VERSION ""

NS_ :

BS_:

BU_: SCM BC1 BC2 ECM PSC ABS Brakes__Drive_Axle_1 EPS IC GPS WCM VCM Seat_Control_1 ISC1 HCU IDT GMRS XM RH AUTON LHC CIM IMU BC3 IC2 EPC1 EPC2 EPC3 EPC4 BMC1 BMC2 APU2 APU1 SRVTOOL RHC RCM

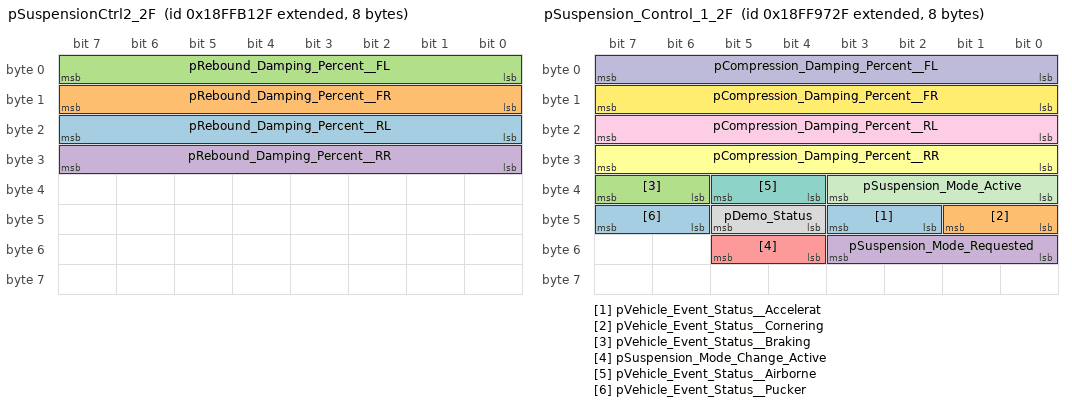
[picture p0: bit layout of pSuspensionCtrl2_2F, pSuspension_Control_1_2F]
BO_ 2566893871 pSuspensionCtrl2_2F: 8 SCM
 SG_ pRebound_Damping_Percent__RL : 16|8@1+ (0.4,0) [0|101.4] "%" Vector__XXX
 SG_ pRebound_Damping_Percent__FR : 8|8@1+ (0.4,0) [0|101.4] "%" Vector__XXX
 SG_ pRebound_Damping_Percent__FL : 0|8@1+ (0.4,0) [0|101.4] "%" Vector__XXX
 SG_ pRebound_Damping_Percent__RR : 24|8@1+ (0.4,0) [0|101.4] "%" Vector__XXX

BO_ 2566887215 pSuspension_Control_1_2F: 8 SCM
 SG_ pVehicle_Event_Status__Accelerat : 42|2@1+ (1,0) [0|3] "state" Vector__XXX
 SG_ pVehicle_Event_Status__Cornering : 40|2@1+ (1,0) [0|3] "state" Vector__XXX
 SG_ pVehicle_Event_Status__Braking : 38|2@1+ (1,0) [0|3] "state" Vector__XXX
 SG_ pSuspension_Mode_Requested : 48|4@1+ (1,0) [0|15] "state" Vector__XXX
 SG_ pSuspension_Mode_Change_Active : 52|2@1+ (1,0) [0|3] "state" Vector__XXX
 SG_ pCompression_Damping_Percent__RR : 24|8@1+ (0.4,0) [0|101.4] "%" Vector__XXX
 SG_ pVehicle_Event_Status__Airborne : 36|2@1+ (1,0) [0|3] "state" Vector__XXX
 SG_ pDemo_Status : 44|2@1+ (1,0) [0|3] "state" Vector__XXX
 SG_ pCompression_Damping_Percent__RL : 16|8@1+ (0.4,0) [0|101.4] "%" Vector__XXX
 SG_ pCompression_Damping_Percent__FL : 0|8@1+ (0.4,0) [0|101.4] "%" Vector__XXX
 SG_ pSuspension_Mode_Active : 32|4@1+ (1,0) [0|15] "state" Vector__XXX
 SG_ pCompression_Damping_Percent__FR : 8|8@1+ (0.4,0) [0|101.4] "%" Vector__XXX
 SG_ pVehicle_Event_Status__Pucker : 46|2@1+ (1,0) [0|3] "state" Vector__XXX

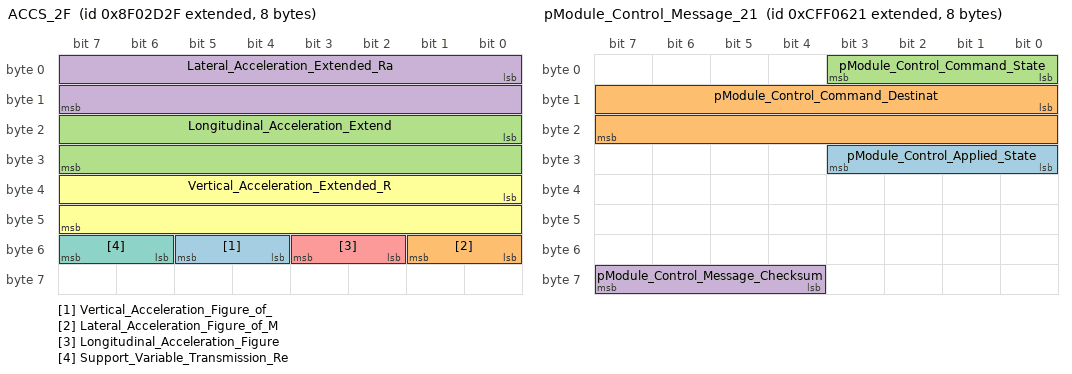
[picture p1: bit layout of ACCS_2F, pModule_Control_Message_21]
BO_ 2297441583 ACCS_2F: 8 SCM
 SG_ Vertical_Acceleration_Figure_of_ : 52|2@1+ (1,0) [0|3] "bit" Vector__XXX
 SG_ Lateral_Acceleration_Figure_of_M : 48|2@1+ (1,0) [0|3] "bit" Vector__XXX
 SG_ Longitudinal_Acceleration_Extend : 16|16@1+ (0.01,-320) [-320|974.36] "m/s2" Vector__XXX
 SG_ Lateral_Acceleration_Extended_Ra : 0|16@1+ (0.01,-320) [-320|974.36] "m/s2" Vector__XXX
 SG_ Longitudinal_Acceleration_Figure : 50|2@1+ (1,0) [0|3] "bit" Vector__XXX
 SG_ Vertical_Acceleration_Extended_R : 32|16@1+ (0.01,-320) [-320|974.36] "m/s2" Vector__XXX
 SG_ Support_Variable_Transmission_Re : 54|2@1+ (1,0) [0|3] "bit" Vector__XXX

BO_ 2365531183 pVMC_2F: 8 SCM
 SG_ pEPSReqMod : 8|8@1+ (1,0) [0|255] "state" Vector__XXX

BO_ 2633984545 pDSS_21: 8 BC1
 SG_ pHeated_Grip_Enable : 48|2@1+ (1,0) [0|3] "state" Vector__XXX
 SG_ pUser_PIN_Access_Status : 26|2@1+ (1,0) [0|3] "state" Vector__XXX
 SG_ pActive_Descent_Control_ADC_Stat : 0|2@1+ (1,0) [0|3] "state" Vector__XXX
 SG_ pCruise_Control_Set_Status : 24|2@1+ (1,0) [0|3] "state" Vector__XXX
 SG_ pTether_Switch_Status : 46|2@1+ (1,0) [0|3] "state" Vector__XXX
 SG_ pHigh_Beam_Indicator_Status : 8|2@1+ (1,0) [0|3] "state" Vector__XXX
 SG_ pLow_Fuel_Indicator_Status : 10|2@1+ (1,0) [0|3] "state" Vector__XXX
 SG_ pHeated_Grips_Percentage : 16|8@1+ (0.4,0) [0|101.4] "%" Vector__XXX
 SG_ pSide_Stand_Status : 36|2@1+ (1,0) [0|3] "state" Vector__XXX
 SG_ pTurf_Mode_Requested : 28|2@1+ (1,0) [0|3] "state" Vector__XXX
 SG_ pEngine_Idle_Shutdown_Timer : 54|10@1+ (1,0) [0|1023] "state" Vector__XXX
 SG_ Operator_Not_in_Operating_Statio : 38|2@1+ (1,0) [0|3] "state" Vector__XXX
 SG_ pAWD_Mode_Requested : 32|2@1+ (1,0) [0|3] "state" Vector__XXX
 SG_ pHeated_Grips_Up_Switch_Status : 50|2@1+ (1,0) [0|3] "state" Vector__XXX
 SG_ pTreadle_Neutral_Status : 2|2@1+ (1,0) [0|3] "state" Vector__XXX
 SG_ pHeated_Grips_Down_Switch_Status : 52|2@1+ (1,0) [0|3] "state" Vector__XXX
 SG_ pPark_Brake_Indicator_Status : 40|3@1+ (1,0) [0|7] "state" Vector__XXX
 SG_ pRWD_Mode_Requested : 30|2@1+ (1,0) [0|3] "state" Vector__XXX
 SG_ pSeat_Belt_Indicator_Status : 12|3@1+ (1,0) [0|7] "state" Vector__XXX
 SG_ pSecurity_Light_Immobilizer_Stat : 6|2@1+ (1,0) [0|3] "state" Vector__XXX
 SG_ ECU_Security_Status : 43|3@1+ (1,0) [0|7] "state" Vector__XXX
 SG_ pActive_Decent_Control_ADC_Mode_ : 34|2@1+ (1,0) [0|3] "state" Vector__XXX
 SG_ pTreadle_Reverse_Status : 4|2@1+ (1,0) [0|3] "state" Vector__XXX

BO_ 2349465377 SRASI_21: 8 BC1
 SG_ Static_Roll_Angle : 0|8@1+ (1,-125) [-125|380] "deg" Vector__XXX

BO_ 2365523489 pModule_Control_Message_21: 8 BC1
 SG_ pModule_Control_Applied_State : 24|4@1+ (1,0) [0|15] "state" Vector__XXX
 SG_ pModule_Control_Command_Destinat : 8|16@1+ (1,0) [0|65535] "count" Vector__XXX
 SG_ pModule_Control_Command_State : 0|4@1+ (1,0) [0|15] "state" Vector__XXX
 SG_ pModule_Control_Message_Checksum : 60|4@1+ (1,0) [0|15] "bit" Vector__XXX

BO_ 2633984656 pDSS_90: 8 BC2
 SG_ pHeated_Grip_Enable : 48|2@1+ (1,0) [0|3] "state" Vector__XXX
 SG_ pUser_PIN_Access_Status : 26|2@1+ (1,0) [0|3] "state" Vector__XXX
 SG_ pActive_Descent_Control_ADC_Stat : 0|2@1+ (1,0) [0|3] "state" Vector__XXX
 SG_ pCruise_Control_Set_Status : 24|2@1+ (1,0) [0|3] "state" Vector__XXX
 SG_ pTether_Switch_Status : 46|2@1+ (1,0) [0|3] "state" Vector__XXX
 SG_ pHigh_Beam_Indicator_Status : 8|2@1+ (1,0) [0|3] "state" Vector__XXX
 SG_ pLow_Fuel_Indicator_Status : 10|2@1+ (1,0) [0|3] "state" Vector__XXX
 SG_ pHeated_Grips_Percentage : 16|8@1+ (0.4,0) [0|101.4] "%" Vector__XXX
 SG_ pSide_Stand_Status : 36|2@1+ (1,0) [0|3] "state" Vector__XXX
 SG_ pTurf_Mode_Requested : 28|2@1+ (1,0) [0|3] "state" Vector__XXX
 SG_ pEngine_Idle_Shutdown_Timer : 54|10@1+ (1,0) [0|1023] "state" Vector__XXX
 SG_ Operator_Not_in_Operating_Statio : 38|2@1+ (1,0) [0|3] "state" Vector__XXX
 SG_ pAWD_Mode_Requested : 32|2@1+ (1,0) [0|3] "state" Vector__XXX
 SG_ pHeated_Grips_Up_Switch_Status : 50|2@1+ (1,0) [0|3] "state" Vector__XXX
 SG_ pTreadle_Neutral_Status : 2|2@1+ (1,0) [0|3] "state" Vector__XXX
 SG_ pHeated_Grips_Down_Switch_Status : 52|2@1+ (1,0) [0|3] "state" Vector__XXX
 SG_ pPark_Brake_Indicator_Status : 40|3@1+ (1,0) [0|7] "state" Vector__XXX
 SG_ pRWD_Mode_Requested : 30|2@1+ (1,0) [0|3] "state" Vector__XXX
 SG_ pSeat_Belt_Indicator_Status : 12|3@1+ (1,0) [0|7] "state" Vector__XXX
 SG_ pSecurity_Light_Immobilizer_Stat : 6|2@1+ (1,0) [0|3] "state" Vector__XXX
 SG_ ECU_Security_Status : 43|3@1+ (1,0) [0|7] "state" Vector__XXX
 SG_ pActive_Decent_Control_ADC_Mode_ : 34|2@1+ (1,0) [0|3] "state" Vector__XXX
 SG_ pTreadle_Reverse_Status : 4|2@1+ (1,0) [0|3] "state" Vector__XXX

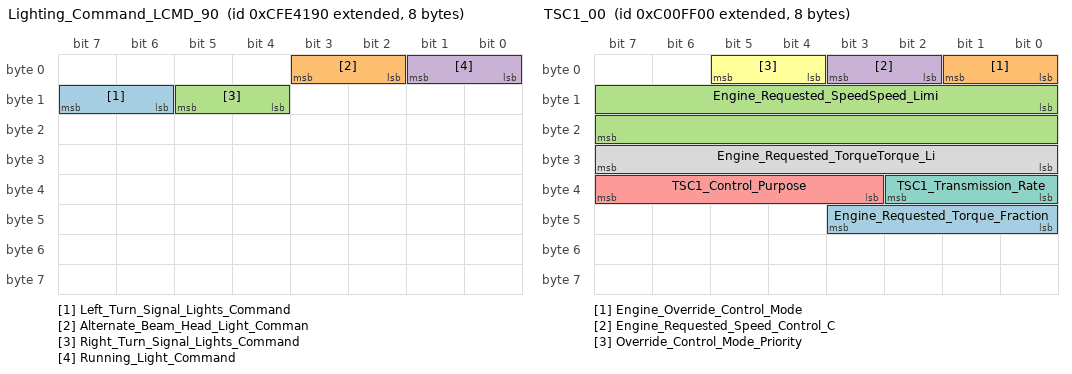
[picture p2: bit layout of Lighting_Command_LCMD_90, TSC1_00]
BO_ 2365473168 Lighting_Command_LCMD_90: 8 BC2
 SG_ Left_Turn_Signal_Lights_Command : 14|2@1+ (1,0) [0|3] "bit" Vector__XXX
 SG_ Alternate_Beam_Head_Light_Comman : 2|2@1+ (1,0) [0|3] "bit" Vector__XXX
 SG_ Right_Turn_Signal_Lights_Command : 12|2@1+ (1,0) [0|3] "bit" Vector__XXX
 SG_ Running_Light_Command : 0|2@1+ (1,0) [0|3] "bit" Vector__XXX

BO_ 2566860065 pISM_21: 8 BC1
 SG_ pSpecial_Msg_12 : 22|2@1+ (1,0) [0|3] "state" Vector__XXX
 SG_ pSpecial_Msg_28 : 54|2@1+ (1,0) [0|3] "state" Vector__XXX
 SG_ pSpecial_Msg_11 : 20|2@1+ (1,0) [0|3] "state" Vector__XXX
 SG_ pSpecial_Msg_26 : 50|2@1+ (1,0) [0|3] "state" Vector__XXX
 SG_ pSpecial_Msg_24 : 46|2@1+ (1,0) [0|3] "state" Vector__XXX
 SG_ pSpecial_Msg_21 : 40|2@1+ (1,0) [0|3] "state" Vector__XXX
 SG_ pSpecial_Msg_18 : 34|2@1+ (1,0) [0|3] "state" Vector__XXX
 SG_ pSpecial_Msg_19 : 36|2@1+ (1,0) [0|3] "state" Vector__XXX
 SG_ pSpecial_Msg_1_Riding_with_Brake : 0|2@1+ (1,0) [0|3] "state" Vector__XXX
 SG_ pSpecial_Msg_2_Regulator_Overhea : 2|2@1+ (1,0) [0|3] "state" Vector__XXX
 SG_ pSpecial_Msg_3_Regulator_Overhea : 4|2@1+ (1,0) [0|3] "state" Vector__XXX
 SG_ pSpecial_Msg_4_Regulator_Overhea : 6|2@1+ (1,0) [0|3] "state" Vector__XXX
 SG_ pSpecial_Msg_5_Engine_Warmup_Com : 8|2@1+ (1,0) [0|3] "state" Vector__XXX
 SG_ pSpecial_Msg_6_Engine_Knock__Mod : 10|2@1+ (1,0) [0|3] "state" Vector__XXX
 SG_ pSpecial_Msg_8_Low_Coolant_Warni : 14|2@1+ (1,0) [0|3] "state" Vector__XXX
 SG_ pSpecial_Msg_7_Engine_Knock__Mos : 12|2@1+ (1,0) [0|3] "state" Vector__XXX
 SG_ pSpecial_Msg_9_Transmission_Temp : 16|2@1+ (1,0) [0|3] "state" Vector__XXX
 SG_ pSpecial_Msg_10_Reverse_Speed_Li : 18|2@1+ (1,0) [0|3] "state" Vector__XXX
 SG_ pSpecial_Msg_13_Belt_Burn_Warnin : 24|2@1+ (1,0) [0|3] "state" Vector__XXX
 SG_ pSpecial_Msg_14_Park_Brake_Warni : 26|2@1+ (1,0) [0|3] "state" Vector__XXX
 SG_ pSpecial_Msg_15_TCM_Comm_Loss : 28|2@1+ (1,0) [0|3] "state" Vector__XXX
 SG_ pSpecial_Msg_16_TCM_Pump_Priming : 30|2@1+ (1,0) [0|3] "state" Vector__XXX
 SG_ pSpecial_Msg_17_Request_User_to_ : 32|2@1+ (1,0) [0|3] "state" Vector__XXX
 SG_ pSpecial_MSG_20_Fuel_Door_Open_E : 38|2@1+ (1,0) [0|3] "state" Vector__XXX
 SG_ pSpecial_MSG_22_Clutch_Overtemp : 42|2@1+ (1,0) [0|3] "state" Vector__XXX
 SG_ pSpecial_MSG_23_Exhaust_Valve_Ch : 44|2@1+ (1,0) [0|3] "state" Vector__XXX
 SG_ pSpecial_MSG_25_Engine_Idle_Shut : 48|2@1+ (1,0) [0|3] "state" Vector__XXX
 SG_ pSpecial_MSG_27_Overboost_Condit : 52|2@1+ (1,0) [0|3] "state" Vector__XXX
 SG_ pSpecial_Msg_31_Engine_Tip_Over_ : 60|2@1+ (1,0) [0|3] "state" Vector__XXX
 SG_ pSpecial_Msg_32_Engine_Tip_Over_ : 62|2@1+ (1,0) [0|3] "state" Vector__XXX

BO_ 2348875520 TSC1_00: 8 ECM
 SG_ Engine_Requested_Torque_Fraction : 40|4@1+ (0.125,0) [0|1] "%" Vector__XXX
 SG_ Engine_Override_Control_Mode : 0|2@1+ (1,0) [0|3] "bit" Vector__XXX
 SG_ Engine_Requested_SpeedSpeed_Limi : 8|16@1+ (0.125,0) [0|8191] "rpm" Vector__XXX
 SG_ Engine_Requested_Speed_Control_C : 2|2@1+ (1,0) [0|3] "bit" Vector__XXX
 SG_ TSC1_Control_Purpose : 35|5@1+ (1,0) [0|31] "bit" Vector__XXX
 SG_ Override_Control_Mode_Priority : 4|2@1+ (1,0) [0|3] "bit" Vector__XXX
 SG_ TSC1_Transmission_Rate : 32|3@1+ (1,0) [0|7] "bit" Vector__XXX
 SG_ Engine_Requested_TorqueTorque_Li : 24|8@1+ (1,-125) [-125|380] "%" Vector__XXX

BO_ 2364539648 EEC2_00: 8 ECM
 SG_ Accelerator_Pedal_Position_1 : 8|8@1+ (0.4,0) [0|101.4] "%" Vector__XXX

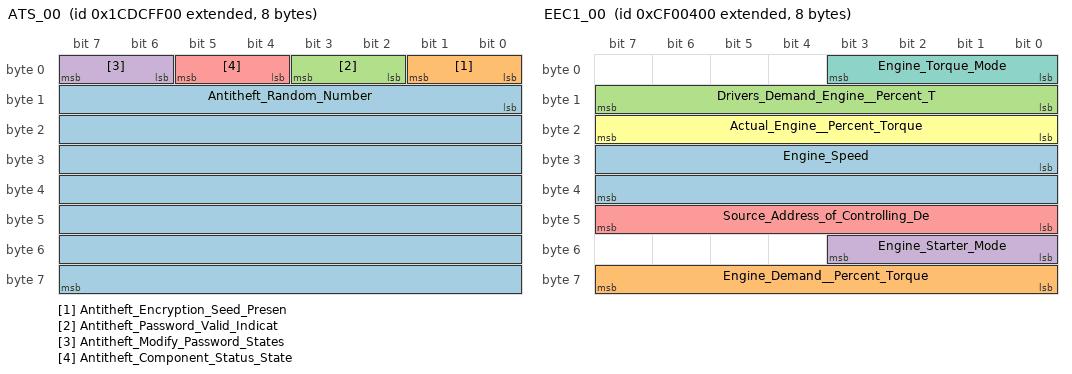
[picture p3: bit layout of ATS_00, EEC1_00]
BO_ 2631728896 ATS_00: 8 ECM
 SG_ Antitheft_Random_Number : 8|56@1+ (0,0) [0|-1] "ASCII" Vector__XXX
 SG_ Antitheft_Encryption_Seed_Presen : 0|2@1+ (1,0) [0|3] "bit" Vector__XXX
 SG_ Antitheft_Password_Valid_Indicat : 2|2@1+ (1,0) [0|3] "bit" Vector__XXX
 SG_ Antitheft_Modify_Password_States : 6|2@1+ (1,0) [0|3] "bit" Vector__XXX
 SG_ Antitheft_Component_Status_State : 4|2@1+ (1,0) [0|3] "bit" Vector__XXX

BO_ 2364539904 EEC1_00: 8 ECM
 SG_ Engine_Speed : 24|16@1+ (0.125,0) [0|8191] "rpm" Vector__XXX
 SG_ Engine_Demand__Percent_Torque : 56|8@1+ (1,-125) [-125|380] "%" Vector__XXX
 SG_ Drivers_Demand_Engine__Percent_T : 8|8@1+ (1,-125) [-125|380] "%" Vector__XXX
 SG_ Engine_Starter_Mode : 48|4@1+ (1,0) [0|15] "bit" Vector__XXX
 SG_ Source_Address_of_Controlling_De : 40|8@1+ (1,0) [0|255] "SA" Vector__XXX
 SG_ Actual_Engine__Percent_Torque : 16|8@1+ (1,-125) [-125|380] "%" Vector__XXX
 SG_ Engine_Torque_Mode : 0|4@1+ (1,0) [0|15] "bit" Vector__XXX

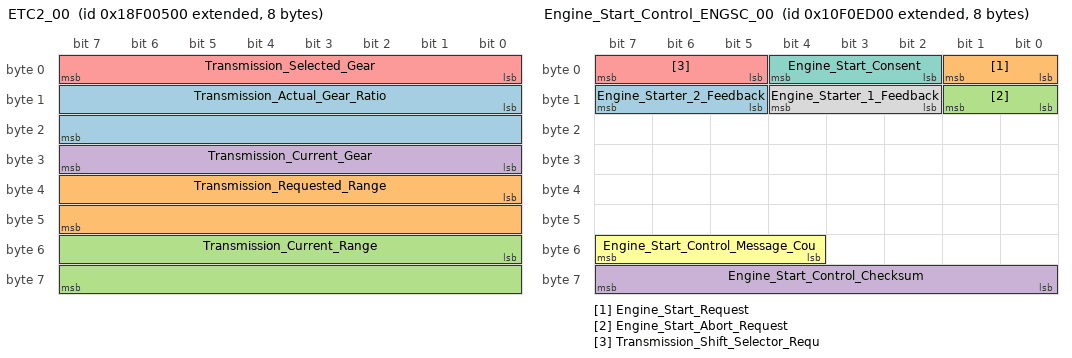
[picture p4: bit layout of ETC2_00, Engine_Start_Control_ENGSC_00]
BO_ 2565866752 ETC2_00: 8 ECM
 SG_ Transmission_Actual_Gear_Ratio : 8|16@1+ (0.001,0) [0|64.536] "Ratio" Vector__XXX
 SG_ Transmission_Requested_Range : 32|16@1+ (0,0) [0|-1] "ASCII" Vector__XXX
 SG_ Transmission_Current_Range : 48|16@1+ (0,0) [0|-1] "ASCII" Vector__XXX
 SG_ Transmission_Current_Gear : 24|8@1+ (1,-125) [-125|380] "gear_value" Vector__XXX
 SG_ Transmission_Selected_Gear : 0|8@1+ (1,-125) [-125|380] "gear_value" Vector__XXX

BO_ 2431708416 Engine_Start_Control_ENGSC_00: 8 ECM
 SG_ Engine_Starter_2_Feedback : 13|3@1+ (1,0) [0|7] "bit" Vector__XXX
 SG_ Engine_Start_Request : 0|2@1+ (1,0) [0|3] "bit" Vector__XXX
 SG_ Engine_Start_Abort_Request : 8|2@1+ (1,0) [0|3] "bit" Vector__XXX
 SG_ Engine_Start_Control_Checksum : 56|8@1+ (1,0) [0|255] "count" Vector__XXX
 SG_ Transmission_Shift_Selector_Requ : 5|3@1+ (1,0) [0|7] "bit" Vector__XXX
 SG_ Engine_Start_Control_Message_Cou : 52|4@1+ (1,0) [0|15] "bit" Vector__XXX
 SG_ Engine_Start_Consent : 2|3@1+ (1,0) [0|7] "bit" Vector__XXX
 SG_ Engine_Starter_1_Feedback : 10|3@1+ (1,0) [0|7] "bit" Vector__XXX

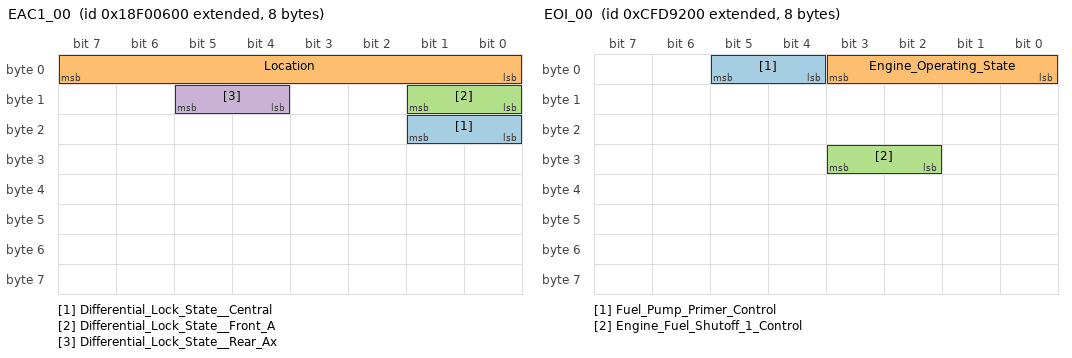
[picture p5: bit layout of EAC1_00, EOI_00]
BO_ 2565867008 EAC1_00: 8 ECM
 SG_ Differential_Lock_State__Central : 16|2@1+ (1,0) [0|3] "bit" Vector__XXX
 SG_ Location : 0|8@1+ (1,0) [0|255] "bit" Vector__XXX
 SG_ Differential_Lock_State__Front_A : 8|2@1+ (1,0) [0|3] "bit" Vector__XXX
 SG_ Differential_Lock_State__Rear_Ax : 12|2@1+ (1,0) [0|3] "bit" Vector__XXX

BO_ 2365428224 EOI_00: 8 ECM
 SG_ Fuel_Pump_Primer_Control : 4|2@1+ (1,0) [0|3] "bit" Vector__XXX
 SG_ Engine_Operating_State : 0|4@1+ (1,0) [0|15] "bit" Vector__XXX
 SG_ Engine_Fuel_Shutoff_1_Control : 26|2@1+ (1,0) [0|3] "bit" Vector__XXX

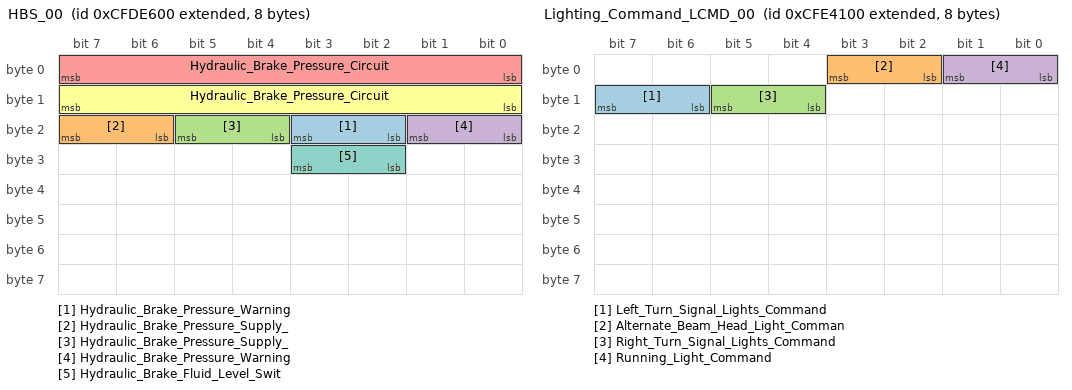
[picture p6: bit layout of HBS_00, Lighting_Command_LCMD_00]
BO_ 2365449728 HBS_00: 8 ECM
 SG_ Hydraulic_Brake_Pressure_Warning : 18|2@1+ (1,0) [0|3] "bit" Vector__XXX
 SG_ Hydraulic_Brake_Pressure_Supply_ : 22|2@1+ (1,0) [0|3] "bit" Vector__XXX
 SG_ Hydraulic_Brake_Pressure_Supply_ : 20|2@1+ (1,0) [0|3] "bit" Vector__XXX
 SG_ Hydraulic_Brake_Pressure_Warning : 16|2@1+ (1,0) [0|3] "bit" Vector__XXX
 SG_ Hydraulic_Brake_Pressure_Circuit : 0|8@1+ (100,0) [0|25599] "kPa" Vector__XXX
 SG_ Hydraulic_Brake_Pressure_Circuit : 8|8@1+ (100,0) [0|25599] "kPa" Vector__XXX
 SG_ Hydraulic_Brake_Fluid_Level_Swit : 26|2@1+ (1,0) [0|3] "bit" Vector__XXX

BO_ 2633883392 FWD_00: 8 ECM
 SG_ Front_Wheel_Drive_Actuator_Statu : 0|2@1+ (1,0) [0|3] "bit" Vector__XXX

BO_ 2566768128 CSA_00: 8 ECM
 SG_ Engine_Cold_Start_Fuel_Igniter_R : 26|2@1+ (1,0) [0|3] "bit" Vector__XXX
 SG_ Engine_Cold_Start_Fuel_Igniter_R : 24|2@1+ (1,0) [0|3] "bit" Vector__XXX

BO_ 2566832384 VDHR_00: 8 ECM
 SG_ Total_Vehicle_Distance_High_Reso : 0|32@1+ (5,0) [0|21474836479] "m" Vector__XXX
 SG_ Trip_Distance_High_Resolution : 0|32@1+ (5,0) [0|21474836479] "m" Vector__XXX

BO_ 2566834944 DM2_00: 42 ECM
 SG_ Protect_Lamp_Status : 0|2@1+ (1,0) [0|3] "" Vector__XXX
 SG_ Amber_Warning_Lamp_Status : 2|2@1+ (1,0) [0|3] "" Vector__XXX
 SG_ Red_Stop_Lamp_Status : 4|2@1+ (1,0) [0|3] "" Vector__XXX
 SG_ Malfunction_Indicator_Lamp_Statu : 6|2@1+ (1,0) [0|3] "" Vector__XXX
 SG_ Flash_Protect_Lamp : 8|2@1+ (1,0) [0|3] "" Vector__XXX
 SG_ Flash_Amber_Warning_Lamp_AWL : 10|2@1+ (1,0) [0|3] "" Vector__XXX
 SG_ Flash_Red_Stop_Lamp_RSL : 12|2@1+ (1,0) [0|3] "" Vector__XXX
 SG_ Flash_Malfunction_Indicator_Lamp : 14|2@1+ (1,0) [0|3] "" Vector__XXX
 SG_ DTC_1 : 16|32@1+ (1,0) [0|4294967295] "value" Vector__XXX
 SG_ DTC_2 : 48|32@1+ (1,0) [0|4294967295] "value" Vector__XXX
 SG_ DTC_3 : 80|32@1+ (1,0) [0|4294967295] "value" Vector__XXX
 SG_ DTC_4 : 112|32@1+ (1,0) [0|4294967295] "value" Vector__XXX
 SG_ DTC_5 : 144|32@1+ (1,0) [0|4294967295] "value" Vector__XXX
 SG_ DTC_6 : 176|32@1+ (1,0) [0|4294967295] "value" Vector__XXX
 SG_ DTC_7 : 208|32@1+ (1,0) [0|4294967295] "value" Vector__XXX
 SG_ DTC_8 : 240|32@1+ (1,0) [0|4294967295] "value" Vector__XXX
 SG_ DTC_9 : 272|32@1+ (1,0) [0|4294967295] "value" Vector__XXX
 SG_ DTC_10 : 304|32@1+ (1,0) [0|4294967295] "value" Vector__XXX

BO_ 2566819840 Engine_Torque_History_00: 0 ECM
 SG_ Engine_Peak_Torque_1 : 24|16@1+ (1,0) [0|65535] "Nm" Vector__XXX

BO_ 2566834688 DM1_00: 42 ECM
 SG_ Flash_Malfunction_Indicator_Lamp : 14|2@1+ (1,0) [0|3] "" Vector__XXX
 SG_ Malfunction_Indicator_Lamp_Statu : 6|2@1+ (1,0) [0|3] "" Vector__XXX
 SG_ Red_Stop_Lamp_Status : 4|2@1+ (1,0) [0|3] "" Vector__XXX
 SG_ Amber_Warning_Lamp_Status : 2|2@1+ (1,0) [0|3] "" Vector__XXX
 SG_ Flash_Red_Stop_Lamp_RSL : 12|2@1+ (1,0) [0|3] "" Vector__XXX
 SG_ Flash_Amber_Warning_Lamp_AWL : 10|2@1+ (1,0) [0|3] "" Vector__XXX
 SG_ Flash_Protect_Lamp : 8|2@1+ (1,0) [0|3] "" Vector__XXX
 SG_ Protect_Lamp_Status : 0|2@1+ (1,0) [0|3] "" Vector__XXX
 SG_ DTC_1 : 16|32@1+ (1,0) [0|4294967295] "value" Vector__XXX
 SG_ DTC_2 : 48|32@1+ (1,0) [0|4294967295] "value" Vector__XXX
 SG_ DTC_3 : 80|32@1+ (1,0) [0|4294967295] "value" Vector__XXX
 SG_ DTC_4 : 112|32@1+ (1,0) [0|4294967295] "value" Vector__XXX
 SG_ DTC_5 : 144|32@1+ (1,0) [0|4294967295] "value" Vector__XXX
 SG_ DTC_6 : 176|32@1+ (1,0) [0|4294967295] "value" Vector__XXX
 SG_ DTC_7 : 208|32@1+ (1,0) [0|4294967295] "value" Vector__XXX
 SG_ DTC_8 : 240|32@1+ (1,0) [0|4294967295] "value" Vector__XXX
 SG_ DTC_9 : 272|32@1+ (1,0) [0|4294967295] "value" Vector__XXX
 SG_ DTC_10 : 304|32@1+ (1,0) [0|4294967295] "value" Vector__XXX

BO_ 2633929216 Engine_Information_1_00: 0 ECM
 SG_ Engine_Fuel_Rack_Position : 24|8@1+ (0.4,0) [0|101.4] "%" Vector__XXX

BO_ 2566841344 SHUTDN_00: 8 ECM
 SG_ Engine_Wait_to_Start_Lamp : 24|2@1+ (1,0) [0|3] "bit" Vector__XXX

BO_ 2566825472 Intake_Manifold_Information_1_00: 8 ECM
 SG_ Engine_Turbocharger_1_Boost_Pres : 0|16@1+ (0.125,0) [0|8191] "kPa" Vector__XXX

BO_ 2365473024 Lighting_Command_LCMD_00: 8 ECM
 SG_ Left_Turn_Signal_Lights_Command : 14|2@1+ (1,0) [0|3] "bit" Vector__XXX
 SG_ Alternate_Beam_Head_Light_Comman : 2|2@1+ (1,0) [0|3] "bit" Vector__XXX
 SG_ Right_Turn_Signal_Lights_Command : 12|2@1+ (1,0) [0|3] "bit" Vector__XXX
 SG_ Running_Light_Command : 0|2@1+ (1,0) [0|3] "bit" Vector__XXX

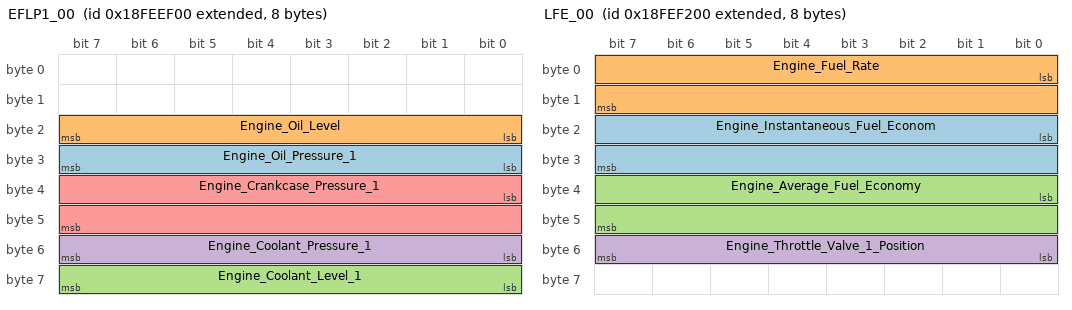
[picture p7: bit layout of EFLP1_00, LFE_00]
BO_ 2566844160 EFLP1_00: 8 ECM
 SG_ Engine_Oil_Pressure_1 : 24|8@1+ (4,0) [0|1023] "kPa" Vector__XXX
 SG_ Engine_Oil_Level : 16|8@1+ (0.4,0) [0|101.4] "%" Vector__XXX
 SG_ Engine_Coolant_Level_1 : 56|8@1+ (0.4,0) [0|101.4] "%" Vector__XXX
 SG_ Engine_Coolant_Pressure_1 : 48|8@1+ (2,0) [0|511] "kPa" Vector__XXX
 SG_ Engine_Crankcase_Pressure_1 : 32|16@1+ (0.0078125,-250) [-250|761] "kPa" Vector__XXX

BO_ 2566841600 HOURS_00: 8 ECM
 SG_ Engine_Total_Hours_of_Operation : 0|32@1+ (0.05,0) [0|214748363.8] "h" Vector__XXX
 SG_ Engine_Total_Revolutions : 32|32@1+ (1000,0) [0|4294967295999] "r" Vector__XXX

BO_ 2566844672 CCVS1_00: 8 ECM
 SG_ Cruise_Control_Set_Speed : 40|8@1+ (1,0) [0|255] "km/h" Vector__XXX
 SG_ Cruise_Control_Active : 24|2@1+ (1,0) [0|3] "bit" Vector__XXX
 SG_ Clutch_Switch : 30|2@1+ (1,0) [0|3] "bit" Vector__XXX
 SG_ Brake_Switch : 28|2@1+ (1,0) [0|3] "bit" Vector__XXX
 SG_ pCC_Message_Counter : 52|4@1+ (1,0) [0|15] "count" Vector__XXX
 SG_ Cruise_Control_Pause_Switch : 4|2@1+ (1,0) [0|3] "bit" Vector__XXX
 SG_ Cruise_Control_Set_Switch : 32|2@1+ (1,0) [0|3] "bit" Vector__XXX
 SG_ Two_Speed_Axle_Switch : 0|2@1+ (1,0) [0|3] "bit" Vector__XXX
 SG_ Cruise_Control_Enable_Switch : 26|2@1+ (1,0) [0|3] "bit" Vector__XXX
 SG_ pOdometer_Drive_Bit : 6|2@1+ (1,0) [0|3] "state" Vector__XXX
 SG_ pCC_Checksum : 56|8@1+ (1,0) [0|255] "" Vector__XXX
 SG_ WheelBased_Vehicle_Speed : 8|16@1+ (0.00390625,0) [0|255] "km/h" Vector__XXX
 SG_ Cruise_Control_Resume_Switch : 36|2@1+ (1,0) [0|3] "bit" Vector__XXX
 SG_ Cruise_Control_Accelerate_Switch : 38|2@1+ (1,0) [0|3] "bit" Vector__XXX
 SG_ pCruise_Enable_Status : 48|4@1+ (1,0) [0|15] "state" Vector__XXX
 SG_ Parking_Brake_Switch : 2|2@1+ (1,0) [0|3] "bit" Vector__XXX
 SG_ Cruise_Control_Coast_Decelerate_ : 34|2@1+ (1,0) [0|3] "bit" Vector__XXX

BO_ 2566844928 LFE_00: 8 ECM
 SG_ Engine_Instantaneous_Fuel_Econom : 16|16@1+ (0.001953125,0) [0|127] "km/L" Vector__XXX
 SG_ Engine_Fuel_Rate : 0|16@1+ (0.05,0) [0|3275.8] "l/h" Vector__XXX
 SG_ Engine_Average_Fuel_Economy : 32|16@1+ (0.001953125,0) [0|127] "km/L" Vector__XXX
 SG_ Engine_Throttle_Valve_1_Position : 48|8@1+ (0.4,0) [0|101.4] "%" Vector__XXX

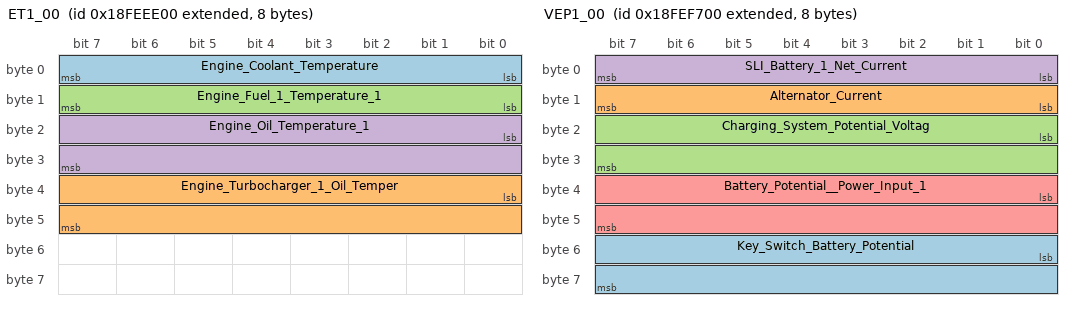
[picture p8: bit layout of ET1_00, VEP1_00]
BO_ 2566843904 ET1_00: 8 ECM
 SG_ Engine_Coolant_Temperature : 0|8@1+ (1,-40) [-40|295] "deg C" Vector__XXX
 SG_ Engine_Turbocharger_1_Oil_Temper : 32|16@1+ (0.03125,-273) [-273|2320] "deg C" Vector__XXX
 SG_ Engine_Fuel_1_Temperature_1 : 8|8@1+ (1,-40) [-40|295] "deg C" Vector__XXX
 SG_ Engine_Oil_Temperature_1 : 16|16@1+ (0.03125,-273) [-273|2320] "deg C" Vector__XXX

BO_ 2566846208 VEP1_00: 8 ECM
 SG_ Key_Switch_Battery_Potential : 48|16@1+ (0.05,0) [0|3275.8] "V" Vector__XXX
 SG_ Alternator_Current : 8|8@1+ (1,0) [0|255] "A" Vector__XXX
 SG_ Charging_System_Potential_Voltag : 16|16@1+ (0.05,0) [0|3275.8] "V" Vector__XXX
 SG_ SLI_Battery_1_Net_Current : 0|8@1+ (1,-125) [-125|380] "A" Vector__XXX
 SG_ Battery_Potential__Power_Input_1 : 32|16@1+ (0.05,0) [0|3275.8] "V" Vector__XXX

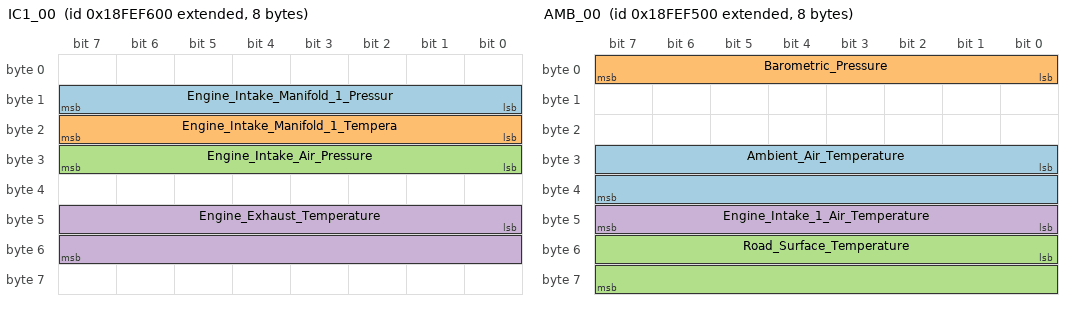
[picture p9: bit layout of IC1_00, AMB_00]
BO_ 2566845952 IC1_00: 8 ECM
 SG_ Engine_Intake_Manifold_1_Pressur : 8|8@1+ (2,0) [0|511] "kPa" Vector__XXX
 SG_ Engine_Intake_Manifold_1_Tempera : 16|8@1+ (1,-40) [-40|295] "deg C" Vector__XXX
 SG_ Engine_Intake_Air_Pressure : 24|8@1+ (2,0) [0|511] "kPa" Vector__XXX
 SG_ Engine_Exhaust_Temperature : 40|16@1+ (0.03125,-273) [-273|2320] "deg C" Vector__XXX

BO_ 2566847488 DD_00: 8 ECM
 SG_ Fuel_Level_1 : 8|8@1+ (0.4,0) [0|101.4] "%" Vector__XXX

BO_ 2566845696 AMB_00: 8 ECM
 SG_ Ambient_Air_Temperature : 24|16@1+ (0.03125,-273) [-273|2320] "deg C" Vector__XXX
 SG_ Barometric_Pressure : 0|8@1+ (0.5,0) [0|127] "kPa" Vector__XXX
 SG_ Road_Surface_Temperature : 48|16@1+ (0.03125,-273) [-273|2320] "deg C" Vector__XXX
 SG_ Engine_Intake_1_Air_Temperature : 40|8@1+ (1,-40) [-40|295] "deg C" Vector__XXX

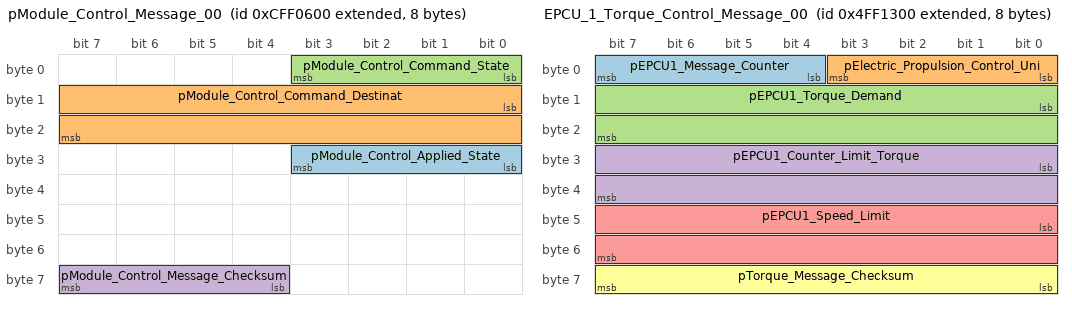
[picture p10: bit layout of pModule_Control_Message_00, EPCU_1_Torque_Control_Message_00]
BO_ 2365523456 pModule_Control_Message_00: 8 ECM
 SG_ pModule_Control_Applied_State : 24|4@1+ (1,0) [0|15] "state" Vector__XXX
 SG_ pModule_Control_Command_Destinat : 8|16@1+ (1,0) [0|65535] "count" Vector__XXX
 SG_ pModule_Control_Command_State : 0|4@1+ (1,0) [0|15] "state" Vector__XXX
 SG_ pModule_Control_Message_Checksum : 60|4@1+ (1,0) [0|15] "bit" Vector__XXX

BO_ 2231309056 EPCU_1_Torque_Control_Message_00: 8 ECM
 SG_ pEPCU1_Message_Counter : 4|4@1+ (1,0) [0|15] "count" Vector__XXX
 SG_ pElectric_Propulsion_Control_Uni : 0|4@1+ (1,0) [0|15] "state" Vector__XXX
 SG_ pEPCU1_Torque_Demand : 8|16@1+ (0.1,-3276.8) [-3276.8|9829.4] "Nm" Vector__XXX
 SG_ pEPCU1_Counter_Limit_Torque : 24|16@1+ (0.1,-3276.8) [-3276.8|9829.4] "Nm" Vector__XXX
 SG_ pEPCU1_Speed_Limit : 40|16@1+ (1,-32768) [-32768|98303] "rpm" Vector__XXX
 SG_ pTorque_Message_Checksum : 56|8@1+ (1,0) [0|255] "" Vector__XXX

BO_ 2365529088 pFan_Control_00: 8 ECM
 SG_ pRequested_Percent_Fan_1_Duty_Cy : 8|8@1+ (0.4,0) [0|101.4] "%" Vector__XXX
 SG_ pFan_1_Direction_Command : 0|2@1+ (1,0) [0|3] "state" Vector__XXX

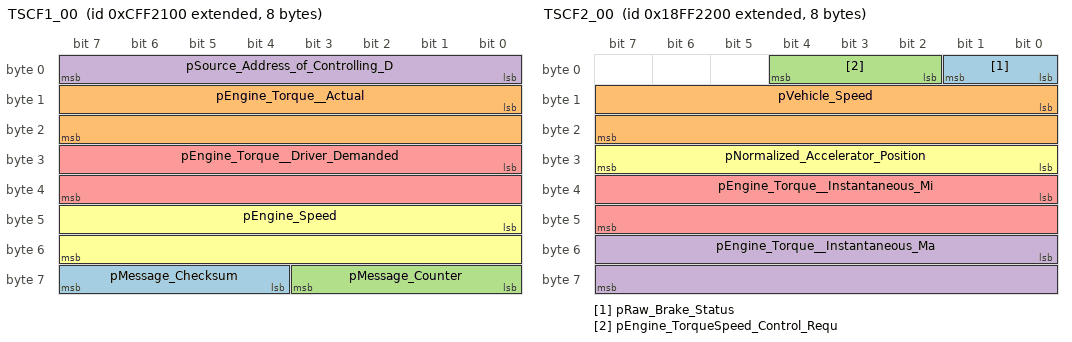
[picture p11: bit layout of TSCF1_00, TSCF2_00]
BO_ 2365530368 TSCF1_00: 8 ECM
 SG_ pMessage_Checksum : 60|4@1+ (1,0) [0|15] "count" Vector__XXX
 SG_ pEngine_Torque__Actual : 8|16@1+ (0.03125,-400) [-400|2447] "Nm" Vector__XXX
 SG_ pMessage_Counter : 56|4@1+ (1,0) [0|15] "count" Vector__XXX
 SG_ pSource_Address_of_Controlling_D : 0|8@1+ (1,0) [0|255] "SA" Vector__XXX
 SG_ pEngine_Torque__Driver_Demanded : 24|16@1+ (0.03125,-400) [-400|2447] "Nm" Vector__XXX
 SG_ pEngine_Speed : 40|16@1+ (1,0) [0|65535] "rpm" Vector__XXX

BO_ 2566857216 TSCF2_00: 8 ECM
 SG_ pRaw_Brake_Status : 0|2@1+ (1,0) [0|3] "state" Vector__XXX
 SG_ pVehicle_Speed : 8|16@1+ (0.00390625,0) [0|255] "km/h" Vector__XXX
 SG_ pEngine_TorqueSpeed_Control_Requ : 2|3@1+ (1,0) [0|7] "state" Vector__XXX
 SG_ pEngine_Torque__Instantaneous_Ma : 48|16@1+ (0.03125,-400) [-400|2447] "Nm" Vector__XXX
 SG_ pEngine_Torque__Instantaneous_Mi : 32|16@1+ (0.03125,-400) [-400|2447] "Nm" Vector__XXX
 SG_ pNormalized_Accelerator_Position : 24|8@1+ (0.4,0) [0|101.4] "%" Vector__XXX

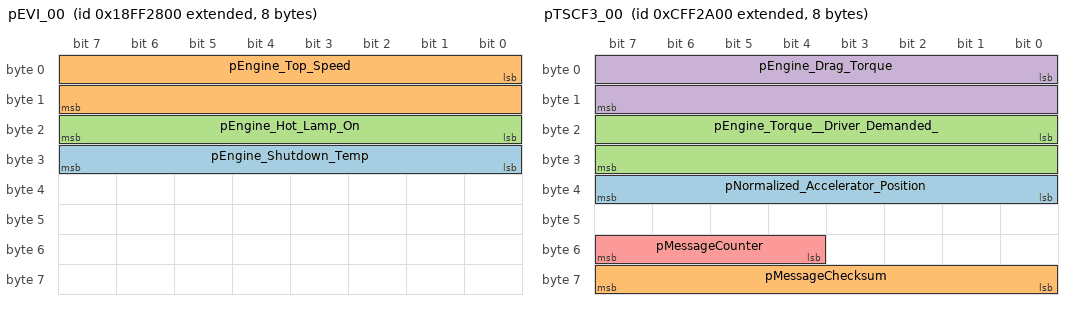
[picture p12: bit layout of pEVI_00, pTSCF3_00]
BO_ 2566858752 pEVI_00: 8 ECM
 SG_ pEngine_Shutdown_Temp : 24|8@1+ (1,0) [0|255] "deg C" Vector__XXX
 SG_ pEngine_Top_Speed : 0|16@1+ (1,0) [0|65535] "rpm" Vector__XXX
 SG_ pEngine_Hot_Lamp_On : 16|8@1+ (1,0) [0|255] "deg C" Vector__XXX

BO_ 2365532672 pTSCF3_00: 8 ECM
 SG_ pNormalized_Accelerator_Position : 32|8@1+ (0.4,0) [0|101.4] "%" Vector__XXX
 SG_ pMessageChecksum : 56|8@1+ (1,0) [0|255] "count" Vector__XXX
 SG_ pEngine_Torque__Driver_Demanded_ : 16|16@1+ (0.03125,-400) [-400|2447] "Nm" Vector__XXX
 SG_ pEngine_Drag_Torque : 0|16@1+ (0.03125,-400) [-400|2447] "Nm" Vector__XXX
 SG_ pMessageCounter : 52|4@1+ (1,0) [0|15] "count" Vector__XXX

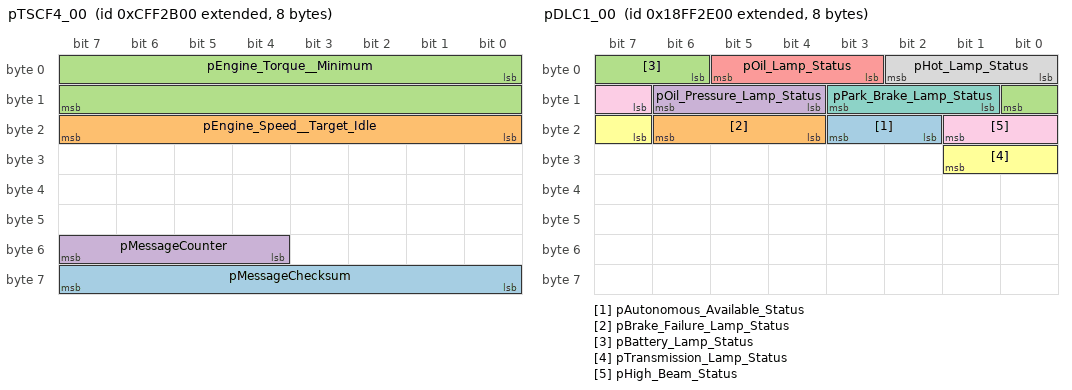
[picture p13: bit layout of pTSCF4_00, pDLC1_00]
BO_ 2365532928 pTSCF4_00: 8 ECM
 SG_ pMessageChecksum : 56|8@1+ (1,0) [0|255] "count" Vector__XXX
 SG_ pEngine_Speed__Target_Idle : 16|8@1+ (10,0) [0|2559] "rpm" Vector__XXX
 SG_ pEngine_Torque__Minimum : 0|16@1+ (0.03125,-400) [-400|2447] "Nm" Vector__XXX
 SG_ pMessageCounter : 52|4@1+ (1,0) [0|15] "count" Vector__XXX

BO_ 2566860032 pISM_00: 8 ECM
 SG_ pSpecial_Msg_12 : 22|2@1+ (1,0) [0|3] "state" Vector__XXX
 SG_ pSpecial_Msg_28 : 54|2@1+ (1,0) [0|3] "state" Vector__XXX
 SG_ pSpecial_Msg_11 : 20|2@1+ (1,0) [0|3] "state" Vector__XXX
 SG_ pSpecial_Msg_26 : 50|2@1+ (1,0) [0|3] "state" Vector__XXX
 SG_ pSpecial_Msg_24 : 46|2@1+ (1,0) [0|3] "state" Vector__XXX
 SG_ pSpecial_Msg_21 : 40|2@1+ (1,0) [0|3] "state" Vector__XXX
 SG_ pSpecial_Msg_18 : 34|2@1+ (1,0) [0|3] "state" Vector__XXX
 SG_ pSpecial_Msg_19 : 36|2@1+ (1,0) [0|3] "state" Vector__XXX
 SG_ pSpecial_Msg_1_Riding_with_Brake : 0|2@1+ (1,0) [0|3] "state" Vector__XXX
 SG_ pSpecial_Msg_2_Regulator_Overhea : 2|2@1+ (1,0) [0|3] "state" Vector__XXX
 SG_ pSpecial_Msg_3_Regulator_Overhea : 4|2@1+ (1,0) [0|3] "state" Vector__XXX
 SG_ pSpecial_Msg_4_Regulator_Overhea : 6|2@1+ (1,0) [0|3] "state" Vector__XXX
 SG_ pSpecial_Msg_5_Engine_Warmup_Com : 8|2@1+ (1,0) [0|3] "state" Vector__XXX
 SG_ pSpecial_Msg_6_Engine_Knock__Mod : 10|2@1+ (1,0) [0|3] "state" Vector__XXX
 SG_ pSpecial_Msg_8_Low_Coolant_Warni : 14|2@1+ (1,0) [0|3] "state" Vector__XXX
 SG_ pSpecial_Msg_7_Engine_Knock__Mos : 12|2@1+ (1,0) [0|3] "state" Vector__XXX
 SG_ pSpecial_Msg_9_Transmission_Temp : 16|2@1+ (1,0) [0|3] "state" Vector__XXX
 SG_ pSpecial_Msg_10_Reverse_Speed_Li : 18|2@1+ (1,0) [0|3] "state" Vector__XXX
 SG_ pSpecial_Msg_13_Belt_Burn_Warnin : 24|2@1+ (1,0) [0|3] "state" Vector__XXX
 SG_ pSpecial_Msg_14_Park_Brake_Warni : 26|2@1+ (1,0) [0|3] "state" Vector__XXX
 SG_ pSpecial_Msg_15_TCM_Comm_Loss : 28|2@1+ (1,0) [0|3] "state" Vector__XXX
 SG_ pSpecial_Msg_16_TCM_Pump_Priming : 30|2@1+ (1,0) [0|3] "state" Vector__XXX
 SG_ pSpecial_Msg_17_Request_User_to_ : 32|2@1+ (1,0) [0|3] "state" Vector__XXX
 SG_ pSpecial_MSG_20_Fuel_Door_Open_E : 38|2@1+ (1,0) [0|3] "state" Vector__XXX
 SG_ pSpecial_MSG_22_Clutch_Overtemp : 42|2@1+ (1,0) [0|3] "state" Vector__XXX
 SG_ pSpecial_MSG_23_Exhaust_Valve_Ch : 44|2@1+ (1,0) [0|3] "state" Vector__XXX
 SG_ pSpecial_MSG_25_Engine_Idle_Shut : 48|2@1+ (1,0) [0|3] "state" Vector__XXX
 SG_ pSpecial_MSG_27_Overboost_Condit : 52|2@1+ (1,0) [0|3] "state" Vector__XXX
 SG_ pSpecial_Msg_31_Engine_Tip_Over_ : 60|2@1+ (1,0) [0|3] "state" Vector__XXX
 SG_ pSpecial_Msg_32_Engine_Tip_Over_ : 62|2@1+ (1,0) [0|3] "state" Vector__XXX

BO_ 2566860288 pDLC1_00: 8 ECM
 SG_ pAutonomous_Available_Status : 18|2@1+ (1,0) [0|3] "state" Vector__XXX
 SG_ pBrake_Failure_Lamp_Status : 20|3@1+ (1,0) [0|7] "state" Vector__XXX
 SG_ pBattery_Lamp_Status : 6|3@1+ (1,0) [0|7] "state" Vector__XXX
 SG_ pOil_Pressure_Lamp_Status : 12|3@1+ (1,0) [0|7] "state" Vector__XXX
 SG_ pOil_Lamp_Status : 3|3@1+ (1,0) [0|7] "state" Vector__XXX
 SG_ pTransmission_Lamp_Status : 23|3@1+ (1,0) [0|7] "state" Vector__XXX
 SG_ pPark_Brake_Lamp_Status : 9|3@1+ (1,0) [0|7] "state" Vector__XXX
 SG_ pHot_Lamp_Status : 0|3@1+ (1,0) [0|7] "state" Vector__XXX
 SG_ pHigh_Beam_Status : 15|3@1+ (1,0) [0|7] "state" Vector__XXX

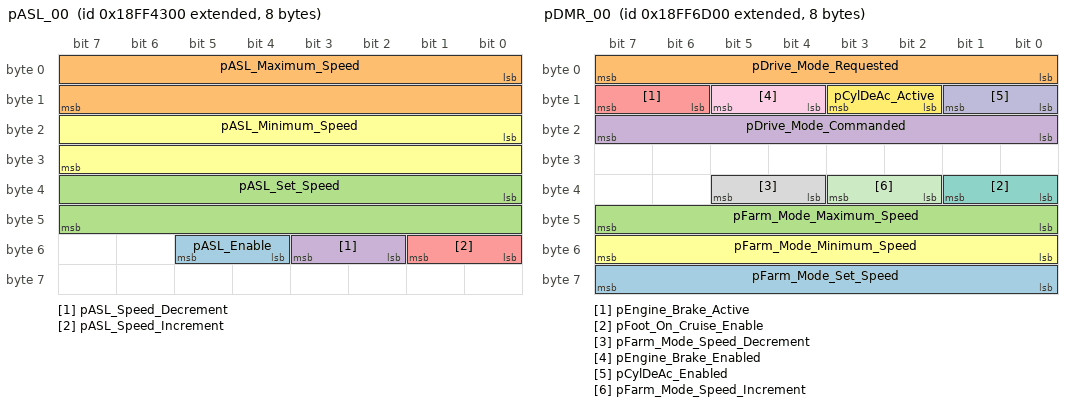
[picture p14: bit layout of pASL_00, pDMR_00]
BO_ 2566865664 pASL_00: 8 ECM
 SG_ pASL_Enable : 52|2@1+ (1,0) [0|3] "state" Vector__XXX
 SG_ pASL_Maximum_Speed : 0|16@1+ (0.00390625,0) [0|255] "km/h" Vector__XXX
 SG_ pASL_Set_Speed : 32|16@1+ (0.00390625,0) [0|255] "km/h" Vector__XXX
 SG_ pASL_Speed_Decrement : 50|2@1+ (1,0) [0|3] "state" Vector__XXX
 SG_ pASL_Speed_Increment : 48|2@1+ (1,0) [0|3] "state" Vector__XXX
 SG_ pASL_Minimum_Speed : 16|16@1+ (0.00390625,0) [0|255] "km/h" Vector__XXX

BO_ 2432656640 pOSS1_00: 8 ECM
 SG_ Key_Fob_Unlock_Button_Status : 30|2@1+ (1,0) [0|3] "state" Vector__XXX
 SG_ Homelink_2 : 44|2@1+ (1,0) [0|3] "state" Vector__XXX
 SG_ Side_Stand_Switch : 56|2@1+ (1,0) [0|3] "state" Vector__XXX
 SG_ Key_Fob_Lock_Button_Status : 32|2@1+ (1,0) [0|3] "state" Vector__XXX
 SG_ Windshield__2_Down : 50|2@1+ (1,0) [0|3] "state" Vector__XXX
 SG_ Turn__3_Cancel : 14|2@1+ (1,0) [0|3] "state" Vector__XXX
 SG_ Reverse : 40|2@1+ (1,0) [0|3] "state" Vector__XXX
 SG_ Hazard : 16|2@1+ (1,0) [0|3] "state" Vector__XXX
 SG_ Homelink_1 : 42|2@1+ (1,0) [0|3] "state" Vector__XXX
 SG_ Windshield__1_Up : 48|2@1+ (1,0) [0|3] "state" Vector__XXX
 SG_ Front_Brake_Switch : 52|2@1+ (1,0) [0|3] "state" Vector__XXX
 SG_ Instrument_Cluster_Control__2 : 2|2@1+ (1,0) [0|3] "state" Vector__XXX
 SG_ Chassis_Unlock_Button_Status : 34|2@1+ (1,0) [0|3] "state" Vector__XXX
 SG_ Power_Button : 58|2@1+ (1,0) [0|3] "state" Vector__XXX
 SG_ RunStop_Switch : 38|2@1+ (1,0) [0|3] "state" Vector__XXX
 SG_ Headlamp__2_High : 6|2@1+ (1,0) [0|3] "state" Vector__XXX
 SG_ Instrument_Cluster_Control__1 : 0|2@1+ (1,0) [0|3] "state" Vector__XXX
 SG_ Clutch_Switch : 54|2@1+ (1,0) [0|3] "state" Vector__XXX
 SG_ Start : 26|2@1+ (1,0) [0|3] "state" Vector__XXX
 SG_ Headlamp__3_Driving : 8|2@1+ (1,0) [0|3] "state" Vector__XXX
 SG_ Cruise__2_Set : 20|2@1+ (1,0) [0|3] "state" Vector__XXX
 SG_ Windshield_Wiper : 36|2@1+ (1,0) [0|3] "state" Vector__XXX
 SG_ Fog : 28|2@1+ (1,0) [0|3] "state" Vector__XXX
 SG_ Cruise__3_Accel : 22|2@1+ (1,0) [0|3] "state" Vector__XXX
 SG_ Horn : 24|2@1+ (1,0) [0|3] "state" Vector__XXX
 SG_ Turn__2_Right : 12|2@1+ (1,0) [0|3] "state" Vector__XXX
 SG_ Cruise__1_On : 18|2@1+ (1,0) [0|3] "state" Vector__XXX
 SG_ Turn__1_Left : 10|2@1+ (1,0) [0|3] "state" Vector__XXX
 SG_ Throttle_Safety_Switch__1 : 46|2@1+ (1,0) [0|3] "state" Vector__XXX
 SG_ Headlamp__1_Low : 4|2@1+ (1,0) [0|3] "state" Vector__XXX
 SG_ Chassis_Lock_Switch_Status : 62|2@1+ (1,0) [0|3] "unknown" Vector__XXX
 SG_ Fuel_Door_Unlock_Button_Status : 60|2@1+ (1,0) [0|3] "state" Vector__XXX

BO_ 2566876416 pDMR_00: 8 ECM
 SG_ pFarm_Mode_Set_Speed : 56|8@1+ (0.4,0) [0|101.4] "km/h" Vector__XXX
 SG_ pDrive_Mode_Requested : 0|8@1+ (1,0) [0|255] "ASCII" Vector__XXX
 SG_ pFarm_Mode_Maximum_Speed : 40|8@1+ (0.4,0) [0|101.4] "km/h" Vector__XXX
 SG_ pDrive_Mode_Commanded : 16|8@1+ (1,0) [0|255] "ASCII" Vector__XXX
 SG_ pEngine_Brake_Active : 14|2@1+ (1,0) [0|3] "state" Vector__XXX
 SG_ pFarm_Mode_Minimum_Speed : 48|8@1+ (0.4,0) [0|101.4] "km/h" Vector__XXX
 SG_ pFoot_On_Cruise_Enable : 32|2@1+ (1,0) [0|3] "state" Vector__XXX
 SG_ pFarm_Mode_Speed_Decrement : 36|2@1+ (0,0) [0|-1] "state" Vector__XXX
 SG_ pEngine_Brake_Enabled : 12|2@1+ (1,0) [0|3] "state" Vector__XXX
 SG_ pCylDeAc_Enabled : 8|2@1+ (1,0) [0|3] "state" Vector__XXX
 SG_ pFarm_Mode_Speed_Increment : 34|2@1+ (1,0) [0|3] "state" Vector__XXX
 SG_ pCylDeAc_Active : 10|2@1+ (1,0) [0|3] "state" Vector__XXX

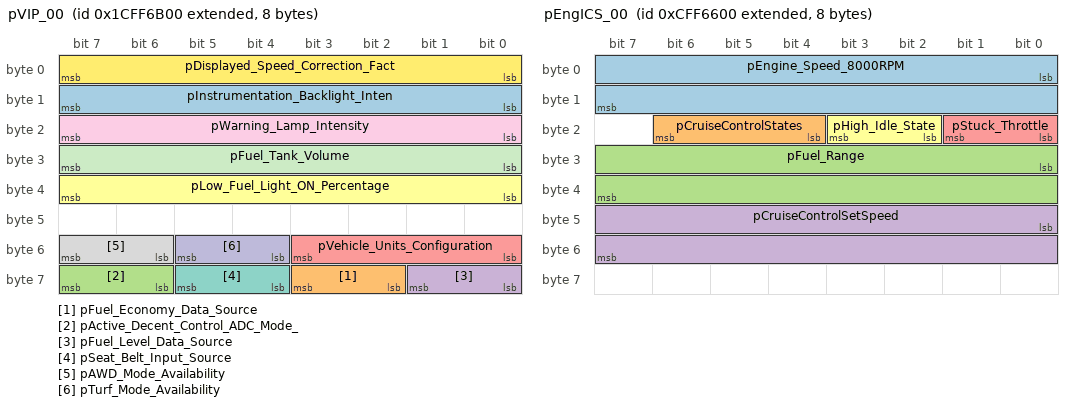
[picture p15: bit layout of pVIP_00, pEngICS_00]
BO_ 2633984768 pVIP_00: 8 ECM
 SG_ pInstrumentation_Backlight_Inten : 8|8@1+ (0.4,0) [0|101.4] "%" Vector__XXX
 SG_ pFuel_Economy_Data_Source : 58|2@1+ (1,0) [0|3] "state" Vector__XXX
 SG_ pActive_Decent_Control_ADC_Mode_ : 62|2@1+ (1,0) [0|3] "state" Vector__XXX
 SG_ pFuel_Level_Data_Source : 56|2@1+ (1,0) [0|3] "state" Vector__XXX
 SG_ pVehicle_Units_Configuration : 48|4@1+ (1,0) [0|15] "state" Vector__XXX
 SG_ pLow_Fuel_Light_ON_Percentage : 32|8@1+ (0.4,0) [0|101.4] "%" Vector__XXX
 SG_ pSeat_Belt_Input_Source : 60|2@1+ (1,0) [0|3] "state" Vector__XXX
 SG_ pAWD_Mode_Availability : 54|2@1+ (1,0) [0|3] "state" Vector__XXX
 SG_ pWarning_Lamp_Intensity : 16|8@1+ (0.4,0) [0|101.4] "%" Vector__XXX
 SG_ pTurf_Mode_Availability : 52|2@1+ (1,0) [0|3] "state" Vector__XXX
 SG_ pFuel_Tank_Volume : 24|8@1+ (0.5,0) [0|127] "l" Vector__XXX
 SG_ pDisplayed_Speed_Correction_Fact : 0|8@1+ (0.8,-100) [-100|303.8] "%" Vector__XXX

BO_ 2432658432 pOSS2_00: 8 ECM
 SG_ pFOCC_Checksum : 56|8@1+ (1,0) [0|255] "" Vector__XXX
 SG_ Drive_Mode__4 : 6|2@1+ (1,0) [0|3] "state" Vector__XXX
 SG_ Drive_Mode__2 : 2|2@1+ (1,0) [0|3] "state" Vector__XXX
 SG_ pFOCC_Message_Counter : 48|4@1+ (1,0) [0|15] "" Vector__XXX
 SG_ Drivers_Net_Engagement : 12|2@1+ (1,0) [0|3] "state" Vector__XXX
 SG_ Foot_On_Cruise_Control_Switch : 22|2@1+ (1,0) [0|3] "state" Vector__XXX
 SG_ Drive_Mode__1 : 0|2@1+ (1,0) [0|3] "state" Vector__XXX
 SG_ Momentary_Driveline_Left_Press : 24|2@1+ (1,0) [0|3] "state" Vector__XXX
 SG_ CylDeAc_Enable : 32|2@1+ (1,0) [0|3] "state" Vector__XXX
 SG_ Work_Group_Lock_Switch : 16|2@1+ (1,0) [0|3] "state" Vector__XXX
 SG_ Drivers_Seatbelt_Engagement : 10|2@1+ (1,0) [0|3] "state" Vector__XXX
 SG_ Drive_Mode__3 : 4|2@1+ (1,0) [0|3] "state" Vector__XXX
 SG_ Work_Mode_Switch : 20|2@1+ (1,0) [0|3] "state" Vector__XXX
 SG_ Momentary_Driveline_Right_Press : 26|2@1+ (1,0) [0|3] "state" Vector__XXX
 SG_ PTO_Mode_Switch_RPM_Control : 8|2@1+ (1,0) [0|3] "state" Vector__XXX
 SG_ Operator_Presence_Switch : 18|2@1+ (1,0) [0|3] "state" Vector__XXX
 SG_ Tilt_Lock_Switch : 14|2@1+ (1,0) [0|3] "state" Vector__XXX
 SG_ Engine_Brake_Enable : 34|2@1+ (1,0) [0|3] "state" Vector__XXX
 SG_ Accessory_Relay : 28|2@1+ (1,0) [0|3] "state" Vector__XXX

BO_ 2633984512 pDSS_00: 8 ECM
 SG_ pHeated_Grip_Enable : 48|2@1+ (1,0) [0|3] "state" Vector__XXX
 SG_ pUser_PIN_Access_Status : 26|2@1+ (1,0) [0|3] "state" Vector__XXX
 SG_ pActive_Descent_Control_ADC_Stat : 0|2@1+ (1,0) [0|3] "state" Vector__XXX
 SG_ pCruise_Control_Set_Status : 24|2@1+ (1,0) [0|3] "state" Vector__XXX
 SG_ pTether_Switch_Status : 46|2@1+ (1,0) [0|3] "state" Vector__XXX
 SG_ pHigh_Beam_Indicator_Status : 8|2@1+ (1,0) [0|3] "state" Vector__XXX
 SG_ pLow_Fuel_Indicator_Status : 10|2@1+ (1,0) [0|3] "state" Vector__XXX
 SG_ pHeated_Grips_Percentage : 16|8@1+ (0.4,0) [0|101.4] "%" Vector__XXX
 SG_ pSide_Stand_Status : 36|2@1+ (1,0) [0|3] "state" Vector__XXX
 SG_ pTurf_Mode_Requested : 28|2@1+ (1,0) [0|3] "state" Vector__XXX
 SG_ pEngine_Idle_Shutdown_Timer : 54|10@1+ (1,0) [0|1023] "state" Vector__XXX
 SG_ Operator_Not_in_Operating_Statio : 38|2@1+ (1,0) [0|3] "state" Vector__XXX
 SG_ pAWD_Mode_Requested : 32|2@1+ (1,0) [0|3] "state" Vector__XXX
 SG_ pHeated_Grips_Up_Switch_Status : 50|2@1+ (1,0) [0|3] "state" Vector__XXX
 SG_ pTreadle_Neutral_Status : 2|2@1+ (1,0) [0|3] "state" Vector__XXX
 SG_ pHeated_Grips_Down_Switch_Status : 52|2@1+ (1,0) [0|3] "state" Vector__XXX
 SG_ pPark_Brake_Indicator_Status : 40|3@1+ (1,0) [0|7] "state" Vector__XXX
 SG_ pRWD_Mode_Requested : 30|2@1+ (1,0) [0|3] "state" Vector__XXX
 SG_ pSeat_Belt_Indicator_Status : 12|3@1+ (1,0) [0|7] "state" Vector__XXX
 SG_ pSecurity_Light_Immobilizer_Stat : 6|2@1+ (1,0) [0|3] "state" Vector__XXX
 SG_ ECU_Security_Status : 43|3@1+ (1,0) [0|7] "state" Vector__XXX
 SG_ pActive_Decent_Control_ADC_Mode_ : 34|2@1+ (1,0) [0|3] "state" Vector__XXX
 SG_ pTreadle_Reverse_Status : 4|2@1+ (1,0) [0|3] "state" Vector__XXX

BO_ 2566875136 pFuelTyp_00: 8 ECM
 SG_ pFuel_Type_Selected : 0|4@1+ (1,0) [0|15] "state" Vector__XXX
 SG_ pFuel_Type_Sensor : 8|8@1+ (0.4,0) [0|101.4] "%" Vector__XXX

BO_ 2365548032 pEngICS_00: 8 ECM
 SG_ pEngine_Speed_8000RPM : 0|16@1+ (1,0) [0|65535] "rpm" Vector__XXX
 SG_ pCruiseControlStates : 20|3@1+ (1,0) [0|7] "state" Vector__XXX
 SG_ pFuel_Range : 24|16@1+ (1,0) [0|65535] "km" Vector__XXX
 SG_ pCruiseControlSetSpeed : 40|16@1+ (0.0078125,0) [0|511] "km/h" Vector__XXX
 SG_ pStuck_Throttle : 16|2@1+ (1,0) [0|3] "state" Vector__XXX
 SG_ pHigh_Idle_State : 18|2@1+ (1,0) [0|3] "state" Vector__XXX

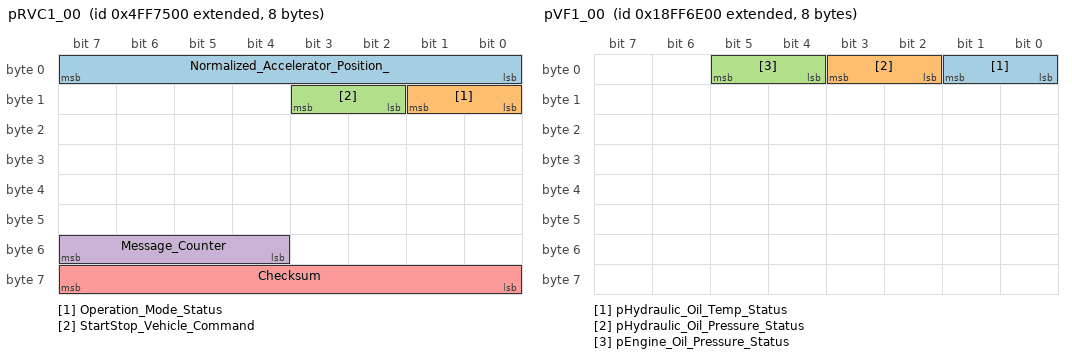
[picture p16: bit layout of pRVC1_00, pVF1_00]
BO_ 2231334144 pRVC1_00: 8 ECM
 SG_ Normalized_Accelerator_Position_ : 0|8@1+ (0.4,0) [0|101.4] "" Vector__XXX
 SG_ Operation_Mode_Status : 8|2@1+ (1,0) [0|3] "state" Vector__XXX
 SG_ StartStop_Vehicle_Command : 10|2@1+ (1,0) [0|3] "" Vector__XXX
 SG_ Message_Counter : 52|4@1+ (1,0) [0|15] "" Vector__XXX
 SG_ Checksum : 56|8@1+ (1,0) [0|255] "" Vector__XXX

BO_ 2566876672 pVF1_00: 8 ECM
 SG_ pHydraulic_Oil_Temp_Status : 0|2@1+ (1,0) [0|3] "state" Vector__XXX
 SG_ pHydraulic_Oil_Pressure_Status : 2|2@1+ (1,0) [0|3] "state" Vector__XXX
 SG_ pEngine_Oil_Pressure_Status : 4|2@1+ (1,0) [0|3] "state" Vector__XXX

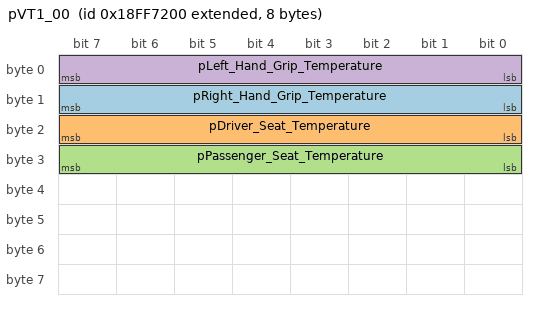
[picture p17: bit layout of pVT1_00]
BO_ 2566877696 pVT1_00: 8 ECM
 SG_ pRight_Hand_Grip_Temperature : 8|8@1+ (1,-40) [-40|295] "deg C" Vector__XXX
 SG_ pDriver_Seat_Temperature : 16|8@1+ (1,-40) [-40|295] "deg C" Vector__XXX
 SG_ pPassenger_Seat_Temperature : 24|8@1+ (1,-40) [-40|295] "deg C" Vector__XXX
 SG_ pLeft_Hand_Grip_Temperature : 0|8@1+ (1,-40) [-40|295] "deg C" Vector__XXX

CM_ BO_ 2566893871 "Name: pSuspensionCtrl2
Description: Parsed from -014. ";
CM_ SG_ 2566893871 pRebound_Damping_Percent__RL "Description: The calculated percent of full damping range commanded to the rear left shock rebound valve.

Could not parse SPN data type, please add:Type: Calculated
Parsed from -014. ";
CM_ SG_ 2566893871 pRebound_Damping_Percent__FR "Description: The calculated percent of full damping range commanded to the front right shock rebound valve.

Could not parse SPN data type, please add:Type: Calculated
Parsed from -014. ";
CM_ SG_ 2566893871 pRebound_Damping_Percent__FL "Description: The calculated percent of full damping range commanded to the front left shock rebound valve.

Could not parse SPN data type, please add:Type: Calculated
Parsed from -014. ";
CM_ SG_ 2566893871 pRebound_Damping_Percent__RR "Description: The calculated percent of full damping range commanded to the rear right shock rebound valve.

Could not parse SPN data type, please add:Type: Calculated
Parsed from -014. ";
CM_ BO_ 2566887215 "Name: pSuspension Control 1
Description: Parsed from -014. ";
CM_ SG_ 2566887215 pVehicle_Event_Status__Accelerat "Description: Vehicle acceleration event detection status. ";
CM_ SG_ 2566887215 pVehicle_Event_Status__Cornering "Description: Vehicle roll event detection status. ";
CM_ SG_ 2566887215 pVehicle_Event_Status__Braking "Description: Vehicle braking event detection status. ";
CM_ SG_ 2566887215 pSuspension_Mode_Requested "Description: Indicates which suspension mode is requested. ";
CM_ SG_ 2566887215 pSuspension_Mode_Change_Active "Description: Determines whether the suspension mode change mode is active. ";
CM_ SG_ 2566887215 pCompression_Damping_Percent__RR "Description: The calculated percent of full damping range commanded to the rear right shock compression valve.

Could not parse SPN data type, please add:Type: Calculated
Parsed from -014. ";
CM_ SG_ 2566887215 pVehicle_Event_Status__Airborne "Description: Vehicle airborne event detection status. ";
CM_ SG_ 2566887215 pDemo_Status "Description: This signal indicates if the suspension control system is in Demo Mode.  ";
CM_ SG_ 2566887215 pCompression_Damping_Percent__RL "Description: The calculated percent of full damping range commanded to the rear left shock compression valve.

Could not parse SPN data type, please add:Type: Calculated
Parsed from -014. ";
CM_ SG_ 2566887215 pCompression_Damping_Percent__FL "Description: The calculated percent of full damping range commanded to the front left shock compression valve.

Could not parse SPN data type, please add:Type: Calculated
Parsed from -014. ";
CM_ SG_ 2566887215 pSuspension_Mode_Active "Description: Indicates which suspension mode is active. ";
CM_ SG_ 2566887215 pCompression_Damping_Percent__FR "Description: The calculated percent of full damping range commanded to the front right shock compression valve.

Could not parse SPN data type, please add:Type: Calculated
Parsed from -014. ";
CM_ SG_ 2566887215 pVehicle_Event_Status__Pucker "Description: Vehicle pucker event detection status. ";
CM_ BO_ 2297441583 "Name: Acceleration Sensor
Description: The acceleration sensor message shall provide a measurement of the vehicle�s acceleration in the lateral, longitudinal, and vertical axes. The vehicle dynamics and measurements in this message shall be according to";
CM_ SG_ 2297441583 Vertical_Acceleration_Figure_of_ "Description:Figure of merit for vertical acceleration measurement. 00b = vertical acceleration is fully functional. Data is within sensor specification 01b = verticalacceleration is degraded. Data is suspect due to enviro";
CM_ SG_ 2297441583 Lateral_Acceleration_Figure_of_M "Description:Figure of merit for lateral acceleration measurement. 00b = lateral acceleration is fully functional. Data is within sensor specification 01b = lateral acceleration is degraded. Data is suspect due to envirome";
CM_ SG_ 2297441583 Longitudinal_Acceleration_Extend "Description:Indicates longitudinal acceleration of the vehicle (the component of vehicle acceleration vector along the X-axis). A positive longitudinal acceleration signal results when the vehicle speed increases in the f";
CM_ SG_ 2297441583 Lateral_Acceleration_Extended_Ra "Description:Indicates lateral acceleration of the vehicle (the component of vehicle acceleration vector along the Y-axis). A positive lateral acceleration signal results when the vehicle is accelerated to the left. This p";
CM_ SG_ 2297441583 Longitudinal_Acceleration_Figure "Description:Figure of merit for longitudinal acceleration measurement. 00b = longitudinal acceleration is fully functional. Data is within sensor specification 01b = longitudinal acceleration is degraded. Data is suspect ";
CM_ SG_ 2297441583 Vertical_Acceleration_Extended_R "Description:Indicates vertical acceleration of the vehicle and the effect of gravity (the component of vehicle acceleration vector along the Z-axis). A positive vertical acceleration signal of 1 gravity results when the v";
CM_ SG_ 2297441583 Support_Variable_Transmission_Re "Description:Indicates which acceleration transmission rate are supported by the ECU in addition to the required 10 ms transmission rate. 00 = Reserve for SAE assignment 01 = Reserved for SAE assignment 10 to 20 = ms rate ";
CM_ BO_ 2365531183 "Name: pVehModCmd
Description:Vehicle Mode Command";
CM_ SG_ 2365531183 pEPSReqMod "Description: Used to set the EPAS assist mode. ";
CM_ BO_ 2633984545 "Name: pDrive System Status
Description: Parsed from -014. ";
CM_ SG_ 2633984545 pHeated_Grip_Enable "Description: This signal indicates the status of the Heated Grip Enable switch. ";
CM_ SG_ 2633984545 pUser_PIN_Access_Status "Description: This signal indicates if the display/gauge should show the User PIN screen, which allows the user the option of unlocking the vehicle security through the PIN code entry function.  ";
CM_ SG_ 2633984545 pActive_Descent_Control_ADC_Stat "Description: Broadcasting the status of the ADC (active indicates the solenoid is powered). ";
CM_ SG_ 2633984545 pCruise_Control_Set_Status "Description: Broadcasting the status of the Cruise Control Set Status for user indication  ";
CM_ SG_ 2633984545 pTether_Switch_Status "Description: Status of the Tether Switch ";
CM_ SG_ 2633984545 pHigh_Beam_Indicator_Status "Description: Broadcasting the status of the high beam headlight for user indication. ";
CM_ SG_ 2633984545 pLow_Fuel_Indicator_Status "Description: Broadcasting the status of the fuel level for user indication. ";
CM_ SG_ 2633984545 pHeated_Grips_Percentage "Description: Heated Grips Percent On, 0% is Off and 100% is the maximum heat
Could not parse SPN data type, please add:Type: Status
Parsed from -014. ";
CM_ SG_ 2633984545 pSide_Stand_Status "Description: Position of the side stand position when installed on a vehicle. ";
CM_ SG_ 2633984545 pTurf_Mode_Requested "Description: Broadcasting the status of the users request for TURF mode ";
CM_ SG_ 2633984545 pEngine_Idle_Shutdown_Timer "Description: This signal indicates the the amount of time left before the engine is shutdown due to the unattended vehicle engine idle shutdown function.
10-bit Timer:
0 &ndash; 1021 seconds
1022 - Error
1023 - Not Availab";
CM_ SG_ 2633984545 Operator_Not_in_Operating_Statio "Description: The Operator Presence Detection System indicates the operator is not in the correct operating station. ";
CM_ SG_ 2633984545 pAWD_Mode_Requested "Description: Broadcasting the status of the users request for AWD mode ";
CM_ SG_ 2633984545 pHeated_Grips_Up_Switch_Status "Description: This signal indicates the status of the Heated Grip Up switch. ";
CM_ SG_ 2633984545 pTreadle_Neutral_Status "Description: Broadcasting the status of the switch indicating the treadle is/is not in the Neutral position.  ";
CM_ SG_ 2633984545 pHeated_Grips_Down_Switch_Status "Description: This signal indicates the status of the Heated Grip Down switch. ";
CM_ SG_ 2633984545 pPark_Brake_Indicator_Status "Description: Broadcasting the status of the park brake for user indication ";
CM_ SG_ 2633984545 pRWD_Mode_Requested "Description: Broadcasting the status of the users request for RWD mode ";
CM_ SG_ 2633984545 pSeat_Belt_Indicator_Status "Description: Broadcasting the status of the seat belt for user indication ";
CM_ SG_ 2633984545 pSecurity_Light_Immobilizer_Stat "Description: Broadcasting the status of the security system for user indication.  ";
CM_ SG_ 2633984545 ECU_Security_Status "Description: Security Status of an ECU. ";
CM_ SG_ 2633984545 pActive_Decent_Control_ADC_Mode_ "Description: Broadcasting the status of the users request for ADC mode ";
CM_ SG_ 2633984545 pTreadle_Reverse_Status "Description: Broadcasting the status of the switch indicating the treadle is/is not in the Reverse position.  ";
CM_ BO_ 2349465377 "Name: Static Roll Angle Sensor Information
Description: Parsed from -014. ";
CM_ SG_ 2349465377 Static_Roll_Angle "Description:The measured static roll angle between the vehicle y-axis and the ground plane about the X-axis. The sign of the roll angle is determined in accordance to the right-hand rule about the X-axis, as specified in SAE J670. Roll ";
CM_ BO_ 2365523489 "Name: pModule Control Message
Description: Parsed from -014. ";
CM_ SG_ 2365523489 pModule_Control_Applied_State "Description: Indicates the requester&rsquo;s command to control wake state of other modules. Partial Wakeup and Full Wakeup are to be defined per each module.

 ";
CM_ SG_ 2365523489 pModule_Control_Command_Destinat "Description: Indicates which source address the requester is commanding. Destination address FFh is used to indicate that all source addresses should obey the Module Control Command State signal. FFFFh indicates &ldquo;no";
CM_ SG_ 2365523489 pModule_Control_Command_State "Description: Indicates the requester&rsquo;s command to control wake state of other modules. Each state to be defined per each module. ";
CM_ SG_ 2365523489 pModule_Control_Message_Checksum "Description: Message checksum that is calculated as follows:
Intermediate Checksum =
Byte1 + Byte2 + Byte3 + Byte4 + Byte5 + Byte6 + Byte7 + (8.1 Nibble & 0x0F) + Message ID Low Byte + Message ID Mid Low Byte + Message ";
CM_ BO_ 2633984656 "Name: pDrive System Status
Description: Parsed from -014. ";
CM_ SG_ 2633984656 pHeated_Grip_Enable "Description: This signal indicates the status of the Heated Grip Enable switch. ";
CM_ SG_ 2633984656 pUser_PIN_Access_Status "Description: This signal indicates if the display/gauge should show the User PIN screen, which allows the user the option of unlocking the vehicle security through the PIN code entry function.  ";
CM_ SG_ 2633984656 pActive_Descent_Control_ADC_Stat "Description: Broadcasting the status of the ADC (active indicates the solenoid is powered). ";
CM_ SG_ 2633984656 pCruise_Control_Set_Status "Description: Broadcasting the status of the Cruise Control Set Status for user indication  ";
CM_ SG_ 2633984656 pTether_Switch_Status "Description: Status of the Tether Switch ";
CM_ SG_ 2633984656 pHigh_Beam_Indicator_Status "Description: Broadcasting the status of the high beam headlight for user indication. ";
CM_ SG_ 2633984656 pLow_Fuel_Indicator_Status "Description: Broadcasting the status of the fuel level for user indication. ";
CM_ SG_ 2633984656 pHeated_Grips_Percentage "Description: Heated Grips Percent On, 0% is Off and 100% is the maximum heat
Could not parse SPN data type, please add:Type: Status
Parsed from -014. ";
CM_ SG_ 2633984656 pSide_Stand_Status "Description: Position of the side stand position when installed on a vehicle. ";
CM_ SG_ 2633984656 pTurf_Mode_Requested "Description: Broadcasting the status of the users request for TURF mode ";
CM_ SG_ 2633984656 pEngine_Idle_Shutdown_Timer "Description: This signal indicates the the amount of time left before the engine is shutdown due to the unattended vehicle engine idle shutdown function.
10-bit Timer:
0 &ndash; 1021 seconds
1022 - Error
1023 - Not Availab";
CM_ SG_ 2633984656 Operator_Not_in_Operating_Statio "Description: The Operator Presence Detection System indicates the operator is not in the correct operating station. ";
CM_ SG_ 2633984656 pAWD_Mode_Requested "Description: Broadcasting the status of the users request for AWD mode ";
CM_ SG_ 2633984656 pHeated_Grips_Up_Switch_Status "Description: This signal indicates the status of the Heated Grip Up switch. ";
CM_ SG_ 2633984656 pTreadle_Neutral_Status "Description: Broadcasting the status of the switch indicating the treadle is/is not in the Neutral position.  ";
CM_ SG_ 2633984656 pHeated_Grips_Down_Switch_Status "Description: This signal indicates the status of the Heated Grip Down switch. ";
CM_ SG_ 2633984656 pPark_Brake_Indicator_Status "Description: Broadcasting the status of the park brake for user indication ";
CM_ SG_ 2633984656 pRWD_Mode_Requested "Description: Broadcasting the status of the users request for RWD mode ";
CM_ SG_ 2633984656 pSeat_Belt_Indicator_Status "Description: Broadcasting the status of the seat belt for user indication ";
CM_ SG_ 2633984656 pSecurity_Light_Immobilizer_Stat "Description: Broadcasting the status of the security system for user indication.  ";
CM_ SG_ 2633984656 ECU_Security_Status "Description: Security Status of an ECU. ";
CM_ SG_ 2633984656 pActive_Decent_Control_ADC_Mode_ "Description: Broadcasting the status of the users request for ADC mode ";
CM_ SG_ 2633984656 pTreadle_Reverse_Status "Description: Broadcasting the status of the switch indicating the treadle is/is not in the Reverse position.  ";
CM_ BO_ 2365473168 "Name: Lighting Command LCMD
Description: Parsed from -014. ";
CM_ SG_ 2365473168 Left_Turn_Signal_Lights_Command "Description:Command to activate or de-activate left turn signal lights on the tractor and all connected implements 00b = De-activate 01b = Activate 10b = Reserved 11b = Don't Care
Note: Parsed from J1939DA.";
CM_ SG_ 2365473168 Alternate_Beam_Head_Light_Comman "Description:Command to activate or de-activate the tractor alternate head lights (only low beam is available on alternate head lights). The alternate position lights are intended for use with loader and snow plows that te";
CM_ SG_ 2365473168 Right_Turn_Signal_Lights_Command "Description:Command to activate or de-activate right turn signal lights on the tractor and all connected implements 00b = De-activate 01b = Activate 10b = Reserved 11b = Don't Care
Note: Parsed from J1939DA.";
CM_ SG_ 2365473168 Running_Light_Command "Description:Command to activate or de-activate the tractor or powered vehicle running lights. Usually only used for on road vehicles. 00b = De-activate 01b = Activate 10b = Reserved 11b = Don't Care
Note: Parsed from J1939DA.";
CM_ BO_ 2566860065 "Name: pInstrument Special Message
Description: Used to command special messages for the specific LCD Display using 2 bit status SPN�s only. The intention is to command specific warnings to the user when the vehicle is in specific states determined by th";
CM_ SG_ 2566860065 pSpecial_Msg_12 "Description: SPN Grouping contain Special Instruction Messages for LCD Display. See breakdown of PGN 65325 for further definition. ";
CM_ SG_ 2566860065 pSpecial_Msg_28 "Description: SPN Grouping contain Special Instruction Messages for LCD Display. See breakdown of PGN 65325 for further definition. ";
CM_ SG_ 2566860065 pSpecial_Msg_11 "Description: SPN Grouping contain Special Instruction Messages for LCD Display. See breakdown of PGN 65325 for further definition. ";
CM_ SG_ 2566860065 pSpecial_Msg_26 "Description: SPN Grouping contain Special Instruction Messages for LCD Display. See breakdown of PGN 65325 for further definition. ";
CM_ SG_ 2566860065 pSpecial_Msg_24 "Description: SPN Grouping contain Special Instruction Messages for LCD Display. See breakdown of PGN 65325 for further definition. ";
CM_ SG_ 2566860065 pSpecial_Msg_21 "Description: SPN Grouping contain Special Instruction Messages for LCD Display. See breakdown of PGN 65325 for further definition. ";
CM_ SG_ 2566860065 pSpecial_Msg_18 "Description: SPN Grouping contain Special Instruction Messages for LCD Display. See breakdown of PGN 65325 for further definition. ";
CM_ SG_ 2566860065 pSpecial_Msg_19 "Description: SPN Grouping contain Special Instruction Messages for LCD Display. See breakdown of PGN 65325 for further definition. ";
CM_ SG_ 2566860065 pSpecial_Msg_1_Riding_with_Brake "Description: SPN Grouping contain Special Instruction Messages for LCD Display. See breakdown of PGN 65325 for further definition. ";
CM_ SG_ 2566860065 pSpecial_Msg_2_Regulator_Overhea "Description: SPN Grouping contain Special Instruction Messages for LCD Display. See breakdown of PGN 65325 for further definition. ";
CM_ SG_ 2566860065 pSpecial_Msg_3_Regulator_Overhea "Description: SPN Grouping contain Special Instruction Messages for LCD Display. See breakdown of PGN 65325 for further definition. ";
CM_ SG_ 2566860065 pSpecial_Msg_4_Regulator_Overhea "Description: SPN Grouping contain Special Instruction Messages for LCD Display. See breakdown of PGN 65325 for further definition. ";
CM_ SG_ 2566860065 pSpecial_Msg_5_Engine_Warmup_Com "Description: SPN Grouping contain Special Instruction Messages for LCD Display. See breakdown of PGN 65325 for further definition. ";
CM_ SG_ 2566860065 pSpecial_Msg_6_Engine_Knock__Mod "Description: SPN Grouping contain Special Instruction Messages for LCD Display. See breakdown of PGN 65325 for further definition. ";
CM_ SG_ 2566860065 pSpecial_Msg_8_Low_Coolant_Warni "Description: SPN Grouping contain Special Instruction Messages for LCD Display. See breakdown of PGN 65325 for further definition. ";
CM_ SG_ 2566860065 pSpecial_Msg_7_Engine_Knock__Mos "Description: SPN Grouping contain Special Instruction Messages for LCD Display. See breakdown of PGN 65325 for further definition. ";
CM_ SG_ 2566860065 pSpecial_Msg_9_Transmission_Temp "Description: SPN Grouping contain Special Instruction Messages for LCD Display. See breakdown of PGN 65325 for further definition. ";
CM_ SG_ 2566860065 pSpecial_Msg_10_Reverse_Speed_Li "Description: SPN Grouping contain Special Instruction Messages for LCD Display. See breakdown of PGN 65325 for further definition. ";
CM_ SG_ 2566860065 pSpecial_Msg_13_Belt_Burn_Warnin "Description: SPN Grouping contain Special Instruction Messages for LCD Display. See breakdown of PGN 65325 for further definition. ";
CM_ SG_ 2566860065 pSpecial_Msg_14_Park_Brake_Warni "Description: SPN Grouping contain Special Instruction Messages for LCD Display. See breakdown of PGN 65325 for further definition. ";
CM_ SG_ 2566860065 pSpecial_Msg_15_TCM_Comm_Loss "Description: SPN Grouping contain Special Instruction Messages for LCD Display. See breakdown of PGN 65325 for further definition. ";
CM_ SG_ 2566860065 pSpecial_Msg_16_TCM_Pump_Priming "Description: SPN Grouping contain Special Instruction Messages for LCD Display. See breakdown of PGN 65325 for further definition. ";
CM_ SG_ 2566860065 pSpecial_Msg_17_Request_User_to_ "Description: SPN Grouping contain Special Instruction Messages for LCD Display. See breakdown of PGN 65325 for further definition. ";
CM_ SG_ 2566860065 pSpecial_MSG_20_Fuel_Door_Open_E "Description: SPN Grouping contain Special Instruction Messages for LCD Display. See breakdown of PGN 65325 for further definition. ";
CM_ SG_ 2566860065 pSpecial_MSG_22_Clutch_Overtemp "Description: SPN Grouping contain Special Instruction Messages for LCD Display. See breakdown of PGN 65325 for further definition. ";
CM_ SG_ 2566860065 pSpecial_MSG_23_Exhaust_Valve_Ch "Description: SPN Grouping contain Special Instruction Messages for LCD Display. See breakdown of PGN 65325 for further definition. ";
CM_ SG_ 2566860065 pSpecial_MSG_25_Engine_Idle_Shut "Description: SPN Grouping contain Special Instruction Messages for LCD Display. See breakdown of PGN 65325 for further definition. ";
CM_ SG_ 2566860065 pSpecial_MSG_27_Overboost_Condit "Description: SPN Grouping contain Special Instruction Messages for LCD Display. See breakdown of PGN 65325 for further definition. ";
CM_ SG_ 2566860065 pSpecial_Msg_31_Engine_Tip_Over_ "Description: Engine Tip Over Lockout Special Message designed to indicate to the instrument cluster that an engine tip over condition is present and that the engine is currently preventing the user from starting the engin";
CM_ SG_ 2566860065 pSpecial_Msg_32_Engine_Tip_Over_ "Description: Engine Tip Over Lockout - Heal State Special Message designed to communicate to the instrument cluster that the vehicle is still currently in a engine tip over condition but is in the process of it being heal";
CM_ BO_ 2348875520 "Name: Torque/Speed Control 1
Description: Parsed from -014. ";
CM_ SG_ 2348875520 Engine_Requested_Torque_Fraction "Description:This parameter displays an additional torque in percent of the reference engine torque. When the MSB is set to 1, this parameter is not available. When the MSB is set to 0, bits 1 to 3 indicate the desired tor";
CM_ SG_ 2348875520 Engine_Override_Control_Mode "Description:The override control mode defines which sort of command is used: 00b = Override disabled - Disable any existing control commanded by the source of this command. 01b = Speed control - Govern speed to the included d";
CM_ SG_ 2348875520 Engine_Requested_SpeedSpeed_Limi "Description:Parameter provided to the engine from external sources in the torque/speed control message. This is the engine speed which the engine is expected to operate at if the speed control mode is active or the engine";
CM_ SG_ 2348875520 Engine_Requested_Speed_Control_C "Description:This mode tells the engine control system the governor characteristics that are desired during speed control. The four characteristics defined are: 00b = Transient Optimized for driveline disengaged and non-lo";
CM_ SG_ 2348875520 TSC1_Control_Purpose "Description:State signal which indicates which control mode the sending device is using to generate the TSC1 command. Note that the modes are not in prioritized order. Not all modes may be relevant for a given device. Some devices ma";
CM_ SG_ 2348875520 Override_Control_Mode_Priority "Description:This field is used as an input to the engine or retarder to determine the priority of the Override Control Mode received in the Torque/Speed Control message (see PGN 0). The default is 11b (Low priority). It is ";
CM_ SG_ 2348875520 TSC1_Transmission_Rate "Description:This parameter indicates the transmission rate at which the sending device will transmit the TSC1 message. The engine shall adjust its timeout for TSC1 messages accordingly. Variable TSC1 transmission rates shall only a";
CM_ SG_ 2348875520 Engine_Requested_TorqueTorque_Li "Description:Parameter provided to the engine or retarder in the torque/speed control message for controlling or limiting the output torque. Requested torque to the engine is measured in indicated torque as a percentage of";
CM_ BO_ 2364539648 "Name: Electronic Engine Controller 2
Description: Parsed from -014. ";
CM_ SG_ 2364539648 Accelerator_Pedal_Position_1 "Description:This parameter is intended for the primary accelerator control in an application. SPN 91 is the calculated ratio of actual position of the operator's [engine] speed request or [engine] torque request input device ";
CM_ BO_ 2631728896 "Name: Anti-Theft Staus
Description: Parsed from -014. ";
CM_ SG_ 2631728896 Antitheft_Random_Number "Description:A seven byte random numeric code provided by the component in response to an anti-theft request. This parameter is sent as a numeric value utilizing the full range of 0 to FFFFFFFFFFFFFFh. The most significant byte is ";
CM_ SG_ 2631728896 Antitheft_Encryption_Seed_Presen "Description:Indicates the presence of the encryption seed random number. 00b = Random number is not present 01b = Random number is present 10b = Error 11b = Not available
Note: Parsed from J1939DA.";
CM_ SG_ 2631728896 Antitheft_Password_Valid_Indicat "Description:Indicates the presence of a validated password. 00b = Password is not a validated password 01b = Password is a validated password 10b = Error 11b = Not available
Note: Parsed from J1939DA.";
CM_ SG_ 2631728896 Antitheft_Modify_Password_States "Description:This parameter is used to indicate whether a password request was successfully performed, or if the request could not be perform due to system constraints or if the request was not a valid request. 00b = Ok 01";
CM_ SG_ 2631728896 Antitheft_Component_Status_State "Description:Indicates whether or not the component can be started. 00b = Unlocked 01b = Locked 10b = Blocked 11b = Not defined 00b - Unlocked = This state indicates that the component can be started without the end user b";
CM_ BO_ 2364539904 "Name: Electronic Engine Controller
Description:Parsed from -014.";
CM_ SG_ 2364539904 Engine_Speed "Description:Actual engine speed which is calculated over a minimum crankshaft angle of 720 degrees divided by the number of cylinders.
Note: Parsed from J1939DA.";
CM_ SG_ 2364539904 Engine_Demand__Percent_Torque "Description:The requested torque output of the engine by all dynamic internal inputs, including smoke control, noise control and low and high speed governing.
Note: Parsed from J1939DA.";
CM_ SG_ 2364539904 Drivers_Demand_Engine__Percent_T "Description:The requested torque output of the engine by the driver. It is based on input from the following requestors external to the powertrain: operator (via the accelerator pedal), cruise control and/or road speed li";
CM_ SG_ 2364539904 Engine_Starter_Mode "Description:There are several phases in a starting action and different reasons why a start cannot take place. 0000b = start not requested 0001b = starter active but not engaged 0010b = starter active and engaged 0011b = start finishe";
CM_ SG_ 2364539904 Source_Address_of_Controlling_De "Description:The source address of the SAE J1939 device currently controlling the engine. It is used to expand the torque mode parameter (see SPN 899) in cases where control is in response to an ECU that is not listed in T";
CM_ SG_ 2364539904 Actual_Engine__Percent_Torque "Description:The calculated output torque of the engine. The data is transmitted in indicated torque as a percent of reference engine torque (see the engine configuration message, PGN 65251). The engine percent torque value w";
CM_ SG_ 2364539904 Engine_Torque_Mode "Description:State signal which indicates which engine torque mode is currently generating, limiting, or controlling the torque. Note that the modes are not in prioritized order. Not all modes may be relevant for a given device. Some de";
CM_ BO_ 2565866752 "Name: Electronic Transmission Controller
Description: Parsed from -014. ";
CM_ SG_ 2565866752 Transmission_Actual_Gear_Ratio "Description:Actual ratio of input shaft speed to output shaft speed.
Note: Parsed from J1939DA.";
CM_ SG_ 2565866752 Transmission_Requested_Range "Description:Range selected by the operator. Characters may include P, Rx, Rx-1...R2, R1, R, Nx, Nx-1...N2, N1, N, D, D1, D2..., Dx, L, L1, L2..., Lx-1, 1, 2, 3,... If only one displayed character is required, the second chara";
CM_ SG_ 2565866752 Transmission_Current_Range "Description:Range currently being commanded by the transmission control system. Characters may include P, Rx, Rx-1...R2, R1, R, Nx, Nx-1...N2, N1, N, D, D1, D2..., Dx, L, L1, L2..., Lx-1, 1, 2, 3,... If only one displayed chara";
CM_ SG_ 2565866752 Transmission_Current_Gear "Description:The gear currently engaged in the transmission or the last gear engaged while the transmission is in the process of shifting to the new or selected gear. Transitions toward a destination gear will not be indicated. O";
CM_ SG_ 2565866752 Transmission_Selected_Gear "Description:The gear that the transmission will attempt to achieve during the current shift if a shift is in progress, or the next shift if one is pending (i.e., waiting for torque reduction to initiate the shift). Negative val";
CM_ BO_ 2431708416 "Name: Engine Start Control (ENGSC)
Description: Parsed from -014. ";
CM_ SG_ 2431708416 Engine_Starter_2_Feedback "Description:Feedback of the current state of second engine starter. This signal is intended to be used by the arbitrator as feedback to its command signal (SPN 7753). Additional details regarding the starter state may be availab";
CM_ SG_ 2431708416 Engine_Start_Request "Description:Indicates the sender's desire to start the engine. The engine start arbitrator latches this signal and, if possible, completes the engine start regardless of a change of state of this signal. Use Engine Start Abort Reques";
CM_ SG_ 2431708416 Engine_Start_Abort_Request "Description:Indicates the sender's desire to abort an engine start. This signal is used by requesters and consenters to request that the arbitrator cancel an engine start that is in progress. The sender of this signal may incre";
CM_ SG_ 2431708416 Engine_Start_Control_Checksum "Description:Checksum to allow detection of data integrity issues. The receiving node shall calculate the checksum and compare its calculated value with the received checksum. In case of a mismatch the message shall be discar";
CM_ SG_ 2431708416 Transmission_Shift_Selector_Requ "Description:This parameter indicates the direction selected by the operator via the active transmission shift selector. Some regulations (e.g., Federal Motor Vehicle Safety Standards 102) require specific Engine Stop-Star";
CM_ SG_ 2431708416 Engine_Start_Control_Message_Cou "Description:Message counter to allow detection of data integrity issues. The counter is incremented every time a device sends out the Engine Start Control message. When the counter has reached a value of 15 it starts over";
CM_ SG_ 2431708416 Engine_Start_Consent "Description:Indicates the sender's consent to start the engine for different start types. An operator-requested engine start is a start that is initiated directly by the operator (i.e. via the key switch). An automatic engine start i";
CM_ SG_ 2431708416 Engine_Starter_1_Feedback "Description:Feedback of the current state of first engine starter. This signal is intended to be used by the arbitrator as feedback to its command signal (SPN 7753). Additional details regarding the starter state may be availabl";
CM_ BO_ 2565867008 "Name: Electronic Axle Controller
Description: Parsed from -014. ";
CM_ SG_ 2565867008 Differential_Lock_State__Central "Description:State used which indicates the condition of the central differential lock. The differential locks are located as defined in attached figure SPN564_A. 00b = Differential lock disengaged 01b = Differential lock ";
CM_ SG_ 2565867008 Location "Description:To identify to which of several similar devices (such as tires or fuel tanks) the information applies. The low order 4 bits represent a position number, counting left to right when facing in the direction of normal vehicle travel (fo";
CM_ SG_ 2565867008 Differential_Lock_State__Front_A "Description:State used which indicates the condition of the front axle 1 differential lock. The differential locks are located as defined in figure SPN564_A. 00b = Differential lock disengaged 01b = Differential lock enga";
CM_ SG_ 2565867008 Differential_Lock_State__Rear_Ax "Description:State used which indicates the condition of the rear axle 1 differential lock. The differential locks are located as defined in figure SPN 564_A. 00b = Differential lock disengaged 01b = Differential lock enga";
CM_ BO_ 2365428224 "Name: Engine Operating Information
Description:Parsed from -014.";
CM_ SG_ 2365428224 Fuel_Pump_Primer_Control "Description:Parameter used to activate or deactivate a priming system on the fuel transfer system. The fuel priming system is a system that purges air in the fuel lines and may assist fuel delivery to a second pump at lower speed";
CM_ SG_ 2365428224 Engine_Operating_State "Description:This parameter is used to indicate the current state, or mode, of operation by the engine. This is a status parameter. 0000b = Engine Stopped 0001b = Pre-Start 0010b = Starting 0011b = Warm-Up 0100b = Running 0101b = Co";
CM_ SG_ 2365428224 Engine_Fuel_Shutoff_1_Control "Description:Control setting for fuel shutoff 1. The second instance is SPN 2807. For a single fuel shutoff system, this represents its commanded position. For a dual fuel shutoff system, this SP is representative of the upst";
CM_ BO_ 2365449728 "Name: Hydraulic Braking System
Description: Parsed from -014. ";
CM_ SG_ 2365449728 Hydraulic_Brake_Pressure_Warning "Description:Signal which indicates whether the hydraulic brake pressure of circuit 2 is below the warning level 00b = Pressure level sufficient 01b = Pressure level below warning level 10b = Error indicator 11b = Not avai";
CM_ SG_ 2365449728 Hydraulic_Brake_Pressure_Supply_ "Description:Signal which indicates whether the hydraulic brake pressure supply of circuit 2 is reliable; that is, able to support continued braking. 00b = Supply is not reliable 01b = Supply is reliable 10b = Error indica";
CM_ SG_ 2365449728 Hydraulic_Brake_Pressure_Supply_ "Description:Signal which indicates whether the hydraulic brake pressure supply of circuit 1 is reliable; that is, able to support continued braking. 00b = Supply is not reliable 01b = Supply is reliable 10b = Error indica";
CM_ SG_ 2365449728 Hydraulic_Brake_Pressure_Warning "Description:Signal which indicates whether the hydraulic brake pressure of circuit 1 is below the warning level 00b = Pressure level sufficient 01b = Pressure level below warning level 10b = Error indicator 11b = Not avai";
CM_ SG_ 2365449728 Hydraulic_Brake_Pressure_Circuit "Description:Gage hydraulic pressure in circuit 1 of the hydraulic brake system
Note: Parsed from J1939DA.";
CM_ SG_ 2365449728 Hydraulic_Brake_Pressure_Circuit "Description:Gage hydraulic pressure in circuit 2 of the hydraulic brake system
Note: Parsed from J1939DA.";
CM_ SG_ 2365449728 Hydraulic_Brake_Fluid_Level_Swit "Description:Signal which indicates whether the hydraulic fluid level in the reservoir(s) is sufficient. 00b = Fluid level is not sufficient 01b = Fluid level is sufficient 10b = Error indicator 11b = Not available
Note: ";
CM_ BO_ 2633883392 "Name: Front Wheel Drive Status
Description: Parsed from -014. ";
CM_ SG_ 2633883392 Front_Wheel_Drive_Actuator_Statu "Description:Feedback on the front wheel drive actuator. 00b = Front Wheel Drive Actuator not engaged 01b = Front Wheel Drive Actuator engaged 10b = Error 11b = Not Available
Note: Parsed from J1939DA.";
CM_ BO_ 2566768128 "Name: Cold Start Aids
Description:Parsed from -014.";
CM_ SG_ 2566768128 Engine_Cold_Start_Fuel_Igniter_R "Description:Feedback state of the engine cold start fuel igniter relay which indicates the status of the relay output. 00b = Off 01b = On 10b = Error 11b = Not available
Note: Parsed from J1939DA.";
CM_ SG_ 2566768128 Engine_Cold_Start_Fuel_Igniter_R "Description:The engine cold start fuel igniter relay control command. This command controls the relay, not the igniter. 00b = Off 01b = On 10b = Reserved 11b = Don't care/take no action
Note: Parsed from J1939DA.";
CM_ BO_ 2566832384 "Name: High Resolution Vehicle Distance
Description: Parsed from -014. ";
CM_ SG_ 2566832384 Total_Vehicle_Distance_High_Reso "Description:Accumulated distance traveled by the vehicle during its operation. NOTE - See SPN 245 for alternate resolution.
Note: Parsed from J1939DA.";
CM_ SG_ 2566832384 Trip_Distance_High_Resolution "Description:Distance traveled during all or part of a journey. NOTE - See SPN 244 for alternate resolution.
Note: Parsed from J1939DA.";
CM_ BO_ 2566834944 "Name: Previously Active Diagnostic Trouble Codes
Description:When supported, DM2 provides a list of all previously active (previously detected) DTCs. The list of DTCs must include
all the emissions-related previously active DTCs provided in the device’";
CM_ SG_ 2566834944 Protect_Lamp_Status "Description:Used to relay trouble code information that is reporting a problem with a vehicle system that is most probably not electronic subsystem related. For instance, engine coolant temperature is exceeding its prescribed temperat";
CM_ SG_ 2566834944 Amber_Warning_Lamp_Status "Description:Used to relay trouble code information that is reporting a problem with the vehicle system but the vehicle need not be immediately stopped.
See J1939-71 for complete reference

Parsed from -014.";
CM_ SG_ 2566834944 Red_Stop_Lamp_Status "Description:Used to relay trouble code information that is of a severe enough condition that it warrants stopping the vehicle.
See J1939-71 for complete reference

Parsed from -014.";
CM_ SG_ 2566834944 Malfunction_Indicator_Lamp_Statu "Description:Used to relay only emissions-related trouble code information. This lamp is only illuminated when there is an emission-related trouble code active.
See J1939-71 for complete reference

Parsed from -014.";
CM_ SG_ 2566834944 Flash_Protect_Lamp "Description:This parameter provides the capability to flash the protect lamp. 
See J1939-73 for complete reference
Parsed from -014.";
CM_ SG_ 2566834944 Flash_Amber_Warning_Lamp_AWL "Description:This parameter provides the capability to flash the AWL. 
See J1939-73 for complete reference
Parsed from -014.";
CM_ SG_ 2566834944 Flash_Red_Stop_Lamp_RSL "Description:This parameter provides the capability to flash the RSL.
See J1939-73 for complete reference
Parsed from -014.";
CM_ SG_ 2566834944 Flash_Malfunction_Indicator_Lamp "Description:This parameter provides the capability to flash the MIL. For OBD systems which are required to flash the SPN for specific malfunctions shall use the “slow flash” rate. 
See J1939-73 for complete reference
Pa";
CM_ SG_ 2566834944 DTC_1 "Description:This signal is a combination of 4 SPNs. To decode this signal, navigate to MCS tools.
Byte: 1 bits 8-1 SPN, 8 least significant bits of SPN (most significant at bit 8, SPN 1214)
Byte: 2 bits 8-1 SPN, second byte of SPN (most significa";
CM_ SG_ 2566834944 DTC_2 "Description:This signal is a combination of 4 SPNs. To decode this signal, navigate to MCS tools.
Byte: 1 bits 8-1 SPN, 8 least significant bits of SPN (most significant at bit 8, SPN 1214)
Byte: 2 bits 8-1 SPN, second byte of SPN (most significa";
CM_ SG_ 2566834944 DTC_3 "Description:This signal is a combination of 4 SPNs. To decode this signal, navigate to MCS tools.
Byte: 1 bits 8-1 SPN, 8 least significant bits of SPN (most significant at bit 8, SPN 1214)
Byte: 2 bits 8-1 SPN, second byte of SPN (most significa";
CM_ SG_ 2566834944 DTC_4 "Description:This signal is a combination of 4 SPNs. To decode this signal, navigate to MCS tools.
Byte: 1 bits 8-1 SPN, 8 least significant bits of SPN (most significant at bit 8, SPN 1214)
Byte: 2 bits 8-1 SPN, second byte of SPN (most significa";
CM_ SG_ 2566834944 DTC_5 "Description:This signal is a combination of 4 SPNs. To decode this signal, navigate to MCS tools.
Byte: 1 bits 8-1 SPN, 8 least significant bits of SPN (most significant at bit 8, SPN 1214)
Byte: 2 bits 8-1 SPN, second byte of SPN (most significa";
CM_ SG_ 2566834944 DTC_6 "Description:This signal is a combination of 4 SPNs. To decode this signal, navigate to MCS tools.
Byte: 1 bits 8-1 SPN, 8 least significant bits of SPN (most significant at bit 8, SPN 1214)
Byte: 2 bits 8-1 SPN, second byte of SPN (most significa";
CM_ SG_ 2566834944 DTC_7 "Description:This signal is a combination of 4 SPNs. To decode this signal, navigate to MCS tools.
Byte: 1 bits 8-1 SPN, 8 least significant bits of SPN (most significant at bit 8, SPN 1214)
Byte: 2 bits 8-1 SPN, second byte of SPN (most significa";
CM_ SG_ 2566834944 DTC_8 "Description:This signal is a combination of 4 SPNs. To decode this signal, navigate to MCS tools.
Byte: 1 bits 8-1 SPN, 8 least significant bits of SPN (most significant at bit 8, SPN 1214)
Byte: 2 bits 8-1 SPN, second byte of SPN (most significa";
CM_ SG_ 2566834944 DTC_9 "Description:This signal is a combination of 4 SPNs. To decode this signal, navigate to MCS tools.
Byte: 1 bits 8-1 SPN, 8 least significant bits of SPN (most significant at bit 8, SPN 1214)
Byte: 2 bits 8-1 SPN, second byte of SPN (most significa";
CM_ SG_ 2566834944 DTC_10 "Description:This signal is a combination of 4 SPNs. To decode this signal, navigate to MCS tools.
Byte: 1 bits 8-1 SPN, 8 least significant bits of SPN (most significant at bit 8, SPN 1214)
Byte: 2 bits 8-1 SPN, second byte of SPN (most signific";
CM_ BO_ 2566819840 "Name: Engine Torque History
Description: Could not parse data length. Please add to field:Data Length: 8 (J1939 -71 specification is 38)
Parsed from -014. ";
CM_ SG_ 2566819840 Engine_Peak_Torque_1 "Description:Maximum torque output of the current ECU calibration when the engine operates on torque curve 1. For calibrations that support two torque curves, this parameter shall be assigned the value of the lower curve. For calibrat";
CM_ BO_ 2566834688 "Name: Active Diagnostic Trouble Codes
Description:DM1 provides diagnostic lamp status and Diagnostic Trouble Codes (DTCs). Together, the lamp and DTC information
convey the diagnostic condition of the transmitting electronic component to other componen";
CM_ SG_ 2566834688 Flash_Malfunction_Indicator_Lamp "Description:This parameter provides the capability to flash the MIL. For OBD systems which are required to flash the SPN for specific malfunctions shall use the “slow flash” rate. 
See J1939-73 for complete reference
Pa";
CM_ SG_ 2566834688 Malfunction_Indicator_Lamp_Statu "Description:Used to relay only emissions-related trouble code information. This lamp is only illuminated when there is an emission-related trouble code active.
See J1939-71 for complete reference

Parsed from -014.";
CM_ SG_ 2566834688 Red_Stop_Lamp_Status "Description:Used to relay trouble code information that is of a severe enough condition that it warrants stopping the vehicle.
See J1939-71 for complete reference

Parsed from -014.";
CM_ SG_ 2566834688 Amber_Warning_Lamp_Status "Description:Used to relay trouble code information that is reporting a problem with the vehicle system but the vehicle need not be immediately stopped.
See J1939-71 for complete reference

Parsed from -014.";
CM_ SG_ 2566834688 Flash_Red_Stop_Lamp_RSL "Description:This parameter provides the capability to flash the RSL.
See J1939-73 for complete reference
Parsed from -014.";
CM_ SG_ 2566834688 Flash_Amber_Warning_Lamp_AWL "Description:This parameter provides the capability to flash the AWL. 
See J1939-73 for complete reference
Parsed from -014.";
CM_ SG_ 2566834688 Flash_Protect_Lamp "Description:This parameter provides the capability to flash the protect lamp. 
See J1939-73 for complete reference
Parsed from -014.";
CM_ SG_ 2566834688 Protect_Lamp_Status "Description:Used to relay trouble code information that is reporting a problem with a vehicle system that is most probably not electronic subsystem related. For instance, engine coolant temperature is exceeding its prescribed temperat";
CM_ SG_ 2566834688 DTC_1 "Description:This signal is a combination of 4 SPNs. To decode this signal, navigate to MCS tools.
Byte: 1 bits 8-1 SPN, 8 least significant bits of SPN (most significant at bit 8, SPN 1214)
Byte: 2 bits 8-1 SPN, second byte of SPN (most significa";
CM_ SG_ 2566834688 DTC_2 "Description:This signal is a combination of 4 SPNs. To decode this signal, navigate to MCS tools.
Byte: 1 bits 8-1 SPN, 8 least significant bits of SPN (most significant at bit 8, SPN 1214)
Byte: 2 bits 8-1 SPN, second byte of SPN (most significa";
CM_ SG_ 2566834688 DTC_3 "Description:This signal is a combination of 4 SPNs. To decode this signal, navigate to MCS tools.
Byte: 1 bits 8-1 SPN, 8 least significant bits of SPN (most significant at bit 8, SPN 1214)
Byte: 2 bits 8-1 SPN, second byte of SPN (most significa";
CM_ SG_ 2566834688 DTC_4 "Description:This signal is a combination of 4 SPNs. To decode this signal, navigate to MCS tools.
Byte: 1 bits 8-1 SPN, 8 least significant bits of SPN (most significant at bit 8, SPN 1214)
Byte: 2 bits 8-1 SPN, second byte of SPN (most significa";
CM_ SG_ 2566834688 DTC_5 "Description:This signal is a combination of 4 SPNs. To decode this signal, navigate to MCS tools.
Byte: 1 bits 8-1 SPN, 8 least significant bits of SPN (most significant at bit 8, SPN 1214)
Byte: 2 bits 8-1 SPN, second byte of SPN (most significa";
CM_ SG_ 2566834688 DTC_6 "Description:This signal is a combination of 4 SPNs. To decode this signal, navigate to MCS tools.
Byte: 1 bits 8-1 SPN, 8 least significant bits of SPN (most significant at bit 8, SPN 1214)
Byte: 2 bits 8-1 SPN, second byte of SPN (most significa";
CM_ SG_ 2566834688 DTC_7 "Description:This signal is a combination of 4 SPNs. To decode this signal, navigate to MCS tools.
Byte: 1 bits 8-1 SPN, 8 least significant bits of SPN (most significant at bit 8, SPN 1214)
Byte: 2 bits 8-1 SPN, second byte of SPN (most significa";
CM_ SG_ 2566834688 DTC_8 "Description:This signal is a combination of 4 SPNs. To decode this signal, navigate to MCS tools.
Byte: 1 bits 8-1 SPN, 8 least significant bits of SPN (most significant at bit 8, SPN 1214)
Byte: 2 bits 8-1 SPN, second byte of SPN (most significa";
CM_ SG_ 2566834688 DTC_9 "Description:This signal is a combination of 4 SPNs. To decode this signal, navigate to MCS tools.
Byte: 1 bits 8-1 SPN, 8 least significant bits of SPN (most significant at bit 8, SPN 1214)
Byte: 2 bits 8-1 SPN, second byte of SPN (most significa";
CM_ SG_ 2566834688 DTC_10 "Description:This signal is a combination of 4 SPNs. To decode this signal, navigate to MCS tools.
Byte: 1 bits 8-1 SPN, 8 least significant bits of SPN (most significant at bit 8, SPN 1214)
Byte: 2 bits 8-1 SPN, second byte of SPN (most signific";
CM_ BO_ 2633929216 "Name: Engine Information 1
Description: Could not parse data length. Please add to field:Data Length: 8
Parsed from -014. ";
CM_ SG_ 2633929216 Engine_Fuel_Rack_Position "Description:Measured position of the engine fuel rack. A value of 0% rack represents no fueling and a value of 100% rack represents maximum fueling.
Note: Parsed from J1939DA.";
CM_ BO_ 2566841344 "Name: Shutdown
Description: Parsed from -014. ";
CM_ SG_ 2566841344 Engine_Wait_to_Start_Lamp "Description:Lamp signal which indicates that the engine is too cold to start and the operator should wait until the signal becomes inactive (turns off). See SPN 5416 for the lamp operating condition. 00b = Off 01b = On 10b = Err";
CM_ BO_ 2566825472 "Name: Intake Manifold Information 1
Description: Parsed from -014. ";
CM_ SG_ 2566825472 Engine_Turbocharger_1_Boost_Pres "Description:Gage pressure of air measured downstream of the compressor discharge side of the turbocharger. See also SPN 102 for alternate range and resolution. If there is only one boost pressure to report and the range a";
CM_ BO_ 2365473024 "Name: Lighting Command LCMD
Description: Parsed from -014. ";
CM_ SG_ 2365473024 Left_Turn_Signal_Lights_Command "Description:Command to activate or de-activate left turn signal lights on the tractor and all connected implements 00b = De-activate 01b = Activate 10b = Reserved 11b = Don't Care
Note: Parsed from J1939DA.";
CM_ SG_ 2365473024 Alternate_Beam_Head_Light_Comman "Description:Command to activate or de-activate the tractor alternate head lights (only low beam is available on alternate head lights). The alternate position lights are intended for use with loader and snow plows that te";
CM_ SG_ 2365473024 Right_Turn_Signal_Lights_Command "Description:Command to activate or de-activate right turn signal lights on the tractor and all connected implements 00b = De-activate 01b = Activate 10b = Reserved 11b = Don't Care
Note: Parsed from J1939DA.";
CM_ SG_ 2365473024 Running_Light_Command "Description:Command to activate or de-activate the tractor or powered vehicle running lights. Usually only used for on road vehicles. 00b = De-activate 01b = Activate 10b = Reserved 11b = Don't Care
Note: Parsed from J1939DA.";
CM_ BO_ 2566844160 "Name: Engine Fluid Level/Pressure 1
Description: Parsed from -014. ";
CM_ SG_ 2566844160 Engine_Oil_Pressure_1 "Description:Gage pressure of oil in engine lubrication system as provided by oil pump. See SPN 7468 for alternate resolution.
Note: Parsed from J1939DA.";
CM_ SG_ 2566844160 Engine_Oil_Level "Description:Ratio of current volume of engine sump oil to maximum required volume.
Note: Parsed from J1939DA.";
CM_ SG_ 2566844160 Engine_Coolant_Level_1 "Description:Ratio of volume of liquid found in engine cooling system to total cooling system volume. Typical monitoring location is in the coolant expansion tank.
Note: Parsed from J1939DA.";
CM_ SG_ 2566844160 Engine_Coolant_Pressure_1 "Description:Gage pressure of liquid found in engine cooling system. See SPN 20 for alternate range and resolution.
Note: Parsed from J1939DA.";
CM_ SG_ 2566844160 Engine_Crankcase_Pressure_1 "Description:First instance of the gage pressure inside engine crankcase.
Note: Parsed from J1939DA.";
CM_ BO_ 2566841600 "Name: Engine Hours Revolutions
Description:Parsed from -014.";
CM_ SG_ 2566841600 Engine_Total_Hours_of_Operation "Description:Accumulated time of operation of engine.
Note: Parsed from J1939DA.";
CM_ SG_ 2566841600 Engine_Total_Revolutions "Description:Accumulated number of revolutions of engine crankshaft during its operation.
Note: Parsed from J1939DA.";
CM_ BO_ 2566844672 "Name: Cruise Control Vehicle Speed 1
Description: Parsed from -014. ";
CM_ SG_ 2566844672 Cruise_Control_Set_Speed "Description:Value of set (chosen) velocity of velocity control system. See SPN 6809 for an alternate resolution. If an algorithm that can modify the cruise control set point exists in the system, such as Predictive Cruise Control";
CM_ SG_ 2566844672 Cruise_Control_Active "Description:Cruise control is switched on. It is not ensured that the engine is controlled by cruise control, as in the case of a large driver's demand the engine is controlled by the driver while cruise control is active (maximum s";
CM_ SG_ 2566844672 Clutch_Switch "Description:Switch signal which indicates that the clutch pedal is being pressed. It is necessary for a safe drivetrain behavior that the clutch switch is set before the clutch is opened (cruise control function). 00b = Clutch pedal release";
CM_ SG_ 2566844672 Brake_Switch "Description:Switch signal which indicates that the driver operated brake foot pedal is being pressed. This brake foot pedal is controlling the vehicles' service brake (total vehicle braking application, not park brakes). It is necessary for ";
CM_ SG_ 2566844672 pCC_Message_Counter "Description: Rolling Counter (ensures updated message is used).
Could not parse SPN data type, please add:Type: Status
Parsed from -014. ";
CM_ SG_ 2566844672 Cruise_Control_Pause_Switch "Description:Switch signal which indicates the position of the Cruise Control Pause Switch used on Remote Cruise Control applications. The Cruise Control Pause Switch signal temporarily disables the Cruise Control function. 00b";
CM_ SG_ 2566844672 Cruise_Control_Set_Switch "Description:Switch signal of the cruise control activator which indicates that the activator is in the position set. 00b = Cruise control activator not in the position set 01b = Cruise control activator in position set 10b = Err";
CM_ SG_ 2566844672 Two_Speed_Axle_Switch "Description:Switch signal which indicates the current axle range. 00b = Low speed range 01b = High speed range 10b = Error 11b = Not available
Note: Parsed from J1939DA.";
CM_ SG_ 2566844672 Cruise_Control_Enable_Switch "Description:Switch signal which indicates that it is possible to manage the cruise control function. 00b = Cruise control disabled 01b = Cruise control enabled 10b = Error 11b = Not available
Note: Parsed from J1939DA.";
CM_ SG_ 2566844672 pOdometer_Drive_Bit "Description: Each State A->B or B->A change indicates the vehicle has moved 40 m since the previous one. However, since the message is sent at regular 100 ms intervals, State A and B each occur multiple times consecutively (a minimum ";
CM_ SG_ 2566844672 pCC_Checksum "Description: XOR of bytes 0-6 (ensures data is valid before use). 
Could not parse SPN data type, please add:Type: Status
Parsed from -014. ";
CM_ SG_ 2566844672 WheelBased_Vehicle_Speed "Description:Speed of the vehicle as calculated from wheel or tailshaft speed.
Note: Parsed from J1939DA.";
CM_ SG_ 2566844672 Cruise_Control_Resume_Switch "Description:Switch signal of the cruise control activator which indicates that the activator is in the position resume. 00b = Cruise control activator not in the position resume 01b = Cruise control activator in position resu";
CM_ SG_ 2566844672 Cruise_Control_Accelerate_Switch "Description:Switch signal of the cruise control activator which indicates that the activator is in the position accelerate. 00b = Cruise control activator not in the position accelerate 01b = Cruise control activator in p";
CM_ SG_ 2566844672 pCruise_Enable_Status "Description: The Cruise Control System has been enabled by the operator. (Amber Light) ";
CM_ SG_ 2566844672 Parking_Brake_Switch "Description:Switch signal which indicates when the parking brake is set. In general the switch actuated by the operator's park brake control, whether a pedal, lever or other control mechanism (see also SPN 619 and 5275). 00b = Parkin";
CM_ SG_ 2566844672 Cruise_Control_Coast_Decelerate_ "Description:Switch signal of the cruise control activator which indicates that the activator is in the position coast (decelerate). 00b = Cruise control activator not in the position coast 01b = Cruise control activator i";
CM_ BO_ 2566844928 "Name: Fuel Economy (Liquid)
Description: Parsed from -014. ";
CM_ SG_ 2566844928 Engine_Instantaneous_Fuel_Econom "Description:Current fuel economy at current vehicle velocity. FB00h = Infinite (for example, during engine motoring)
Note: Parsed from J1939DA.";
CM_ SG_ 2566844928 Engine_Fuel_Rate "Description:Amount of fuel consumed by engine per unit of time. NOTE - See SPN 1600 for alternate resolution.
Note: Parsed from J1939DA.";
CM_ SG_ 2566844928 Engine_Average_Fuel_Economy "Description:Average of instantaneous fuel economy for that segment of vehicle operation of interest.
Note: Parsed from J1939DA.";
CM_ SG_ 2566844928 Engine_Throttle_Valve_1_Position "Description:The position of the valve used to regulate the supply of a fluid, usually air or fuel/air mixture, to an engine. 0% represents no supply and 100% is full supply.
Note: Parsed from J1939DA.";
CM_ BO_ 2566843904 "Name: Engine Temperature
Description: Parsed from -014. ";
CM_ SG_ 2566843904 Engine_Coolant_Temperature "Description:Temperature of liquid found in engine cooling system.
Note: Parsed from J1939DA.";
CM_ SG_ 2566843904 Engine_Turbocharger_1_Oil_Temper "Description:Temperature of the turbocharger lubricant.
Note: Parsed from J1939DA.";
CM_ SG_ 2566843904 Engine_Fuel_1_Temperature_1 "Description:Temperature of fuel (or gas) of the first fuel type. See SPN 3468 for a second temperature measurement of the first fuel type.
Note: Parsed from J1939DA.";
CM_ SG_ 2566843904 Engine_Oil_Temperature_1 "Description:Temperature of the engine lubricant. Note: If there is only one engine oil temperature measurement, this SP should be used. This is the SP that is typically displayed on an on-highway truck instrument cluster. See als";
CM_ BO_ 2566846208 "Name: Vehicle Electrical Power 1
Description: Parsed from -014. ";
CM_ SG_ 2566846208 Key_Switch_Battery_Potential "Description:Battery potential measured at the input of the electronic control unit supplied through a key switch or similar switching device.
Note: Parsed from J1939DA.";
CM_ SG_ 2566846208 Alternator_Current "Description:Measure of electrical current flow from the alternator. Alternator Current (High Range/Resolution) parameter SPN 1795 has a higher range and resolution of the same parameter.
Note: Parsed from J1939DA.";
CM_ SG_ 2566846208 Charging_System_Potential_Voltag "Description:Electrical potential measured at the charging system output. The charging system may be any device charging the batteries. This includes alternators, generators, solid state charger and other charging devices.";
CM_ SG_ 2566846208 SLI_Battery_1_Net_Current "Description:Net flow of electrical current into/out of the first battery or first set of batteries used for starting the engine, for lighting, and for ignition (SLI). If more than one battery is included in the first set of batt";
CM_ SG_ 2566846208 Battery_Potential__Power_Input_1 "Description:This parameter measures the first source of battery potential as measured at the input of the ECU/actuator etc. coming from one or more batteries, irrespective of the distance between the component and the bat";
CM_ BO_ 2566845952 "Name: Intake/Exhaust Conditions 1
Description: Parsed from -014. ";
CM_ SG_ 2566845952 Engine_Intake_Manifold_1_Pressur "Description:The gage pressure measurement of the air intake manifold. If there are multiple air pressure sensors in the intake stream, this is the last one in flow direction before entering the combustion chamber. This sh";
CM_ SG_ 2566845952 Engine_Intake_Manifold_1_Tempera "Description:Temperature of pre-combustion air found in intake manifold of engine air supply system.
Note: Parsed from J1939DA.";
CM_ SG_ 2566845952 Engine_Intake_Air_Pressure "Description:Absolute air pressure at input port to intake manifold or air box.
Note: Parsed from J1939DA.";
CM_ SG_ 2566845952 Engine_Exhaust_Temperature "Description:Temperature of combustion byproducts leaving the engine. See SPNs 2433, 2434, 5969 and 5970 for engines with more than one exhaust temperature measurement.
Note: Parsed from J1939DA.";
CM_ BO_ 2566847488 "Name: Dash Display
Description: Parsed from -014. ";
CM_ SG_ 2566847488 Fuel_Level_1 "Description:Ratio of volume of fuel to the total volume of fuel storage container. When Fuel Level 2 (SPN 38) is not used, Fuel Level 1 represents the total fuel in all fuel storage containers. When Fuel Level 2 is used, Fuel Level 1 represe";
CM_ BO_ 2566845696 "Name: Ambient Conditions
Description: Parsed from -014. ";
CM_ SG_ 2566845696 Ambient_Air_Temperature "Description:Temperature of air surrounding vehicle.
Note: Parsed from J1939DA.";
CM_ SG_ 2566845696 Barometric_Pressure "Description:Absolute air pressure of the atmosphere.
Note: Parsed from J1939DA.";
CM_ SG_ 2566845696 Road_Surface_Temperature "Description:Indicated temperature of road surface over which vehicle is operating.
Note: Parsed from J1939DA.";
CM_ SG_ 2566845696 Engine_Intake_1_Air_Temperature "Description:Temperature of air entering vehicle air induction system.
Note: Parsed from J1939DA.";
CM_ BO_ 2365523456 "Name: pModule Control Message
Description: Parsed from -014. ";
CM_ SG_ 2365523456 pModule_Control_Applied_State "Description: Indicates the requester&rsquo;s command to control wake state of other modules. Partial Wakeup and Full Wakeup are to be defined per each module.

 ";
CM_ SG_ 2365523456 pModule_Control_Command_Destinat "Description: Indicates which source address the requester is commanding. Destination address FFh is used to indicate that all source addresses should obey the Module Control Command State signal. FFFFh indicates &ldquo;no";
CM_ SG_ 2365523456 pModule_Control_Command_State "Description: Indicates the requester&rsquo;s command to control wake state of other modules. Each state to be defined per each module. ";
CM_ SG_ 2365523456 pModule_Control_Message_Checksum "Description: Message checksum that is calculated as follows:
Intermediate Checksum =
Byte1 + Byte2 + Byte3 + Byte4 + Byte5 + Byte6 + Byte7 + (8.1 Nibble & 0x0F) + Message ID Low Byte + Message ID Mid Low Byte + Message ";
CM_ BO_ 2231309056 "Name: EPCU #1 Torque Control Message
Description: First or only on-board device converting torque commands to current commands in an electric vehicle system. This contains the mode in which the Propulsion Control Unit is commanded as well as the variabl";
CM_ SG_ 2231309056 pEPCU1_Message_Counter "Description: Counter to verify latest message, counts 0-15

Could not parse SPN data type, please add:Type: Measured
Parsed from -014. ";
CM_ SG_ 2231309056 pElectric_Propulsion_Control_Uni "Description: Bits dictating the commanded control mode of the first or only on-board device converting torque commands to current commands in an electric vehicle system. ";
CM_ SG_ 2231309056 pEPCU1_Torque_Demand "Description: Commanded Torque value to the electric propulsion control unit (motor controller)

Could not parse SPN data type, please add:Type: Measured
Parsed from -014. ";
CM_ SG_ 2231309056 pEPCU1_Counter_Limit_Torque "Description: Counter torque limit value to the electric propulsion control unit (motor controller)
Could not parse SPN data type, please add:Type: Measured
Parsed from -014. ";
CM_ SG_ 2231309056 pEPCU1_Speed_Limit "Description: Speed limit value to the electric propulsion control unit (motor controller)

Could not parse SPN data type, please add:Type: Measured
Parsed from -014. ";
CM_ SG_ 2231309056 pTorque_Message_Checksum "Description: Checksum is calculated by taking XOR of bytes from 1 to 7.
Could not parse SPN data type, please add:Type: Status
Parsed from -014. ";
CM_ BO_ 2365529088 "Name: pFan Control
Description: Parsed from -014. ";
CM_ SG_ 2365529088 pRequested_Percent_Fan_1_Duty_Cy "Description: Fan duty cycle. A two state fan (off/on) will use 0% and 100% respectively. A three state fan (off/intermediate/on) will use 0%, 50% and 100% respectively. A variable speed fan will use 0% to 100%.
Could not";
CM_ SG_ 2365529088 pFan_1_Direction_Command "Description: Direction command to the Supplemental Fan. Fan can be commanded to run forward or reverse. ";
CM_ BO_ 2365530368 "Name: pTorque/Speed Control Feedback 1
Description: Feedback from the engine or motor controller to be used in conjunction with making torque/speed requests. To be used with PGN 65312 and PGN 65314.
Parsed from -014. ";
CM_ SG_ 2365530368 pMessage_Checksum "Description: Message checksum that is calculated as follows:
Intermediate Checksum =
Byte1 + Byte2 + Byte3 + Byte4 + Byte5 + Byte6 + Byte7 + (Message Counter & 0x0F) + Message ID Low Byte + Message ID Mid Low Byte + Message ID Mid Hig";
CM_ SG_ 2365530368 pEngine_Torque__Actual "Description: Indication of the actual engine or motor output torque. Estimated torque is acceptable if actual is not available.
Could not parse SPN data type, please add:Type: Measured
Parsed from -014. ";
CM_ SG_ 2365530368 pMessage_Counter "Description: Message counter that increments by one for each transmission from 0 to 15 and then rolls over.
Could not parse SPN data type, please add:Type: Status
Parsed from -014. ";
CM_ SG_ 2365530368 pSource_Address_of_Controlling_D "Description: Indication of the source address of the device from which the torque/speed request is being honored. If an internal torque request is being honored, the controller will transmit its own source address.
Could";
CM_ SG_ 2365530368 pEngine_Torque__Driver_Demanded "Description: Indication of the driver demanded engine or motor output torque.
Could not parse SPN data type, please add:Type: Measured
Parsed from -014. ";
CM_ SG_ 2365530368 pEngine_Speed "Description: Indication of the current engine or motor speed.
Could not parse SPN data type, please add:Type: Measured
Parsed from -014. ";
CM_ BO_ 2566857216 "Name: pTorque/Speed Control Feedback 2
Description: Feedback from the engine or motor controller to be used in conjunction with making torque/speed requests. To be used with PGN 65312 and PGN 65313.
Parsed from -014. ";
CM_ SG_ 2566857216 pRaw_Brake_Status "Description: Indication of a user&rsquo;s intent to apply the brake without any debounce on the signal. ";
CM_ SG_ 2566857216 pVehicle_Speed "Description: Indication of the current vehicle speed.
Could not parse SPN data type, please add:Type: Measured
Parsed from -014. ";
CM_ SG_ 2566857216 pEngine_TorqueSpeed_Control_Requ "Description: Contains reasons for the ECM denying engine control requests. ";
CM_ SG_ 2566857216 pEngine_Torque__Instantaneous_Ma "Description: Maximum instantaneous torque available from the engine.
Could not parse SPN data type, please add:Type: Calculated
Parsed from -014. ";
CM_ SG_ 2566857216 pEngine_Torque__Instantaneous_Mi "Description: Minimum instantaneous torque available from the engine.
Could not parse SPN data type, please add:Type: Calculated
Parsed from -014. ";
CM_ SG_ 2566857216 pNormalized_Accelerator_Position "Description: Indication of the current accelerator pedal position normalized to 0 to 100 %.
Could not parse SPN data type, please add:Type: Measured
Parsed from -014. ";
CM_ BO_ 2566858752 "Name: pEngine Vehicle Information
Description: Used to communicate parameters 
Parsed from -014. ";
CM_ SG_ 2566858752 pEngine_Shutdown_Temp "Description: Threshold at which engine shutdown is performed
Could not parse SPN data type, please add:Type: Measured
Parsed from -014. ";
CM_ SG_ 2566858752 pEngine_Top_Speed "Description: Engine Speed Limit (Red Line)
Could not parse SPN data type, please add:Type: Measured
Parsed from -014. ";
CM_ SG_ 2566858752 pEngine_Hot_Lamp_On "Description: Threshold for when the Engine Hot lamp should turn on
Could not parse SPN data type, please add:Type: Measured
Parsed from -014. ";
CM_ BO_ 2365532672 "Name: pTorque/Speed Control Feedback 3
Description: Used to transmit to torque and engine speed control information from the ECM.
Parsed from -014. ";
CM_ SG_ 2365532672 pNormalized_Accelerator_Position "Description: Indication of the current accelerator pedal position normalized to 0 to 100 %. This message also indicates what the accelerator pedal position would be during cruise control. This message also corrects for al";
CM_ SG_ 2365532672 pMessageChecksum "Description: Used to verify the signal path from Transmitter up to the Application Software layer of the Receiver.
Calculated using the CRC8 0xEA Polynomial formula. Data used in calculation is [Message ID][Data Bytes 1-7].
Could not p";
CM_ SG_ 2365532672 pEngine_Torque__Driver_Demanded_ "Description: Driver torque demanded torque calculated from demanded throttle position after drivability filter. 
Could not parse SPN data type, please add:Type: Calculated
Parsed from -014. ";
CM_ SG_ 2365532672 pEngine_Drag_Torque "Description: Summation of engine friction + pumping work required for current engine speed + manifold pressure differential.
Could not parse SPN data type, please add:Type: Calculated
Parsed from -014. ";
CM_ SG_ 2365532672 pMessageCounter "Description: Used to verify the signal path from Transmitter up to the Application Software layer of the Receiver.
Transmitter increments the count for every message transmission, automatically rolling over at 15.
Could not parse offset";
CM_ BO_ 2365532928 "Name: pTorque/Speed Control Feedback 4
Description: Used to transmit to torque and engine speed control information from the ECM.
Parsed from -014. ";
CM_ SG_ 2365532928 pMessageChecksum "Description: Used to verify the signal path from Transmitter up to the Application Software layer of the Receiver.
Calculated using the CRC8 0xEA Polynomial formula. Data used in calculation is [Message ID][Data Bytes 1-7].
Could not p";
CM_ SG_ 2365532928 pEngine_Speed__Target_Idle "Description: Target engine speed for idle speed control (current calibration allows for increased idle speed w.r.t cold coolant temp).
Could not parse SPN data type, please add:Type: Status
Parsed from -014. ";
CM_ SG_ 2365532928 pEngine_Torque__Minimum "Description: Minimum torque at current engine speed using air path to arrive at minimum throttle allowed (at current engine speed estimates what minimum torque is available keeping fueling on and allowing throttle to close to its ";
CM_ SG_ 2365532928 pMessageCounter "Description: Used to verify the signal path from Transmitter up to the Application Software layer of the Receiver.
Transmitter increments the count for every message transmission, automatically rolling over at 15.
Could not parse offset";
CM_ BO_ 2566860032 "Name: pInstrument Special Message
Description: Used to command special messages for the specific LCD Display using 2 bit status SPN�s only. The intention is to command specific warnings to the user when the vehicle is in specific states determined by th";
CM_ SG_ 2566860032 pSpecial_Msg_12 "Description: SPN Grouping contain Special Instruction Messages for LCD Display. See breakdown of PGN 65325 for further definition. ";
CM_ SG_ 2566860032 pSpecial_Msg_28 "Description: SPN Grouping contain Special Instruction Messages for LCD Display. See breakdown of PGN 65325 for further definition. ";
CM_ SG_ 2566860032 pSpecial_Msg_11 "Description: SPN Grouping contain Special Instruction Messages for LCD Display. See breakdown of PGN 65325 for further definition. ";
CM_ SG_ 2566860032 pSpecial_Msg_26 "Description: SPN Grouping contain Special Instruction Messages for LCD Display. See breakdown of PGN 65325 for further definition. ";
CM_ SG_ 2566860032 pSpecial_Msg_24 "Description: SPN Grouping contain Special Instruction Messages for LCD Display. See breakdown of PGN 65325 for further definition. ";
CM_ SG_ 2566860032 pSpecial_Msg_21 "Description: SPN Grouping contain Special Instruction Messages for LCD Display. See breakdown of PGN 65325 for further definition. ";
CM_ SG_ 2566860032 pSpecial_Msg_18 "Description: SPN Grouping contain Special Instruction Messages for LCD Display. See breakdown of PGN 65325 for further definition. ";
CM_ SG_ 2566860032 pSpecial_Msg_19 "Description: SPN Grouping contain Special Instruction Messages for LCD Display. See breakdown of PGN 65325 for further definition. ";
CM_ SG_ 2566860032 pSpecial_Msg_1_Riding_with_Brake "Description: SPN Grouping contain Special Instruction Messages for LCD Display. See breakdown of PGN 65325 for further definition. ";
CM_ SG_ 2566860032 pSpecial_Msg_2_Regulator_Overhea "Description: SPN Grouping contain Special Instruction Messages for LCD Display. See breakdown of PGN 65325 for further definition. ";
CM_ SG_ 2566860032 pSpecial_Msg_3_Regulator_Overhea "Description: SPN Grouping contain Special Instruction Messages for LCD Display. See breakdown of PGN 65325 for further definition. ";
CM_ SG_ 2566860032 pSpecial_Msg_4_Regulator_Overhea "Description: SPN Grouping contain Special Instruction Messages for LCD Display. See breakdown of PGN 65325 for further definition. ";
CM_ SG_ 2566860032 pSpecial_Msg_5_Engine_Warmup_Com "Description: SPN Grouping contain Special Instruction Messages for LCD Display. See breakdown of PGN 65325 for further definition. ";
CM_ SG_ 2566860032 pSpecial_Msg_6_Engine_Knock__Mod "Description: SPN Grouping contain Special Instruction Messages for LCD Display. See breakdown of PGN 65325 for further definition. ";
CM_ SG_ 2566860032 pSpecial_Msg_8_Low_Coolant_Warni "Description: SPN Grouping contain Special Instruction Messages for LCD Display. See breakdown of PGN 65325 for further definition. ";
CM_ SG_ 2566860032 pSpecial_Msg_7_Engine_Knock__Mos "Description: SPN Grouping contain Special Instruction Messages for LCD Display. See breakdown of PGN 65325 for further definition. ";
CM_ SG_ 2566860032 pSpecial_Msg_9_Transmission_Temp "Description: SPN Grouping contain Special Instruction Messages for LCD Display. See breakdown of PGN 65325 for further definition. ";
CM_ SG_ 2566860032 pSpecial_Msg_10_Reverse_Speed_Li "Description: SPN Grouping contain Special Instruction Messages for LCD Display. See breakdown of PGN 65325 for further definition. ";
CM_ SG_ 2566860032 pSpecial_Msg_13_Belt_Burn_Warnin "Description: SPN Grouping contain Special Instruction Messages for LCD Display. See breakdown of PGN 65325 for further definition. ";
CM_ SG_ 2566860032 pSpecial_Msg_14_Park_Brake_Warni "Description: SPN Grouping contain Special Instruction Messages for LCD Display. See breakdown of PGN 65325 for further definition. ";
CM_ SG_ 2566860032 pSpecial_Msg_15_TCM_Comm_Loss "Description: SPN Grouping contain Special Instruction Messages for LCD Display. See breakdown of PGN 65325 for further definition. ";
CM_ SG_ 2566860032 pSpecial_Msg_16_TCM_Pump_Priming "Description: SPN Grouping contain Special Instruction Messages for LCD Display. See breakdown of PGN 65325 for further definition. ";
CM_ SG_ 2566860032 pSpecial_Msg_17_Request_User_to_ "Description: SPN Grouping contain Special Instruction Messages for LCD Display. See breakdown of PGN 65325 for further definition. ";
CM_ SG_ 2566860032 pSpecial_MSG_20_Fuel_Door_Open_E "Description: SPN Grouping contain Special Instruction Messages for LCD Display. See breakdown of PGN 65325 for further definition. ";
CM_ SG_ 2566860032 pSpecial_MSG_22_Clutch_Overtemp "Description: SPN Grouping contain Special Instruction Messages for LCD Display. See breakdown of PGN 65325 for further definition. ";
CM_ SG_ 2566860032 pSpecial_MSG_23_Exhaust_Valve_Ch "Description: SPN Grouping contain Special Instruction Messages for LCD Display. See breakdown of PGN 65325 for further definition. ";
CM_ SG_ 2566860032 pSpecial_MSG_25_Engine_Idle_Shut "Description: SPN Grouping contain Special Instruction Messages for LCD Display. See breakdown of PGN 65325 for further definition. ";
CM_ SG_ 2566860032 pSpecial_MSG_27_Overboost_Condit "Description: SPN Grouping contain Special Instruction Messages for LCD Display. See breakdown of PGN 65325 for further definition. ";
CM_ SG_ 2566860032 pSpecial_Msg_31_Engine_Tip_Over_ "Description: Engine Tip Over Lockout Special Message designed to indicate to the instrument cluster that an engine tip over condition is present and that the engine is currently preventing the user from starting the engin";
CM_ SG_ 2566860032 pSpecial_Msg_32_Engine_Tip_Over_ "Description: Engine Tip Over Lockout - Heal State Special Message designed to communicate to the instrument cluster that the vehicle is still currently in a engine tip over condition but is in the process of it being heal";
CM_ BO_ 2566860288 "Name: pDirect Lamp Control 1
Description: Used to directly control lamp states in the gauge using 3 bit status SPNs.
Parsed from -014. ";
CM_ SG_ 2566860288 pAutonomous_Available_Status "Description: Autonomous Available Status ";
CM_ SG_ 2566860288 pBrake_Failure_Lamp_Status "Description: Indicating Brake Failure (Red Circle w/ an Exclamation Mark Inside). ";
CM_ SG_ 2566860288 pBattery_Lamp_Status "Description: Battery lamp indicator status.  ";
CM_ SG_ 2566860288 pOil_Pressure_Lamp_Status "Description: 
Low Oil Pressure lamp indicator status.  ";
CM_ SG_ 2566860288 pOil_Lamp_Status "Description: Oil lamp indicator status.  ";
CM_ SG_ 2566860288 pTransmission_Lamp_Status "Description: Indicating Transmission Fault (Amber Gear w/ an Exclamation Mark Inside). ";
CM_ SG_ 2566860288 pPark_Brake_Lamp_Status "Description: Indicating Park Brake Set (Red Circle w/ a P Inside) ";
CM_ SG_ 2566860288 pHot_Lamp_Status "Description: Hot lamp indicator status.  ";
CM_ SG_ 2566860288 pHigh_Beam_Status "Description: High Beam indicator status ";
CM_ BO_ 2566865664 "Name: pAdjusted Speed Limit (ASL)
Description: 
Parsed from -014. ";
CM_ SG_ 2566865664 pASL_Enable "Description: Indicates whether or not the ASL has been enabled. ";
CM_ SG_ 2566865664 pASL_Maximum_Speed "Description: The maximum set speed allowed by ASL feature as measured in km/h/bit.
Could not parse SPN data type, please add:Type: Measured
Parsed from -014. ";
CM_ SG_ 2566865664 pASL_Set_Speed "Description: The current speed limit when ASL is active as measured in km/h/bit.
Could not parse SPN data type, please add:Type: Measured
Parsed from -014. ";
CM_ SG_ 2566865664 pASL_Speed_Decrement "Description: Signal to decrement the speed value saved in the ECM. ";
CM_ SG_ 2566865664 pASL_Speed_Increment "Description: Signal to increment the speed value saved in the ECM. ";
CM_ SG_ 2566865664 pASL_Minimum_Speed "Description: The minimum set speed allowed by ASL feature as measured in km/h/bit.
Could not parse SPN data type, please add:Type: Measured
Parsed from -014. ";
CM_ BO_ 2432656640 "Name: pOperator Switch Status
Description: Parsed from -014. ";
CM_ SG_ 2432656640 Key_Fob_Unlock_Button_Status "Description: These group of SPN&rsquo;s contain the information for the Operator Switches. See PGN 65380 breakdown for definition of each button. ";
CM_ SG_ 2432656640 Homelink_2 "Description: These group of SPN&rsquo;s contain the information for the Operator Switches. See PGN 65380 breakdown for definition of each button. ";
CM_ SG_ 2432656640 Side_Stand_Switch "Description: ";
CM_ SG_ 2432656640 Key_Fob_Lock_Button_Status "Description: These group of SPN&rsquo;s contain the information for the Operator Switches. See PGN 65380 breakdown for definition of each button. ";
CM_ SG_ 2432656640 Windshield__2_Down "Description: These group of SPN&rsquo;s contain the information for the Operator Switches. See PGN 65380 breakdown for definition of each button. ";
CM_ SG_ 2432656640 Turn__3_Cancel "Description: These group of SPN&rsquo;s contain the information for the Operator Switches. See PGN 65380 breakdown for definition of each button. ";
CM_ SG_ 2432656640 Reverse "Description: These group of SPN&rsquo;s contain the information for the Operator Switches. See PGN 65380 breakdown for definition of each button. ";
CM_ SG_ 2432656640 Hazard "Description: These group of SPN&rsquo;s contain the information for the Operator Switches. See PGN 65380 breakdown for definition of each button. ";
CM_ SG_ 2432656640 Homelink_1 "Description: These group of SPN&rsquo;s contain the information for the Operator Switches. See PGN 65380 breakdown for definition of each button. ";
CM_ SG_ 2432656640 Windshield__1_Up "Description: These group of SPN&rsquo;s contain the information for the Operator Switches. See PGN 65380 breakdown for definition of each button. ";
CM_ SG_ 2432656640 Front_Brake_Switch "Description: Indicates the status of the front brake switch ";
CM_ SG_ 2432656640 Instrument_Cluster_Control__2 "Description: These group of SPN&rsquo;s contain the information for the Operator Switches. See PGN 65380 breakdown for definition of each button. ";
CM_ SG_ 2432656640 Chassis_Unlock_Button_Status "Description: These group of SPN&rsquo;s contain the information for the Operator Switches. See PGN 65380 breakdown for definition of each button. ";
CM_ SG_ 2432656640 Power_Button "Description: These group of SPN&rsquo;s contain the information for the Operator Switches. See PGN 65380 breakdown for definition of each button. ";
CM_ SG_ 2432656640 RunStop_Switch "Description: These group of SPN&rsquo;s contain the information for the Operator Switches. See PGN 65380 breakdown for definition of each button. ";
CM_ SG_ 2432656640 Headlamp__2_High "Description: These group of SPN&rsquo;s contain the information for the Operator Switches. See PGN 65380 breakdown for definition of each button. ";
CM_ SG_ 2432656640 Instrument_Cluster_Control__1 "Description: These group of SPN&rsquo;s contain the information for the Operator Switches. See PGN 65380 breakdown for definition of each button. ";
CM_ SG_ 2432656640 Clutch_Switch "Description: These group of SPN&rsquo;s contain the information for the Operator Switches. See PGN 65380 breakdown for definition of each button. ";
CM_ SG_ 2432656640 Start "Description: These group of SPN&rsquo;s contain the information for the Operator Switches. See PGN 65380 breakdown for definition of each button. ";
CM_ SG_ 2432656640 Headlamp__3_Driving "Description: These group of SPN&rsquo;s contain the information for the Operator Switches. See PGN 65380 breakdown for definition of each button. ";
CM_ SG_ 2432656640 Cruise__2_Set "Description: These group of SPN&rsquo;s contain the information for the Operator Switches. See PGN 65380 breakdown for definition of each button. ";
CM_ SG_ 2432656640 Windshield_Wiper "Description: These group of SPN&rsquo;s contain the information for the Operator Switches. See PGN 65380 breakdown for definition of each button. ";
CM_ SG_ 2432656640 Fog "Description: These group of SPN&rsquo;s contain the information for the Operator Switches. See PGN 65380 breakdown for definition of each button. ";
CM_ SG_ 2432656640 Cruise__3_Accel "Description: These group of SPN&rsquo;s contain the information for the Operator Switches. See PGN 65380 breakdown for definition of each button. ";
CM_ SG_ 2432656640 Horn "Description: These group of SPN&rsquo;s contain the information for the Operator Switches. See PGN 65380 breakdown for definition of each button. ";
CM_ SG_ 2432656640 Turn__2_Right "Description: These group of SPN&rsquo;s contain the information for the Operator Switches. See PGN 65380 breakdown for definition of each button. ";
CM_ SG_ 2432656640 Cruise__1_On "Description: These group of SPN&rsquo;s contain the information for the Operator Switches. See PGN 65380 breakdown for definition of each button. ";
CM_ SG_ 2432656640 Turn__1_Left "Description: These group of SPN&rsquo;s contain the information for the Operator Switches. See PGN 65380 breakdown for definition of each button. ";
CM_ SG_ 2432656640 Throttle_Safety_Switch__1 "Description: These group of SPN&rsquo;s contain the information for the Operator Switches. See PGN 65380 breakdown for definition of each button. ";
CM_ SG_ 2432656640 Headlamp__1_Low "Description: These group of SPN&rsquo;s contain the information for the Operator Switches. See PGN 65380 breakdown for definition of each button. ";
CM_ SG_ 2432656640 Chassis_Lock_Switch_Status "Description:Created due to CMS fault code using this SPN";
CM_ SG_ 2432656640 Fuel_Door_Unlock_Button_Status "Description:Displays the status of the Fuel Door Unlock button. See PGN 65380 breakdown for the definition of each button.";
CM_ BO_ 2566876416 "Name: pDrive Mode (ETC)
Description: Parsed from -014. ";
CM_ SG_ 2566876416 pFarm_Mode_Set_Speed "Description: The current speed limit when work mode is active as measured in km/h/bit.
Could not parse SPN data type, please add:Type: Measured
Parsed from -014. ";
CM_ SG_ 2566876416 pDrive_Mode_Requested "Description: ASCII Representation of Drive Mode Requested. 
Could not parse SPN data type, please add:Type: Measured
Parsed from -014. ";
CM_ SG_ 2566876416 pFarm_Mode_Maximum_Speed "Description: The maximum set speed allowed by work mode as measured in km/h/bit.
Could not parse SPN data type, please add:Type: Measured
Parsed from -014. ";
CM_ SG_ 2566876416 pDrive_Mode_Commanded "Description: ASCII Representation of Drive Mode Commanded.
Could not parse SPN data type, please add:Type: Status
Parsed from -014. ";
CM_ SG_ 2566876416 pEngine_Brake_Active "Description: Indicates whether or not the engine control module is in engine braking mode. ";
CM_ SG_ 2566876416 pFarm_Mode_Minimum_Speed "Description: The minimum set speed allowed by work mode as measured in km/h/bit.
Could not parse SPN data type, please add:Type: Measured
Parsed from -014. ";
CM_ SG_ 2566876416 pFoot_On_Cruise_Enable "Description: Indicates whether or not the Foot on Cruise has been enabled. ";
CM_ SG_ 2566876416 pFarm_Mode_Speed_Decrement "Description: Signal to decrement the speed value saved in the ECM. ";
CM_ SG_ 2566876416 pEngine_Brake_Enabled "Description: Indicates whether or not Engine Braking has been enabled. ";
CM_ SG_ 2566876416 pCylDeAc_Enabled "Description: Indicates whether or not CylDeAc has been enabled. ";
CM_ SG_ 2566876416 pFarm_Mode_Speed_Increment "Description: Signal to increment the speed value saved in the ECM. ";
CM_ SG_ 2566876416 pCylDeAc_Active "Description: Indicates whether or not the engine control module has deliberately deactivated cylinder(s). ";
CM_ BO_ 2633984768 "Name: pVehicle Initialization Parameters
Description:Parsed from -014.";
CM_ SG_ 2633984768 pInstrumentation_Backlight_Inten "Description: Intensity (brightness) of instrumentation backlighting, 0% is no backlight and 100% is the maximum brightness the gauge is capable of. 
Could not parse SPN data type, please add:Type: Status
Parsed from -01";
CM_ SG_ 2633984768 pFuel_Economy_Data_Source "Description: Fuel Economy data determination. Determines where fuel economy (Range, Instantaneous and Average fuel economy) is calculated.  ";
CM_ SG_ 2633984768 pActive_Decent_Control_ADC_Mode_ "Description: Used to let devices know if the vehicle is equipped with a momentary driveline mode switch and ADC ";
CM_ SG_ 2633984768 pFuel_Level_Data_Source "Description: Fuel consumption data determination. Determines where the fuel sender resistive input is read ";
CM_ SG_ 2633984768 pVehicle_Units_Configuration "Description: Vehicle Units Configuration: MPH = Miles per Hour for speed & miles for distance, km/h = Kilometers per Hour & Kilometers for distance, Fahrenheit = temperature in degrees Fahrenheit, Celsius = temperature in deg";
CM_ SG_ 2633984768 pLow_Fuel_Light_ON_Percentage "Description: Fuel percentage at which to turn the Low Fuel Light ON 
Could not parse SPN data type, please add:Type: Status
Parsed from -014. ";
CM_ SG_ 2633984768 pSeat_Belt_Input_Source "Description: Determines what component reads the seat belt switch input.  ";
CM_ SG_ 2633984768 pAWD_Mode_Availability "Description: Used to let devices know if the vehicle is equipped with a momentary driveline mode switch and AWD ";
CM_ SG_ 2633984768 pWarning_Lamp_Intensity "Description: Intensity (brightness) of warning lamp(s) which have the ability to be adjusted, 0% is warning lamp disabled and 100% is the maximum brightness the warning lamp(s) are capable of. 
Could not parse SPN data type, plea";
CM_ SG_ 2633984768 pTurf_Mode_Availability "Description: Used to let devices know if the vehicle is equipped with with a momentary driveline mode switch and rear diff solenoid.  ";
CM_ SG_ 2633984768 pFuel_Tank_Volume "Description: Total volume of fuel tank installed in vehicle
Could not parse SPN data type, please add:Type: Status
Parsed from -014. ";
CM_ SG_ 2633984768 pDisplayed_Speed_Correction_Fact "Description: When the first byte of PGN 65387 is set to any value other than 0x00, the pVIP primary definition will be used. When the first byte of PGN 65387 is set to 0x00, the secondary pVIP definition will be used.
Fo";
CM_ BO_ 2432658432 "Name: pOperator Switch Status
Description: Parsed from -014. ";
CM_ SG_ 2432658432 pFOCC_Checksum "Description: XOR of bytes 0-6 (ensures data is valid before use). 
Could not parse SPN data type, please add:Type: Status
Parsed from -014. ";
CM_ SG_ 2432658432 Drive_Mode__4 "Description: Broadcasting the status of the operator switch.  ";
CM_ SG_ 2432658432 Drive_Mode__2 "Description: Broadcasting the status of the operator switch.  ";
CM_ SG_ 2432658432 pFOCC_Message_Counter "Description: Rolling Counter (ensures updated message is used).
Could not parse SPN data type, please add:Type: Status
Parsed from -014. ";
CM_ SG_ 2432658432 Drivers_Net_Engagement "Description: Broadcasting the status of the operator switch.  ";
CM_ SG_ 2432658432 Foot_On_Cruise_Control_Switch "Description: Broadcasting the status of the operator switch.  ";
CM_ SG_ 2432658432 Drive_Mode__1 "Description: Broadcasting the status of the operator switch.  ";
CM_ SG_ 2432658432 Momentary_Driveline_Left_Press "Description: Broadcasting the status of the operator switch.  ";
CM_ SG_ 2432658432 CylDeAc_Enable "Description: Broadcasting the status of the operator switch for CylDeAc. ";
CM_ SG_ 2432658432 Work_Group_Lock_Switch "Description: Broadcasting the status of the operator switch.  ";
CM_ SG_ 2432658432 Drivers_Seatbelt_Engagement "Description: Broadcasting the status of the operator switch.  ";
CM_ SG_ 2432658432 Drive_Mode__3 "Description: Broadcasting the status of the operator switch.  ";
CM_ SG_ 2432658432 Work_Mode_Switch "Description: Broadcasting the status of the operator switch.  ";
CM_ SG_ 2432658432 Momentary_Driveline_Right_Press "Description: Broadcasting the status of the operator switch.  ";
CM_ SG_ 2432658432 PTO_Mode_Switch_RPM_Control "Description: Broadcasting the status of the operator switch.  ";
CM_ SG_ 2432658432 Operator_Presence_Switch "Description: Broadcasting the status of the operator switch.  ";
CM_ SG_ 2432658432 Tilt_Lock_Switch "Description: Broadcasting the status of the operator switch.  ";
CM_ SG_ 2432658432 Engine_Brake_Enable "Description: Broadcasting the status of the operator switch for Engine Brake. ";
CM_ SG_ 2432658432 Accessory_Relay "Description: ";
CM_ BO_ 2633984512 "Name: pDrive System Status
Description: Parsed from -014. ";
CM_ SG_ 2633984512 pHeated_Grip_Enable "Description: This signal indicates the status of the Heated Grip Enable switch. ";
CM_ SG_ 2633984512 pUser_PIN_Access_Status "Description: This signal indicates if the display/gauge should show the User PIN screen, which allows the user the option of unlocking the vehicle security through the PIN code entry function.  ";
CM_ SG_ 2633984512 pActive_Descent_Control_ADC_Stat "Description: Broadcasting the status of the ADC (active indicates the solenoid is powered). ";
CM_ SG_ 2633984512 pCruise_Control_Set_Status "Description: Broadcasting the status of the Cruise Control Set Status for user indication  ";
CM_ SG_ 2633984512 pTether_Switch_Status "Description: Status of the Tether Switch ";
CM_ SG_ 2633984512 pHigh_Beam_Indicator_Status "Description: Broadcasting the status of the high beam headlight for user indication. ";
CM_ SG_ 2633984512 pLow_Fuel_Indicator_Status "Description: Broadcasting the status of the fuel level for user indication. ";
CM_ SG_ 2633984512 pHeated_Grips_Percentage "Description: Heated Grips Percent On, 0% is Off and 100% is the maximum heat
Could not parse SPN data type, please add:Type: Status
Parsed from -014. ";
CM_ SG_ 2633984512 pSide_Stand_Status "Description: Position of the side stand position when installed on a vehicle. ";
CM_ SG_ 2633984512 pTurf_Mode_Requested "Description: Broadcasting the status of the users request for TURF mode ";
CM_ SG_ 2633984512 pEngine_Idle_Shutdown_Timer "Description: This signal indicates the the amount of time left before the engine is shutdown due to the unattended vehicle engine idle shutdown function.
10-bit Timer:
0 &ndash; 1021 seconds
1022 - Error
1023 - Not Availab";
CM_ SG_ 2633984512 Operator_Not_in_Operating_Statio "Description: The Operator Presence Detection System indicates the operator is not in the correct operating station. ";
CM_ SG_ 2633984512 pAWD_Mode_Requested "Description: Broadcasting the status of the users request for AWD mode ";
CM_ SG_ 2633984512 pHeated_Grips_Up_Switch_Status "Description: This signal indicates the status of the Heated Grip Up switch. ";
CM_ SG_ 2633984512 pTreadle_Neutral_Status "Description: Broadcasting the status of the switch indicating the treadle is/is not in the Neutral position.  ";
CM_ SG_ 2633984512 pHeated_Grips_Down_Switch_Status "Description: This signal indicates the status of the Heated Grip Down switch. ";
CM_ SG_ 2633984512 pPark_Brake_Indicator_Status "Description: Broadcasting the status of the park brake for user indication ";
CM_ SG_ 2633984512 pRWD_Mode_Requested "Description: Broadcasting the status of the users request for RWD mode ";
CM_ SG_ 2633984512 pSeat_Belt_Indicator_Status "Description: Broadcasting the status of the seat belt for user indication ";
CM_ SG_ 2633984512 pSecurity_Light_Immobilizer_Stat "Description: Broadcasting the status of the security system for user indication.  ";
CM_ SG_ 2633984512 ECU_Security_Status "Description: Security Status of an ECU. ";
CM_ SG_ 2633984512 pActive_Decent_Control_ADC_Mode_ "Description: Broadcasting the status of the users request for ADC mode ";
CM_ SG_ 2633984512 pTreadle_Reverse_Status "Description: Broadcasting the status of the switch indicating the treadle is/is not in the Reverse position.  ";
CM_ BO_ 2566875136 "Name: pFuelType
Description: Parsed from -014. ";
CM_ SG_ 2566875136 pFuel_Type_Selected "Description: Indicates the fuel type selected by any means such as a switch or resistive ladder or sensor. ";
CM_ SG_ 2566875136 pFuel_Type_Sensor "Description: Fuel type as measured by a fuel sensor directly measuring the ethanol content
Could not parse SPN data type, please add:Type: Measured
Parsed from -014. ";
CM_ BO_ 2365548032 "Name: Engine Instrument Cluster Fast Update
Description:Description: Required for Engines that are capable of RPM ranges above 8000 rpm in normal operation.
Parsed from -014.";
CM_ SG_ 2365548032 pEngine_Speed_8000RPM "Description: Could not parse SPN data type, please add:Type: Measured
Parsed from -014. ";
CM_ SG_ 2365548032 pCruiseControlStates "Description: This parameter is used to indicate the current state, or mode, of operation by the cruise control device. ";
CM_ SG_ 2365548032 pFuel_Range "Description: Could not parse SPN data type, please add:Type: Status
Parsed from -014. ";
CM_ SG_ 2365548032 pCruiseControlSetSpeed "Description: The cruise control set speed that has been set by the user.

Could not parse SPN data type, please add:Type: Measured
Parsed from -014. ";
CM_ SG_ 2365548032 pStuck_Throttle "Description: Indicates the state of the throttle safety circuit. The throttle struck condition exists when the throttle lever or pedal is not engaged but the rpm is above normal idle. ";
CM_ SG_ 2365548032 pHigh_Idle_State "Description: Indicates whether or not the engine control module has deliberately increased the idle RPM in order to boost system voltage. ";
CM_ BO_ 2231334144 "Name: pRemote Vehicle Control 1
Description:";
CM_ SG_ 2231334144 Normalized_Accelerator_Position_ "Description:Commanded accelerator position as a percent of maximum accelerator position. Could not parse SPN data type, please add:Type: Measured
Parsed from Confidential -014.";
CM_ SG_ 2231334144 Operation_Mode_Status "Description:States defined are as follows:
00 - Manned
01 - Remote
10 - Error Indicator
11 - Not Available
Could not parse SPN data type, please add:Type: Measured
Parsed from Confidential -014.";
CM_ SG_ 2231334144 StartStop_Vehicle_Command "Description:Start or stop command to the vehicle's primary controller. The primary controller could be a hybrid controller or engine controller.  The message acts as a start/stop request for an engine controller.
00 - Not Press";
CM_ SG_ 2231334144 Message_Counter "Description:The message counter is used to detect situations where the transmitting ECU malfunction repeats the same frame all the timeCould not parse SPN data type, please add:Type: Measured
Parsed from Confidential -014.";
CM_ SG_ 2231334144 Checksum "Description:Used to verify the signal path from the transmitting device to the receiving device. The message checksum is calculated using the first 7 data bytes, the message counter and the bytes of the message identifier.Could not parse SPN dat";
CM_ BO_ 2566876672 "Name: pVehicle Fluids
Description: Parsed from -014. ";
CM_ SG_ 2566876672 pHydraulic_Oil_Temp_Status "Description: Indicates status of Hydraulic oil temperature. ";
CM_ SG_ 2566876672 pHydraulic_Oil_Pressure_Status "Description: Indicates status of Hydraulic oil pressure. ";
CM_ SG_ 2566876672 pEngine_Oil_Pressure_Status "Description: Indicates status of engine oil pressure. ";
CM_ BO_ 2566877696 "Name: pVehicle Temperature
Description: Parsed from -014. ";
CM_ SG_ 2566877696 pRight_Hand_Grip_Temperature "Description: Temperature of thermistor in the right hand grip.
Could not parse SPN data type, please add:Type: Measured
Parsed from -014. ";
CM_ SG_ 2566877696 pDriver_Seat_Temperature "Description: Temperature of thermistor in the Driver Seat.
Could not parse SPN data type, please add:Type: Measured
Parsed from -014. ";
CM_ SG_ 2566877696 pPassenger_Seat_Temperature "Description: Temperature of thermistor in the Passenger Seat.
Could not parse SPN data type, please add:Type: Measured
Parsed from -014. ";
CM_ SG_ 2566877696 pLeft_Hand_Grip_Temperature "Description: Temperature of thermistor in the left hand grip.
Could not parse SPN data type, please add:Type: Measured
Parsed from -014. ";
BA_DEF_ SG_  "SigType" ENUM  "Default","Range","RangeSigned","ASCII","Discrete","Control","ReferencePGN","DTC","StringDelimiter","StringLength","StringLengthControl";
BA_DEF_ SG_  "GenSigEVName" STRING ;
BA_DEF_ SG_  "GenSigILSupport" ENUM  "No","Yes";
BA_DEF_ SG_  "GenSigSendType" ENUM  "Cyclic","OnWrite","OnWriteWithRepetition","OnChange","OnChangeWithRepetition","IfActive","IfActiveWithRepetition","NoSigSendType";
BA_DEF_ BO_  "GenMsgCycleTimeFast" INT 0 3600000;
BA_DEF_ BO_  "GenMsgILSupport" ENUM  "No","Yes";
BA_DEF_ BU_  "NmStationAddress" INT 0 255;
BA_DEF_ BO_  "GenMsgSendType" ENUM  "cyclic","spontaneous","cyclicIfActive","spontaneousWithDelay","cyclicAndSpontaneous","cyclicAndSpontaneousWithDelay","spontaneousWithRepetition","cyclicIfActiveAndSpontaneousWD","OnRequest";
BA_DEF_ BO_  "GenMsgRequestable" INT 0 1;
BA_DEF_ BO_  "GenMsgCycleTime" INT 0 3600000;
BA_DEF_ SG_  "SPN" INT 0 524287;
BA_DEF_  "DBName" STRING ;
BA_DEF_  "BusType" STRING ;
BA_DEF_  "ProtocolType" STRING ;
BA_DEF_ BO_  "VFrameFormat" ENUM  "StandardCAN","ExtendedCAN","reserved","J1939PG";
BA_DEF_DEF_  "SigType" "Default";
BA_DEF_DEF_  "GenSigEVName" "Env@Nodename_@Signame";
BA_DEF_DEF_  "GenSigILSupport" "Yes";
BA_DEF_DEF_  "GenSigSendType" "NoSigSendType";
BA_DEF_DEF_  "GenMsgCycleTimeFast" 0;
BA_DEF_DEF_  "GenMsgILSupport" "Yes";
BA_DEF_DEF_  "NmStationAddress" 254;
BA_DEF_DEF_  "GenMsgSendType" "noMsgSendType";
BA_DEF_DEF_  "GenMsgRequestable" 1;
BA_DEF_DEF_  "GenMsgCycleTime" 0;
BA_DEF_DEF_  "SPN" 0;
BA_DEF_DEF_  "DBName" "";
BA_DEF_DEF_  "BusType" "CAN";
BA_DEF_DEF_  "ProtocolType" "J1939";
BA_DEF_DEF_  "VFrameFormat" "J1939PG";
BA_ "SPN" SG_ 2566893871 pRebound_Damping_Percent__RL 523992;
BA_ "SPN" SG_ 2566893871 pRebound_Damping_Percent__FR 523991;
BA_ "SPN" SG_ 2566893871 pRebound_Damping_Percent__FL 523990;
BA_ "SPN" SG_ 2566893871 pRebound_Damping_Percent__RR 523993;
BA_ "SPN" SG_ 2566887215 pVehicle_Event_Status__Accelerat 524189;
BA_ "SPN" SG_ 2566887215 pVehicle_Event_Status__Cornering 524283;
BA_ "SPN" SG_ 2566887215 pVehicle_Event_Status__Braking 524188;
BA_ "SPN" SG_ 2566887215 pSuspension_Mode_Requested 516431;
BA_ "SPN" SG_ 2566887215 pSuspension_Mode_Change_Active 516432;
BA_ "SPN" SG_ 2566887215 pCompression_Damping_Percent__RR 524287;
BA_ "SPN" SG_ 2566887215 pVehicle_Event_Status__Airborne 524187;
BA_ "SPN" SG_ 2566887215 pDemo_Status 516127;
BA_ "SPN" SG_ 2566887215 pCompression_Damping_Percent__RL 524286;
BA_ "SPN" SG_ 2566887215 pCompression_Damping_Percent__FL 524284;
BA_ "SPN" SG_ 2566887215 pSuspension_Mode_Active 524186;
BA_ "SPN" SG_ 2566887215 pCompression_Damping_Percent__FR 524285;
BA_ "SPN" SG_ 2566887215 pVehicle_Event_Status__Pucker 516430;
BA_ "SPN" SG_ 2297441583 Vertical_Acceleration_Figure_of_ 5352;
BA_ "SPN" SG_ 2297441583 Lateral_Acceleration_Figure_of_M 5350;
BA_ "SPN" SG_ 2297441583 Longitudinal_Acceleration_Extend 5348;
BA_ "SPN" SG_ 2297441583 Lateral_Acceleration_Extended_Ra 5347;
BA_ "SPN" SG_ 2297441583 Longitudinal_Acceleration_Figure 5351;
BA_ "SPN" SG_ 2297441583 Vertical_Acceleration_Extended_R 5349;
BA_ "SPN" SG_ 2297441583 Support_Variable_Transmission_Re 5353;
BA_ "SPN" SG_ 2365531183 pEPSReqMod 516147;
BA_ "SPN" SG_ 2633984545 pHeated_Grip_Enable 520366;
BA_ "SPN" SG_ 2633984545 pUser_PIN_Access_Status 516128;
BA_ "SPN" SG_ 2633984545 pActive_Descent_Control_ADC_Stat 524013;
BA_ "SPN" SG_ 2633984545 pCruise_Control_Set_Status 524097;
BA_ "SPN" SG_ 2633984545 pTether_Switch_Status 520600;
BA_ "SPN" SG_ 2633984545 pHigh_Beam_Indicator_Status 524084;
BA_ "SPN" SG_ 2633984545 pLow_Fuel_Indicator_Status 524087;
BA_ "SPN" SG_ 2633984545 pHeated_Grips_Percentage 524096;
BA_ "SPN" SG_ 2633984545 pSide_Stand_Status 524270;
BA_ "SPN" SG_ 2633984545 pTurf_Mode_Requested 524136;
BA_ "SPN" SG_ 2633984545 pEngine_Idle_Shutdown_Timer 516223;
BA_ "SPN" SG_ 2633984545 Operator_Not_in_Operating_Statio 520247;
BA_ "SPN" SG_ 2633984545 pAWD_Mode_Requested 524138;
BA_ "SPN" SG_ 2633984545 pHeated_Grips_Up_Switch_Status 516129;
BA_ "SPN" SG_ 2633984545 pTreadle_Neutral_Status 524017;
BA_ "SPN" SG_ 2633984545 pHeated_Grips_Down_Switch_Status 516130;
BA_ "SPN" SG_ 2633984545 pPark_Brake_Indicator_Status 524271;
BA_ "SPN" SG_ 2633984545 pRWD_Mode_Requested 524137;
BA_ "SPN" SG_ 2633984545 pSeat_Belt_Indicator_Status 524092;
BA_ "SPN" SG_ 2633984545 pSecurity_Light_Immobilizer_Stat 524019;
BA_ "SPN" SG_ 2633984545 ECU_Security_Status 516202;
BA_ "SPN" SG_ 2633984545 pActive_Decent_Control_ADC_Mode_ 524139;
BA_ "SPN" SG_ 2633984545 pTreadle_Reverse_Status 524018;
BA_ "SPN" SG_ 2349465377 Static_Roll_Angle 5582;
BA_ "SPN" SG_ 2365523489 pModule_Control_Applied_State 516096;
BA_ "SPN" SG_ 2365523489 pModule_Control_Command_Destinat 524185;
BA_ "SPN" SG_ 2365523489 pModule_Control_Command_State 524248;
BA_ "SPN" SG_ 2365523489 pModule_Control_Message_Checksum 516097;
BA_ "SPN" SG_ 2633984656 pHeated_Grip_Enable 520366;
BA_ "SPN" SG_ 2633984656 pUser_PIN_Access_Status 516128;
BA_ "SPN" SG_ 2633984656 pActive_Descent_Control_ADC_Stat 524013;
BA_ "SPN" SG_ 2633984656 pCruise_Control_Set_Status 524097;
BA_ "SPN" SG_ 2633984656 pTether_Switch_Status 520600;
BA_ "SPN" SG_ 2633984656 pHigh_Beam_Indicator_Status 524084;
BA_ "SPN" SG_ 2633984656 pLow_Fuel_Indicator_Status 524087;
BA_ "SPN" SG_ 2633984656 pHeated_Grips_Percentage 524096;
BA_ "SPN" SG_ 2633984656 pSide_Stand_Status 524270;
BA_ "SPN" SG_ 2633984656 pTurf_Mode_Requested 524136;
BA_ "SPN" SG_ 2633984656 pEngine_Idle_Shutdown_Timer 516223;
BA_ "SPN" SG_ 2633984656 Operator_Not_in_Operating_Statio 520247;
BA_ "SPN" SG_ 2633984656 pAWD_Mode_Requested 524138;
BA_ "SPN" SG_ 2633984656 pHeated_Grips_Up_Switch_Status 516129;
BA_ "SPN" SG_ 2633984656 pTreadle_Neutral_Status 524017;
BA_ "SPN" SG_ 2633984656 pHeated_Grips_Down_Switch_Status 516130;
BA_ "SPN" SG_ 2633984656 pPark_Brake_Indicator_Status 524271;
BA_ "SPN" SG_ 2633984656 pRWD_Mode_Requested 524137;
BA_ "SPN" SG_ 2633984656 pSeat_Belt_Indicator_Status 524092;
BA_ "SPN" SG_ 2633984656 pSecurity_Light_Immobilizer_Stat 524019;
BA_ "SPN" SG_ 2633984656 ECU_Security_Status 516202;
BA_ "SPN" SG_ 2633984656 pActive_Decent_Control_ADC_Mode_ 524139;
BA_ "SPN" SG_ 2633984656 pTreadle_Reverse_Status 524018;
BA_ "SPN" SG_ 2365473168 Left_Turn_Signal_Lights_Command 2367;
BA_ "SPN" SG_ 2365473168 Alternate_Beam_Head_Light_Comman 2351;
BA_ "SPN" SG_ 2365473168 Right_Turn_Signal_Lights_Command 2369;
BA_ "SPN" SG_ 2365473168 Running_Light_Command 2403;
BA_ "SPN" SG_ 2566860065 pSpecial_Msg_12 516427;
BA_ "SPN" SG_ 2566860065 pSpecial_Msg_28 516373;
BA_ "SPN" SG_ 2566860065 pSpecial_Msg_11 516393;
BA_ "SPN" SG_ 2566860065 pSpecial_Msg_26 516465;
BA_ "SPN" SG_ 2566860065 pSpecial_Msg_24 516463;
BA_ "SPN" SG_ 2566860065 pSpecial_Msg_21 516444;
BA_ "SPN" SG_ 2566860065 pSpecial_Msg_18 516376;
BA_ "SPN" SG_ 2566860065 pSpecial_Msg_19 516442;
BA_ "SPN" SG_ 2566860065 pSpecial_Msg_1_Riding_with_Brake 516382;
BA_ "SPN" SG_ 2566860065 pSpecial_Msg_2_Regulator_Overhea 516384;
BA_ "SPN" SG_ 2566860065 pSpecial_Msg_3_Regulator_Overhea 516385;
BA_ "SPN" SG_ 2566860065 pSpecial_Msg_4_Regulator_Overhea 516386;
BA_ "SPN" SG_ 2566860065 pSpecial_Msg_5_Engine_Warmup_Com 516387;
BA_ "SPN" SG_ 2566860065 pSpecial_Msg_6_Engine_Knock__Mod 516388;
BA_ "SPN" SG_ 2566860065 pSpecial_Msg_8_Low_Coolant_Warni 516390;
BA_ "SPN" SG_ 2566860065 pSpecial_Msg_7_Engine_Knock__Mos 516389;
BA_ "SPN" SG_ 2566860065 pSpecial_Msg_9_Transmission_Temp 516391;
BA_ "SPN" SG_ 2566860065 pSpecial_Msg_10_Reverse_Speed_Li 516392;
BA_ "SPN" SG_ 2566860065 pSpecial_Msg_13_Belt_Burn_Warnin 516381;
BA_ "SPN" SG_ 2566860065 pSpecial_Msg_14_Park_Brake_Warni 516380;
BA_ "SPN" SG_ 2566860065 pSpecial_Msg_15_TCM_Comm_Loss 516379;
BA_ "SPN" SG_ 2566860065 pSpecial_Msg_16_TCM_Pump_Priming 516378;
BA_ "SPN" SG_ 2566860065 pSpecial_Msg_17_Request_User_to_ 516377;
BA_ "SPN" SG_ 2566860065 pSpecial_MSG_20_Fuel_Door_Open_E 516443;
BA_ "SPN" SG_ 2566860065 pSpecial_MSG_22_Clutch_Overtemp 516383;
BA_ "SPN" SG_ 2566860065 pSpecial_MSG_23_Exhaust_Valve_Ch 516375;
BA_ "SPN" SG_ 2566860065 pSpecial_MSG_25_Engine_Idle_Shut 516464;
BA_ "SPN" SG_ 2566860065 pSpecial_MSG_27_Overboost_Condit 516374;
BA_ "SPN" SG_ 2566860065 pSpecial_Msg_31_Engine_Tip_Over_ 516372;
BA_ "SPN" SG_ 2566860065 pSpecial_Msg_32_Engine_Tip_Over_ 516394;
BA_ "SPN" SG_ 2348875520 Engine_Requested_Torque_Fraction 4191;
BA_ "SPN" SG_ 2348875520 Engine_Override_Control_Mode 695;
BA_ "SPN" SG_ 2348875520 Engine_Requested_SpeedSpeed_Limi 898;
BA_ "SPN" SG_ 2348875520 Engine_Requested_Speed_Control_C 696;
BA_ "SPN" SG_ 2348875520 TSC1_Control_Purpose 3350;
BA_ "SPN" SG_ 2348875520 Override_Control_Mode_Priority 897;
BA_ "SPN" SG_ 2348875520 TSC1_Transmission_Rate 3349;
BA_ "SPN" SG_ 2348875520 Engine_Requested_TorqueTorque_Li 518;
BA_ "SPN" SG_ 2364539648 Accelerator_Pedal_Position_1 91;
BA_ "SPN" SG_ 2631728896 Antitheft_Random_Number 1198;
BA_ "SPN" SG_ 2631728896 Antitheft_Encryption_Seed_Presen 1194;
BA_ "SPN" SG_ 2631728896 Antitheft_Password_Valid_Indicat 1195;
BA_ "SPN" SG_ 2631728896 Antitheft_Modify_Password_States 1197;
BA_ "SPN" SG_ 2631728896 Antitheft_Component_Status_State 1196;
BA_ "SPN" SG_ 2364539904 Engine_Speed 190;
BA_ "SPN" SG_ 2364539904 Engine_Demand__Percent_Torque 2432;
BA_ "SPN" SG_ 2364539904 Drivers_Demand_Engine__Percent_T 512;
BA_ "SPN" SG_ 2364539904 Engine_Starter_Mode 1675;
BA_ "SPN" SG_ 2364539904 Source_Address_of_Controlling_De 1483;
BA_ "SPN" SG_ 2364539904 Actual_Engine__Percent_Torque 513;
BA_ "SPN" SG_ 2364539904 Engine_Torque_Mode 899;
BA_ "SPN" SG_ 2565866752 Transmission_Actual_Gear_Ratio 526;
BA_ "SPN" SG_ 2565866752 Transmission_Requested_Range 162;
BA_ "SPN" SG_ 2565866752 Transmission_Current_Range 163;
BA_ "SPN" SG_ 2565866752 Transmission_Current_Gear 523;
BA_ "SPN" SG_ 2565866752 Transmission_Selected_Gear 524;
BA_ "SPN" SG_ 2431708416 Engine_Starter_2_Feedback 7749;
BA_ "SPN" SG_ 2431708416 Engine_Start_Request 7745;
BA_ "SPN" SG_ 2431708416 Engine_Start_Abort_Request 7747;
BA_ "SPN" SG_ 2431708416 Engine_Start_Control_Checksum 7751;
BA_ "SPN" SG_ 2431708416 Transmission_Shift_Selector_Requ 7788;
BA_ "SPN" SG_ 2431708416 Engine_Start_Control_Message_Cou 7750;
BA_ "SPN" SG_ 2431708416 Engine_Start_Consent 7746;
BA_ "SPN" SG_ 2431708416 Engine_Starter_1_Feedback 7748;
BA_ "SPN" SG_ 2565867008 Differential_Lock_State__Central 564;
BA_ "SPN" SG_ 2565867008 Location 927;
BA_ "SPN" SG_ 2565867008 Differential_Lock_State__Front_A 567;
BA_ "SPN" SG_ 2565867008 Differential_Lock_State__Rear_Ax 569;
BA_ "SPN" SG_ 2365428224 Fuel_Pump_Primer_Control 4082;
BA_ "SPN" SG_ 2365428224 Engine_Operating_State 3543;
BA_ "SPN" SG_ 2365428224 Engine_Fuel_Shutoff_1_Control 632;
BA_ "SPN" SG_ 2365449728 Hydraulic_Brake_Pressure_Warning 2585;
BA_ "SPN" SG_ 2365449728 Hydraulic_Brake_Pressure_Supply_ 2583;
BA_ "SPN" SG_ 2365449728 Hydraulic_Brake_Pressure_Supply_ 2582;
BA_ "SPN" SG_ 2365449728 Hydraulic_Brake_Pressure_Warning 2584;
BA_ "SPN" SG_ 2365449728 Hydraulic_Brake_Pressure_Circuit 2580;
BA_ "SPN" SG_ 2365449728 Hydraulic_Brake_Pressure_Circuit 2581;
BA_ "SPN" SG_ 2365449728 Hydraulic_Brake_Fluid_Level_Swit 2931;
BA_ "SPN" SG_ 2633883392 Front_Wheel_Drive_Actuator_Statu 2612;
BA_ "SPN" SG_ 2566768128 Engine_Cold_Start_Fuel_Igniter_R 5550;
BA_ "SPN" SG_ 2566768128 Engine_Cold_Start_Fuel_Igniter_R 5549;
BA_ "SPN" SG_ 2566832384 Total_Vehicle_Distance_High_Reso 917;
BA_ "SPN" SG_ 2566832384 Trip_Distance_High_Resolution 918;
BA_ "SPN" SG_ 2566834944 Protect_Lamp_Status 987;
BA_ "SPN" SG_ 2566834944 Amber_Warning_Lamp_Status 624;
BA_ "SPN" SG_ 2566834944 Red_Stop_Lamp_Status 623;
BA_ "SPN" SG_ 2566834944 Malfunction_Indicator_Lamp_Statu 1213;
BA_ "SPN" SG_ 2566834944 Flash_Protect_Lamp 3041;
BA_ "SPN" SG_ 2566834944 Flash_Amber_Warning_Lamp_AWL 3040;
BA_ "SPN" SG_ 2566834944 Flash_Red_Stop_Lamp_RSL 3039;
BA_ "SPN" SG_ 2566834944 Flash_Malfunction_Indicator_Lamp 3038;
BA_ "SPN" SG_ 2566834944 DTC_1 999990;
BA_ "SPN" SG_ 2566834944 DTC_2 999991;
BA_ "SPN" SG_ 2566834944 DTC_3 999992;
BA_ "SPN" SG_ 2566834944 DTC_4 999993;
BA_ "SPN" SG_ 2566834944 DTC_5 999994;
BA_ "SPN" SG_ 2566834944 DTC_6 999995;
BA_ "SPN" SG_ 2566834944 DTC_7 999996;
BA_ "SPN" SG_ 2566834944 DTC_8 999997;
BA_ "SPN" SG_ 2566834944 DTC_9 999998;
BA_ "SPN" SG_ 2566834944 DTC_10 999999;
BA_ "SPN" SG_ 2566819840 Engine_Peak_Torque_1 1248;
BA_ "SPN" SG_ 2566834688 Flash_Malfunction_Indicator_Lamp 3038;
BA_ "SPN" SG_ 2566834688 Malfunction_Indicator_Lamp_Statu 1213;
BA_ "SPN" SG_ 2566834688 Red_Stop_Lamp_Status 623;
BA_ "SPN" SG_ 2566834688 Amber_Warning_Lamp_Status 624;
BA_ "SPN" SG_ 2566834688 Flash_Red_Stop_Lamp_RSL 3039;
BA_ "SPN" SG_ 2566834688 Flash_Amber_Warning_Lamp_AWL 3040;
BA_ "SPN" SG_ 2566834688 Flash_Protect_Lamp 3041;
BA_ "SPN" SG_ 2566834688 Protect_Lamp_Status 987;
BA_ "SPN" SG_ 2566834688 DTC_1 999990;
BA_ "SPN" SG_ 2566834688 DTC_2 999991;
BA_ "SPN" SG_ 2566834688 DTC_3 999992;
BA_ "SPN" SG_ 2566834688 DTC_4 999993;
BA_ "SPN" SG_ 2566834688 DTC_5 999994;
BA_ "SPN" SG_ 2566834688 DTC_6 999995;
BA_ "SPN" SG_ 2566834688 DTC_7 999996;
BA_ "SPN" SG_ 2566834688 DTC_8 999997;
BA_ "SPN" SG_ 2566834688 DTC_9 999998;
BA_ "SPN" SG_ 2566834688 DTC_10 999999;
BA_ "SPN" SG_ 2633929216 Engine_Fuel_Rack_Position 1210;
BA_ "SPN" SG_ 2566841344 Engine_Wait_to_Start_Lamp 1081;
BA_ "SPN" SG_ 2566825472 Engine_Turbocharger_1_Boost_Pres 1127;
BA_ "SPN" SG_ 2365473024 Left_Turn_Signal_Lights_Command 2367;
BA_ "SPN" SG_ 2365473024 Alternate_Beam_Head_Light_Comman 2351;
BA_ "SPN" SG_ 2365473024 Right_Turn_Signal_Lights_Command 2369;
BA_ "SPN" SG_ 2365473024 Running_Light_Command 2403;
BA_ "SPN" SG_ 2566844160 Engine_Oil_Pressure_1 100;
BA_ "SPN" SG_ 2566844160 Engine_Oil_Level 98;
BA_ "SPN" SG_ 2566844160 Engine_Coolant_Level_1 111;
BA_ "SPN" SG_ 2566844160 Engine_Coolant_Pressure_1 109;
BA_ "SPN" SG_ 2566844160 Engine_Crankcase_Pressure_1 101;
BA_ "SPN" SG_ 2566841600 Engine_Total_Hours_of_Operation 247;
BA_ "SPN" SG_ 2566841600 Engine_Total_Revolutions 249;
BA_ "SPN" SG_ 2566844672 Cruise_Control_Set_Speed 86;
BA_ "SPN" SG_ 2566844672 Cruise_Control_Active 595;
BA_ "SPN" SG_ 2566844672 Clutch_Switch 598;
BA_ "SPN" SG_ 2566844672 Brake_Switch 597;
BA_ "SPN" SG_ 2566844672 pCC_Message_Counter 524080;
BA_ "SPN" SG_ 2566844672 Cruise_Control_Pause_Switch 1633;
BA_ "SPN" SG_ 2566844672 Cruise_Control_Set_Switch 599;
BA_ "SPN" SG_ 2566844672 Two_Speed_Axle_Switch 69;
BA_ "SPN" SG_ 2566844672 Cruise_Control_Enable_Switch 596;
BA_ "SPN" SG_ 2566844672 pOdometer_Drive_Bit 523994;
BA_ "SPN" SG_ 2566844672 pCC_Checksum 524079;
BA_ "SPN" SG_ 2566844672 WheelBased_Vehicle_Speed 84;
BA_ "SPN" SG_ 2566844672 Cruise_Control_Resume_Switch 601;
BA_ "SPN" SG_ 2566844672 Cruise_Control_Accelerate_Switch 602;
BA_ "SPN" SG_ 2566844672 pCruise_Enable_Status 524108;
BA_ "SPN" SG_ 2566844672 Parking_Brake_Switch 70;
BA_ "SPN" SG_ 2566844672 Cruise_Control_Coast_Decelerate_ 600;
BA_ "SPN" SG_ 2566844928 Engine_Instantaneous_Fuel_Econom 184;
BA_ "SPN" SG_ 2566844928 Engine_Fuel_Rate 183;
BA_ "SPN" SG_ 2566844928 Engine_Average_Fuel_Economy 185;
BA_ "SPN" SG_ 2566844928 Engine_Throttle_Valve_1_Position 51;
BA_ "SPN" SG_ 2566843904 Engine_Coolant_Temperature 110;
BA_ "SPN" SG_ 2566843904 Engine_Turbocharger_1_Oil_Temper 176;
BA_ "SPN" SG_ 2566843904 Engine_Fuel_1_Temperature_1 174;
BA_ "SPN" SG_ 2566843904 Engine_Oil_Temperature_1 175;
BA_ "SPN" SG_ 2566846208 Key_Switch_Battery_Potential 158;
BA_ "SPN" SG_ 2566846208 Alternator_Current 115;
BA_ "SPN" SG_ 2566846208 Charging_System_Potential_Voltag 167;
BA_ "SPN" SG_ 2566846208 SLI_Battery_1_Net_Current 114;
BA_ "SPN" SG_ 2566846208 Battery_Potential__Power_Input_1 168;
BA_ "SPN" SG_ 2566845952 Engine_Intake_Manifold_1_Pressur 102;
BA_ "SPN" SG_ 2566845952 Engine_Intake_Manifold_1_Tempera 105;
BA_ "SPN" SG_ 2566845952 Engine_Intake_Air_Pressure 106;
BA_ "SPN" SG_ 2566845952 Engine_Exhaust_Temperature 173;
BA_ "SPN" SG_ 2566847488 Fuel_Level_1 96;
BA_ "SPN" SG_ 2566845696 Ambient_Air_Temperature 171;
BA_ "SPN" SG_ 2566845696 Barometric_Pressure 108;
BA_ "SPN" SG_ 2566845696 Road_Surface_Temperature 79;
BA_ "SPN" SG_ 2566845696 Engine_Intake_1_Air_Temperature 172;
BA_ "SPN" SG_ 2365523456 pModule_Control_Applied_State 516096;
BA_ "SPN" SG_ 2365523456 pModule_Control_Command_Destinat 524185;
BA_ "SPN" SG_ 2365523456 pModule_Control_Command_State 524248;
BA_ "SPN" SG_ 2365523456 pModule_Control_Message_Checksum 516097;
BA_ "SPN" SG_ 2231309056 pEPCU1_Message_Counter 524152;
BA_ "SPN" SG_ 2231309056 pElectric_Propulsion_Control_Uni 524154;
BA_ "SPN" SG_ 2231309056 pEPCU1_Torque_Demand 524150;
BA_ "SPN" SG_ 2231309056 pEPCU1_Counter_Limit_Torque 524151;
BA_ "SPN" SG_ 2231309056 pEPCU1_Speed_Limit 524153;
BA_ "SPN" SG_ 2231309056 pTorque_Message_Checksum 524241;
BA_ "SPN" SG_ 2365529088 pRequested_Percent_Fan_1_Duty_Cy 520361;
BA_ "SPN" SG_ 2365529088 pFan_1_Direction_Command 520360;
BA_ "SPN" SG_ 2365530368 pMessage_Checksum 520571;
BA_ "SPN" SG_ 2365530368 pEngine_Torque__Actual 520567;
BA_ "SPN" SG_ 2365530368 pMessage_Counter 520570;
BA_ "SPN" SG_ 2365530368 pSource_Address_of_Controlling_D 520566;
BA_ "SPN" SG_ 2365530368 pEngine_Torque__Driver_Demanded 520568;
BA_ "SPN" SG_ 2365530368 pEngine_Speed 520569;
BA_ "SPN" SG_ 2566857216 pRaw_Brake_Status 520572;
BA_ "SPN" SG_ 2566857216 pVehicle_Speed 520573;
BA_ "SPN" SG_ 2566857216 pEngine_TorqueSpeed_Control_Requ 520577;
BA_ "SPN" SG_ 2566857216 pEngine_Torque__Instantaneous_Ma 520576;
BA_ "SPN" SG_ 2566857216 pEngine_Torque__Instantaneous_Mi 520575;
BA_ "SPN" SG_ 2566857216 pNormalized_Accelerator_Position 520574;
BA_ "SPN" SG_ 2566858752 pEngine_Shutdown_Temp 521193;
BA_ "SPN" SG_ 2566858752 pEngine_Top_Speed 521191;
BA_ "SPN" SG_ 2566858752 pEngine_Hot_Lamp_On 521192;
BA_ "SPN" SG_ 2365532672 pNormalized_Accelerator_Position 516168;
BA_ "SPN" SG_ 2365532672 pMessageChecksum 516175;
BA_ "SPN" SG_ 2365532672 pEngine_Torque__Driver_Demanded_ 516167;
BA_ "SPN" SG_ 2365532672 pEngine_Drag_Torque 516166;
BA_ "SPN" SG_ 2365532672 pMessageCounter 516174;
BA_ "SPN" SG_ 2365532928 pMessageChecksum 516180;
BA_ "SPN" SG_ 2365532928 pEngine_Speed__Target_Idle 516178;
BA_ "SPN" SG_ 2365532928 pEngine_Torque__Minimum 516176;
BA_ "SPN" SG_ 2365532928 pMessageCounter 516179;
BA_ "SPN" SG_ 2566860032 pSpecial_Msg_12 516427;
BA_ "SPN" SG_ 2566860032 pSpecial_Msg_28 516373;
BA_ "SPN" SG_ 2566860032 pSpecial_Msg_11 516393;
BA_ "SPN" SG_ 2566860032 pSpecial_Msg_26 516465;
BA_ "SPN" SG_ 2566860032 pSpecial_Msg_24 516463;
BA_ "SPN" SG_ 2566860032 pSpecial_Msg_21 516444;
BA_ "SPN" SG_ 2566860032 pSpecial_Msg_18 516376;
BA_ "SPN" SG_ 2566860032 pSpecial_Msg_19 516442;
BA_ "SPN" SG_ 2566860032 pSpecial_Msg_1_Riding_with_Brake 516382;
BA_ "SPN" SG_ 2566860032 pSpecial_Msg_2_Regulator_Overhea 516384;
BA_ "SPN" SG_ 2566860032 pSpecial_Msg_3_Regulator_Overhea 516385;
BA_ "SPN" SG_ 2566860032 pSpecial_Msg_4_Regulator_Overhea 516386;
BA_ "SPN" SG_ 2566860032 pSpecial_Msg_5_Engine_Warmup_Com 516387;
BA_ "SPN" SG_ 2566860032 pSpecial_Msg_6_Engine_Knock__Mod 516388;
BA_ "SPN" SG_ 2566860032 pSpecial_Msg_8_Low_Coolant_Warni 516390;
BA_ "SPN" SG_ 2566860032 pSpecial_Msg_7_Engine_Knock__Mos 516389;
BA_ "SPN" SG_ 2566860032 pSpecial_Msg_9_Transmission_Temp 516391;
BA_ "SPN" SG_ 2566860032 pSpecial_Msg_10_Reverse_Speed_Li 516392;
BA_ "SPN" SG_ 2566860032 pSpecial_Msg_13_Belt_Burn_Warnin 516381;
BA_ "SPN" SG_ 2566860032 pSpecial_Msg_14_Park_Brake_Warni 516380;
BA_ "SPN" SG_ 2566860032 pSpecial_Msg_15_TCM_Comm_Loss 516379;
BA_ "SPN" SG_ 2566860032 pSpecial_Msg_16_TCM_Pump_Priming 516378;
BA_ "SPN" SG_ 2566860032 pSpecial_Msg_17_Request_User_to_ 516377;
BA_ "SPN" SG_ 2566860032 pSpecial_MSG_20_Fuel_Door_Open_E 516443;
BA_ "SPN" SG_ 2566860032 pSpecial_MSG_22_Clutch_Overtemp 516383;
BA_ "SPN" SG_ 2566860032 pSpecial_MSG_23_Exhaust_Valve_Ch 516375;
BA_ "SPN" SG_ 2566860032 pSpecial_MSG_25_Engine_Idle_Shut 516464;
BA_ "SPN" SG_ 2566860032 pSpecial_MSG_27_Overboost_Condit 516374;
BA_ "SPN" SG_ 2566860032 pSpecial_Msg_31_Engine_Tip_Over_ 516372;
BA_ "SPN" SG_ 2566860032 pSpecial_Msg_32_Engine_Tip_Over_ 516394;
BA_ "SPN" SG_ 2566860288 pAutonomous_Available_Status 516441;
BA_ "SPN" SG_ 2566860288 pBrake_Failure_Lamp_Status 516331;
BA_ "SPN" SG_ 2566860288 pBattery_Lamp_Status 516328;
BA_ "SPN" SG_ 2566860288 pOil_Pressure_Lamp_Status 516428;
BA_ "SPN" SG_ 2566860288 pOil_Lamp_Status 516327;
BA_ "SPN" SG_ 2566860288 pTransmission_Lamp_Status 516332;
BA_ "SPN" SG_ 2566860288 pPark_Brake_Lamp_Status 516330;
BA_ "SPN" SG_ 2566860288 pHot_Lamp_Status 516326;
BA_ "SPN" SG_ 2566860288 pHigh_Beam_Status 516429;
BA_ "SPN" SG_ 2566865664 pASL_Enable 520685;
BA_ "SPN" SG_ 2566865664 pASL_Maximum_Speed 520680;
BA_ "SPN" SG_ 2566865664 pASL_Set_Speed 520682;
BA_ "SPN" SG_ 2566865664 pASL_Speed_Decrement 520684;
BA_ "SPN" SG_ 2566865664 pASL_Speed_Increment 520683;
BA_ "SPN" SG_ 2566865664 pASL_Minimum_Speed 520681;
BA_ "SPN" SG_ 2432656640 Key_Fob_Unlock_Button_Status 524044;
BA_ "SPN" SG_ 2432656640 Homelink_2 524037;
BA_ "SPN" SG_ 2432656640 Side_Stand_Switch 524098;
BA_ "SPN" SG_ 2432656640 Key_Fob_Lock_Button_Status 524043;
BA_ "SPN" SG_ 2432656640 Windshield__2_Down 524034;
BA_ "SPN" SG_ 2432656640 Turn__3_Cancel 524052;
BA_ "SPN" SG_ 2432656640 Reverse 524039;
BA_ "SPN" SG_ 2432656640 Hazard 524051;
BA_ "SPN" SG_ 2432656640 Homelink_1 524038;
BA_ "SPN" SG_ 2432656640 Windshield__1_Up 524035;
BA_ "SPN" SG_ 2432656640 Front_Brake_Switch 520322;
BA_ "SPN" SG_ 2432656640 Instrument_Cluster_Control__2 524058;
BA_ "SPN" SG_ 2432656640 Chassis_Unlock_Button_Status 524042;
BA_ "SPN" SG_ 2432656640 Power_Button 520362;
BA_ "SPN" SG_ 2432656640 RunStop_Switch 524040;
BA_ "SPN" SG_ 2432656640 Headlamp__2_High 524056;
BA_ "SPN" SG_ 2432656640 Instrument_Cluster_Control__1 524059;
BA_ "SPN" SG_ 2432656640 Clutch_Switch 524032;
BA_ "SPN" SG_ 2432656640 Start 524046;
BA_ "SPN" SG_ 2432656640 Headlamp__3_Driving 524055;
BA_ "SPN" SG_ 2432656640 Cruise__2_Set 524049;
BA_ "SPN" SG_ 2432656640 Windshield_Wiper 524041;
BA_ "SPN" SG_ 2432656640 Fog 524045;
BA_ "SPN" SG_ 2432656640 Cruise__3_Accel 524048;
BA_ "SPN" SG_ 2432656640 Horn 524047;
BA_ "SPN" SG_ 2432656640 Turn__2_Right 524053;
BA_ "SPN" SG_ 2432656640 Cruise__1_On 524050;
BA_ "SPN" SG_ 2432656640 Turn__1_Left 524054;
BA_ "SPN" SG_ 2432656640 Throttle_Safety_Switch__1 524036;
BA_ "SPN" SG_ 2432656640 Headlamp__1_Low 524057;
BA_ "SPN" SG_ 2432656640 Chassis_Lock_Switch_Status 516131;
BA_ "SPN" SG_ 2432656640 Fuel_Door_Unlock_Button_Status 516191;
BA_ "SPN" SG_ 2566876416 pFarm_Mode_Set_Speed 520633;
BA_ "SPN" SG_ 2566876416 pDrive_Mode_Requested 524067;
BA_ "SPN" SG_ 2566876416 pFarm_Mode_Maximum_Speed 520631;
BA_ "SPN" SG_ 2566876416 pDrive_Mode_Commanded 524077;
BA_ "SPN" SG_ 2566876416 pEngine_Brake_Active 521200;
BA_ "SPN" SG_ 2566876416 pFarm_Mode_Minimum_Speed 520632;
BA_ "SPN" SG_ 2566876416 pFoot_On_Cruise_Enable 524073;
BA_ "SPN" SG_ 2566876416 pFarm_Mode_Speed_Decrement 520628;
BA_ "SPN" SG_ 2566876416 pEngine_Brake_Enabled 521199;
BA_ "SPN" SG_ 2566876416 pCylDeAc_Enabled 521194;
BA_ "SPN" SG_ 2566876416 pFarm_Mode_Speed_Increment 520627;
BA_ "SPN" SG_ 2566876416 pCylDeAc_Active 521195;
BA_ "SPN" SG_ 2633984768 pInstrumentation_Backlight_Inten 524015;
BA_ "SPN" SG_ 2633984768 pFuel_Economy_Data_Source 524094;
BA_ "SPN" SG_ 2633984768 pActive_Decent_Control_ADC_Mode_ 524143;
BA_ "SPN" SG_ 2633984768 pFuel_Level_Data_Source 524091;
BA_ "SPN" SG_ 2633984768 pVehicle_Units_Configuration 524093;
BA_ "SPN" SG_ 2633984768 pLow_Fuel_Light_ON_Percentage 524090;
BA_ "SPN" SG_ 2633984768 pSeat_Belt_Input_Source 524095;
BA_ "SPN" SG_ 2633984768 pAWD_Mode_Availability 524142;
BA_ "SPN" SG_ 2633984768 pWarning_Lamp_Intensity 524016;
BA_ "SPN" SG_ 2633984768 pTurf_Mode_Availability 524140;
BA_ "SPN" SG_ 2633984768 pFuel_Tank_Volume 524089;
BA_ "SPN" SG_ 2633984768 pDisplayed_Speed_Correction_Fact 524014;
BA_ "SPN" SG_ 2432658432 pFOCC_Checksum 524081;
BA_ "SPN" SG_ 2432658432 Drive_Mode__4 524063;
BA_ "SPN" SG_ 2432658432 Drive_Mode__2 524061;
BA_ "SPN" SG_ 2432658432 pFOCC_Message_Counter 524082;
BA_ "SPN" SG_ 2432658432 Drivers_Net_Engagement 524066;
BA_ "SPN" SG_ 2432658432 Foot_On_Cruise_Control_Switch 524072;
BA_ "SPN" SG_ 2432658432 Drive_Mode__1 524060;
BA_ "SPN" SG_ 2432658432 Momentary_Driveline_Left_Press 520467;
BA_ "SPN" SG_ 2432658432 CylDeAc_Enable 521197;
BA_ "SPN" SG_ 2432658432 Work_Group_Lock_Switch 524069;
BA_ "SPN" SG_ 2432658432 Drivers_Seatbelt_Engagement 524065;
BA_ "SPN" SG_ 2432658432 Drive_Mode__3 524062;
BA_ "SPN" SG_ 2432658432 Work_Mode_Switch 524071;
BA_ "SPN" SG_ 2432658432 Momentary_Driveline_Right_Press 520468;
BA_ "SPN" SG_ 2432658432 PTO_Mode_Switch_RPM_Control 524064;
BA_ "SPN" SG_ 2432658432 Operator_Presence_Switch 524070;
BA_ "SPN" SG_ 2432658432 Tilt_Lock_Switch 524068;
BA_ "SPN" SG_ 2432658432 Engine_Brake_Enable 521198;
BA_ "SPN" SG_ 2432658432 Accessory_Relay 520469;
BA_ "SPN" SG_ 2633984512 pHeated_Grip_Enable 520366;
BA_ "SPN" SG_ 2633984512 pUser_PIN_Access_Status 516128;
BA_ "SPN" SG_ 2633984512 pActive_Descent_Control_ADC_Stat 524013;
BA_ "SPN" SG_ 2633984512 pCruise_Control_Set_Status 524097;
BA_ "SPN" SG_ 2633984512 pTether_Switch_Status 520600;
BA_ "SPN" SG_ 2633984512 pHigh_Beam_Indicator_Status 524084;
BA_ "SPN" SG_ 2633984512 pLow_Fuel_Indicator_Status 524087;
BA_ "SPN" SG_ 2633984512 pHeated_Grips_Percentage 524096;
BA_ "SPN" SG_ 2633984512 pSide_Stand_Status 524270;
BA_ "SPN" SG_ 2633984512 pTurf_Mode_Requested 524136;
BA_ "SPN" SG_ 2633984512 pEngine_Idle_Shutdown_Timer 516223;
BA_ "SPN" SG_ 2633984512 Operator_Not_in_Operating_Statio 520247;
BA_ "SPN" SG_ 2633984512 pAWD_Mode_Requested 524138;
BA_ "SPN" SG_ 2633984512 pHeated_Grips_Up_Switch_Status 516129;
BA_ "SPN" SG_ 2633984512 pTreadle_Neutral_Status 524017;
BA_ "SPN" SG_ 2633984512 pHeated_Grips_Down_Switch_Status 516130;
BA_ "SPN" SG_ 2633984512 pPark_Brake_Indicator_Status 524271;
BA_ "SPN" SG_ 2633984512 pRWD_Mode_Requested 524137;
BA_ "SPN" SG_ 2633984512 pSeat_Belt_Indicator_Status 524092;
BA_ "SPN" SG_ 2633984512 pSecurity_Light_Immobilizer_Stat 524019;
BA_ "SPN" SG_ 2633984512 ECU_Security_Status 516202;
BA_ "SPN" SG_ 2633984512 pActive_Decent_Control_ADC_Mode_ 524139;
BA_ "SPN" SG_ 2633984512 pTreadle_Reverse_Status 524018;
BA_ "SPN" SG_ 2566875136 pFuel_Type_Selected 524007;
BA_ "SPN" SG_ 2566875136 pFuel_Type_Sensor 524008;
BA_ "SPN" SG_ 2365548032 pEngine_Speed_8000RPM 524000;
BA_ "SPN" SG_ 2365548032 pCruiseControlStates 520599;
BA_ "SPN" SG_ 2365548032 pFuel_Range 524088;
BA_ "SPN" SG_ 2365548032 pCruiseControlSetSpeed 523961;
BA_ "SPN" SG_ 2365548032 pStuck_Throttle 524001;
BA_ "SPN" SG_ 2365548032 pHigh_Idle_State 524078;
BA_ "SPN" SG_ 2231334144 Normalized_Accelerator_Position_ 520354;
BA_ "SPN" SG_ 2231334144 Operation_Mode_Status 524120;
BA_ "SPN" SG_ 2231334144 StartStop_Vehicle_Command 520497;
BA_ "SPN" SG_ 2231334144 Message_Counter 524122;
BA_ "SPN" SG_ 2231334144 Checksum 524123;
BA_ "SPN" SG_ 2566876672 pHydraulic_Oil_Temp_Status 524074;
BA_ "SPN" SG_ 2566876672 pHydraulic_Oil_Pressure_Status 524075;
BA_ "SPN" SG_ 2566876672 pEngine_Oil_Pressure_Status 524076;
BA_ "SPN" SG_ 2566877696 pRight_Hand_Grip_Temperature 524110;
BA_ "SPN" SG_ 2566877696 pDriver_Seat_Temperature 516453;
BA_ "SPN" SG_ 2566877696 pPassenger_Seat_Temperature 516454;
BA_ "SPN" SG_ 2566877696 pLeft_Hand_Grip_Temperature 524109;
BA_ "DBName" "MasterDBC";
BA_ "NmStationAddress" BU_ SCM 47;
BA_ "NmStationAddress" BU_ BC1 33;
BA_ "NmStationAddress" BU_ BC2 144;
BA_ "NmStationAddress" BU_ ECM 0;
BA_ "NmStationAddress" BU_ PSC 5;
BA_ "NmStationAddress" BU_ ABS 11;
BA_ "NmStationAddress" BU_ Brakes__Drive_Axle_1 13;
BA_ "NmStationAddress" BU_ EPS 19;
BA_ "NmStationAddress" BU_ IC 23;
BA_ "NmStationAddress" BU_ GPS 28;
BA_ "NmStationAddress" BU_ WCM 29;
BA_ "NmStationAddress" BU_ VCM 39;
BA_ "NmStationAddress" BU_ Seat_Control_1 54;
BA_ "NmStationAddress" BU_ ISC1 65;
BA_ "NmStationAddress" BU_ HCU 90;
BA_ "NmStationAddress" BU_ IDT 120;
BA_ "NmStationAddress" BU_ GMRS 124;
BA_ "NmStationAddress" BU_ XM 126;
BA_ "NmStationAddress" BU_ RH 127;
BA_ "NmStationAddress" BU_ AUTON 132;
BA_ "NmStationAddress" BU_ LHC 135;
BA_ "NmStationAddress" BU_ CIM 140;
BA_ "NmStationAddress" BU_ IMU 141;
BA_ "NmStationAddress" BU_ BC3 145;
BA_ "NmStationAddress" BU_ IC2 167;
BA_ "NmStationAddress" BU_ EPC1 239;
BA_ "NmStationAddress" BU_ EPC2 240;
BA_ "NmStationAddress" BU_ EPC3 241;
BA_ "NmStationAddress" BU_ EPC4 242;
BA_ "NmStationAddress" BU_ BMC1 243;
BA_ "NmStationAddress" BU_ BMC2 244;
BA_ "NmStationAddress" BU_ APU2 246;
BA_ "NmStationAddress" BU_ APU1 247;
BA_ "NmStationAddress" BU_ SRVTOOL 249;
BA_ "NmStationAddress" BU_ RHC 134;
BA_ "NmStationAddress" BU_ RCM 148;
BA_ "GenMsgCycleTime" BO_ 2566893871 100;
BA_ "GenMsgCycleTime" BO_ 2566887215 100;
BA_ "GenMsgCycleTime" BO_ 2297441583 20;
BA_ "GenMsgCycleTimeFast" BO_ 2297441583 10;
BA_ "GenMsgCycleTime" BO_ 2365531183 500;
BA_ "GenMsgCycleTimeFast" BO_ 2365531183 10;
BA_ "GenMsgCycleTime" BO_ 2633984545 500;
BA_ "GenMsgCycleTimeFast" BO_ 2633984545 100;
BA_ "GenMsgCycleTime" BO_ 2349465377 100;
BA_ "GenMsgCycleTime" BO_ 2365523489 5000;
BA_ "GenMsgCycleTimeFast" BO_ 2365523489 50;
BA_ "GenMsgCycleTime" BO_ 2633984656 500;
BA_ "GenMsgCycleTimeFast" BO_ 2633984656 100;
BA_ "GenMsgCycleTime" BO_ 2365473168 1000;
BA_ "GenMsgCycleTimeFast" BO_ 2365473168 100;
BA_ "GenMsgCycleTime" BO_ 2566860065 1000;
BA_ "GenMsgCycleTimeFast" BO_ 2566860065 500;
BA_ "GenMsgCycleTime" BO_ 2348875520 50;
BA_ "GenMsgCycleTimeFast" BO_ 2348875520 10;
BA_ "GenMsgCycleTime" BO_ 2364539648 50;
BA_ "GenMsgCycleTime" BO_ 2364539904 20;
BA_ "GenMsgCycleTime" BO_ 2565866752 100;
BA_ "GenMsgCycleTime" BO_ 2431708416 250;
BA_ "GenMsgCycleTimeFast" BO_ 2431708416 20;
BA_ "GenMsgCycleTime" BO_ 2565867008 500;
BA_ "GenMsgCycleTime" BO_ 2365449728 100;
BA_ "GenMsgCycleTime" BO_ 2633883392 500;
BA_ "GenMsgCycleTime" BO_ 2566832384 1000;
BA_ "GenMsgCycleTime" BO_ 2566819840 1000;
BA_ "GenMsgCycleTime" BO_ 2566834688 1000;
BA_ "GenMsgCycleTime" BO_ 2633929216 100;
BA_ "GenMsgCycleTime" BO_ 2566841344 1000;
BA_ "GenMsgCycleTime" BO_ 2566825472 500;
BA_ "GenMsgCycleTime" BO_ 2365473024 1000;
BA_ "GenMsgCycleTimeFast" BO_ 2365473024 100;
BA_ "GenMsgCycleTime" BO_ 2566844160 500;
BA_ "GenMsgCycleTime" BO_ 2566844672 100;
BA_ "GenMsgCycleTime" BO_ 2566844928 100;
BA_ "GenMsgCycleTime" BO_ 2566843904 1000;
BA_ "GenMsgCycleTime" BO_ 2566846208 1000;
BA_ "GenMsgCycleTime" BO_ 2566845952 500;
BA_ "GenMsgCycleTime" BO_ 2566847488 1000;
BA_ "GenMsgCycleTime" BO_ 2566845696 1000;
BA_ "GenMsgCycleTime" BO_ 2365523456 5000;
BA_ "GenMsgCycleTimeFast" BO_ 2365523456 50;
BA_ "GenMsgCycleTime" BO_ 2231309056 10;
BA_ "GenMsgCycleTime" BO_ 2365529088 1000;
BA_ "GenMsgCycleTime" BO_ 2365530368 10;
BA_ "GenMsgCycleTime" BO_ 2566857216 10;
BA_ "GenMsgCycleTime" BO_ 2365532672 10;
BA_ "GenMsgCycleTime" BO_ 2365532928 10;
BA_ "GenMsgCycleTime" BO_ 2566860032 1000;
BA_ "GenMsgCycleTimeFast" BO_ 2566860032 500;
BA_ "GenMsgCycleTime" BO_ 2566860288 1000;
BA_ "GenMsgCycleTimeFast" BO_ 2566860288 500;
BA_ "GenMsgCycleTime" BO_ 2566865664 100;
BA_ "GenMsgCycleTimeFast" BO_ 2566865664 10;
BA_ "GenMsgCycleTime" BO_ 2432656640 200;
BA_ "GenMsgCycleTimeFast" BO_ 2432656640 100;
BA_ "GenMsgCycleTime" BO_ 2566876416 100;
BA_ "GenMsgCycleTimeFast" BO_ 2566876416 100;
BA_ "GenMsgCycleTime" BO_ 2432658432 200;
BA_ "GenMsgCycleTimeFast" BO_ 2432658432 100;
BA_ "GenMsgCycleTime" BO_ 2633984512 500;
BA_ "GenMsgCycleTimeFast" BO_ 2633984512 100;
BA_ "GenMsgCycleTime" BO_ 2566875136 1000;
BA_ "GenMsgCycleTime" BO_ 2365548032 20;
BA_ "GenMsgCycleTime" BO_ 2231334144 200;
BA_ "GenMsgCycleTimeFast" BO_ 2231334144 10;
BA_ "GenMsgCycleTime" BO_ 2566876672 1000;
BA_ "GenMsgCycleTime" BO_ 2566877696 1000;
VAL_ 2566887215 pVehicle_Event_Status__Accelerat 2 "Error" 0 "Off" 1 "On" 3 "Not-Available" ;
VAL_ 2566887215 pVehicle_Event_Status__Cornering 2 "Error" 0 "Off" 1 "On" 3 "Not-Available" ;
VAL_ 2566887215 pVehicle_Event_Status__Braking 2 "Error" 0 "Off" 1 "On" 3 "Not-Available" ;
VAL_ 2566887215 pSuspension_Mode_Requested 4 "Mode 4 (previously ‘Semi-Active Damping – Sport’)" 15 "Not Available" 0 "Mode 0 (previously ‘Passive – Firm’)" 1 "Mode 1 (previously ‘Passive – Medium’)" 2 "Mode 2 (previously ‘Passive – Soft’)" 3 "Mode 3 (previously ‘Semi-Active ‘Damping – Comfort’)" 14 "Error" ;
VAL_ 2566887215 pSuspension_Mode_Change_Active 0 "Inactive" 1 "Active" ;
VAL_ 2566887215 pVehicle_Event_Status__Airborne 2 "Error" 0 "Off" 1 "On" 3 "Not-Available" ;
VAL_ 2566887215 pDemo_Status 2 "Error" 0 "Off" 1 "On" 3 "Not-Available" ;
VAL_ 2566887215 pSuspension_Mode_Active 4 "Mode 4 (previously ‘Semi-Active Damping – Sport’)" 15 "Not Available" 0 "Mode 0 (previously ‘Passive – Firm’)" 1 "Mode 1 (previously ‘Passive – Medium’)" 2 "Mode 2 (previously ‘Passive – Soft’)" 3 "Mode 3 (previously ‘Semi-Active ‘Damping – Comfort’)" 14 "Error" ;
VAL_ 2566887215 pVehicle_Event_Status__Pucker 2 "Error" 0 "Off" 1 "On" 3 "Not-Available" ;
VAL_ 2365531183 pEPSReqMod 13 "13(0x0D) – EPS Assist Mode 4" 0 "0 (0x00) – Assist Off: all mosfet drivers are off, control motor is freely back driven." 11 "11(0x0B) – EPS Assist Mode 2" 10 "10(0x0A) – EPS Assist Mode 1" 12 "12(0x0C) – EPS Assist Mode 3" ;
VAL_ 2633984545 pHeated_Grip_Enable 2 "Error" 0 "Off" 1 "On" 3 "Not-Available" ;
VAL_ 2633984545 pUser_PIN_Access_Status 2 "Error" 0 "Off" 1 "On" 3 "Not-Available" ;
VAL_ 2633984545 pActive_Descent_Control_ADC_Stat 2 "Error" 0 "Off" 1 "On" 3 "Not-Available" ;
VAL_ 2633984545 pCruise_Control_Set_Status 2 "Error" 0 "Off" 1 "On" 3 "Not-Available" ;
VAL_ 2633984545 pTether_Switch_Status 2 "Error" 0 "Off" 1 "On" 3 "Not-Available" ;
VAL_ 2633984545 pHigh_Beam_Indicator_Status 2 "Error" 0 "Off" 1 "On" 3 "Not-Available" ;
VAL_ 2633984545 pLow_Fuel_Indicator_Status 2 "Error" 0 "Off" 1 "On" 3 "Not-Available" ;
VAL_ 2633984545 pSide_Stand_Status 2 "Error" 1 "Side Stand Extended" 0 "Side Stand Retracted" 3 "Not Available" ;
VAL_ 2633984545 pTurf_Mode_Requested 2 "Error" 0 "Off" 1 "On" 3 "Not-Available" ;
VAL_ 2633984545 Operator_Not_in_Operating_Statio 2 "Error" 0 "Off" 1 "On" 3 "Not-Available" ;
VAL_ 2633984545 pAWD_Mode_Requested 2 "Error" 0 "Off" 1 "On" 3 "Not-Available" ;
VAL_ 2633984545 pHeated_Grips_Up_Switch_Status 2 "Error" 0 "Off" 1 "On" 3 "Not-Available" ;
VAL_ 2633984545 pTreadle_Neutral_Status 2 "Error" 0 "Off" 1 "On" 3 "Not-Available" ;
VAL_ 2633984545 pHeated_Grips_Down_Switch_Status 2 "Error" 0 "Off" 1 "On" 3 "Not-Available" ;
VAL_ 2633984545 pPark_Brake_Indicator_Status 2 "Slow Flash (1 Hz, 50% duty cycle)" 7 "Not Available" 1 "On" 3 "Fast Flash (2 HZ or faster, 50% Duty Cycle)" 0 "Off" 6 "Error" ;
VAL_ 2633984545 pRWD_Mode_Requested 2 "Error" 0 "Off" 1 "On" 3 "Not-Available" ;
VAL_ 2633984545 pSeat_Belt_Indicator_Status 2 "Slow Flash (1 Hz, 50% duty cycle)" 7 "Not Available" 1 "On" 3 "Fast Flash (2 HZ or faster, 50% Duty Cycle)" 0 "Off" 6 "Error" ;
VAL_ 2633984545 pSecurity_Light_Immobilizer_Stat 2 "Error" 0 "Off" 1 "On" 3 "Not-Available" ;
VAL_ 2633984545 ECU_Security_Status 1 "Locked, Awaiting Unlock" 3 " Locked, system will shut down" 0 "Unlocked" 7 "Not Available" 2 "Locked, System will not shut down" 6 "Error" ;
VAL_ 2633984545 pActive_Decent_Control_ADC_Mode_ 2 "Error" 0 "Off" 1 "On" 3 "Not-Available" ;
VAL_ 2633984545 pTreadle_Reverse_Status 2 "Error" 0 "Off" 1 "On" 3 "Not-Available" ;
VAL_ 2365523489 pModule_Control_Applied_State 1 "Partial Wakeup Applied " 0 "No Change Applied" 2 "Full Wakeup Applied" 3 "Power Down Applied " 13 "No Change - Checksum Error " 4 "Stay Awake Applied " 14 "Error State" 15 "Not Available" 5 "Alarm Activation Applied " ;
VAL_ 2365523489 pModule_Control_Command_State 3 "Power Down Requested" 2 "Full Wakeup Requested" 15 "Not Available" 14 "Error" 5 "Alarm Activation Requested" 1 "Partial Wakeup Requested" 4 "Stay Awake Requested" 0 "No Change Requested" ;
VAL_ 2633984656 pHeated_Grip_Enable 2 "Error" 0 "Off" 1 "On" 3 "Not-Available" ;
VAL_ 2633984656 pUser_PIN_Access_Status 2 "Error" 0 "Off" 1 "On" 3 "Not-Available" ;
VAL_ 2633984656 pActive_Descent_Control_ADC_Stat 2 "Error" 0 "Off" 1 "On" 3 "Not-Available" ;
VAL_ 2633984656 pCruise_Control_Set_Status 2 "Error" 0 "Off" 1 "On" 3 "Not-Available" ;
VAL_ 2633984656 pTether_Switch_Status 2 "Error" 0 "Off" 1 "On" 3 "Not-Available" ;
VAL_ 2633984656 pHigh_Beam_Indicator_Status 2 "Error" 0 "Off" 1 "On" 3 "Not-Available" ;
VAL_ 2633984656 pLow_Fuel_Indicator_Status 2 "Error" 0 "Off" 1 "On" 3 "Not-Available" ;
VAL_ 2633984656 pSide_Stand_Status 2 "Error" 1 "Side Stand Extended" 0 "Side Stand Retracted" 3 "Not Available" ;
VAL_ 2633984656 pTurf_Mode_Requested 2 "Error" 0 "Off" 1 "On" 3 "Not-Available" ;
VAL_ 2633984656 Operator_Not_in_Operating_Statio 2 "Error" 0 "Off" 1 "On" 3 "Not-Available" ;
VAL_ 2633984656 pAWD_Mode_Requested 2 "Error" 0 "Off" 1 "On" 3 "Not-Available" ;
VAL_ 2633984656 pHeated_Grips_Up_Switch_Status 2 "Error" 0 "Off" 1 "On" 3 "Not-Available" ;
VAL_ 2633984656 pTreadle_Neutral_Status 2 "Error" 0 "Off" 1 "On" 3 "Not-Available" ;
VAL_ 2633984656 pHeated_Grips_Down_Switch_Status 2 "Error" 0 "Off" 1 "On" 3 "Not-Available" ;
VAL_ 2633984656 pPark_Brake_Indicator_Status 2 "Slow Flash (1 Hz, 50% duty cycle)" 7 "Not Available" 1 "On" 3 "Fast Flash (2 HZ or faster, 50% Duty Cycle)" 0 "Off" 6 "Error" ;
VAL_ 2633984656 pRWD_Mode_Requested 2 "Error" 0 "Off" 1 "On" 3 "Not-Available" ;
VAL_ 2633984656 pSeat_Belt_Indicator_Status 2 "Slow Flash (1 Hz, 50% duty cycle)" 7 "Not Available" 1 "On" 3 "Fast Flash (2 HZ or faster, 50% Duty Cycle)" 0 "Off" 6 "Error" ;
VAL_ 2633984656 pSecurity_Light_Immobilizer_Stat 2 "Error" 0 "Off" 1 "On" 3 "Not-Available" ;
VAL_ 2633984656 ECU_Security_Status 1 "Locked, Awaiting Unlock" 3 " Locked, system will shut down" 0 "Unlocked" 7 "Not Available" 2 "Locked, System will not shut down" 6 "Error" ;
VAL_ 2633984656 pActive_Decent_Control_ADC_Mode_ 2 "Error" 0 "Off" 1 "On" 3 "Not-Available" ;
VAL_ 2633984656 pTreadle_Reverse_Status 2 "Error" 0 "Off" 1 "On" 3 "Not-Available" ;
VAL_ 2566860065 pSpecial_Msg_12 2 "Error" 0 "Off" 1 "On" 3 "Not-Available" ;
VAL_ 2566860065 pSpecial_Msg_28 2 "Error" 0 "Off" 1 "On" 3 "Not-Available" ;
VAL_ 2566860065 pSpecial_Msg_11 2 "Error" 0 "Off" 1 "On" 3 "Not-Available" ;
VAL_ 2566860065 pSpecial_Msg_26 2 "Error" 0 "Off" 1 "On" 3 "Not-Available" ;
VAL_ 2566860065 pSpecial_Msg_24 2 "Error" 0 "Off" 1 "On" 3 "Not-Available" ;
VAL_ 2566860065 pSpecial_Msg_21 2 "Error" 0 "Off" 1 "On" 3 "Not-Available" ;
VAL_ 2566860065 pSpecial_Msg_18 2 "Error" 0 "Off" 1 "On" 3 "Not-Available" ;
VAL_ 2566860065 pSpecial_Msg_19 2 "Error" 0 "Off" 1 "On" 3 "Not-Available" ;
VAL_ 2566860065 pSpecial_Msg_1_Riding_with_Brake 2 "Error" 0 "Off" 1 "On" 3 "Not-Available" ;
VAL_ 2566860065 pSpecial_Msg_2_Regulator_Overhea 2 "Error" 0 "Off" 1 "On" 3 "Not-Available" ;
VAL_ 2566860065 pSpecial_Msg_3_Regulator_Overhea 2 "Error" 0 "Off" 1 "On" 3 "Not-Available" ;
VAL_ 2566860065 pSpecial_Msg_4_Regulator_Overhea 2 "Error" 0 "Off" 1 "On" 3 "Not-Available" ;
VAL_ 2566860065 pSpecial_Msg_5_Engine_Warmup_Com 2 "Error" 0 "Off" 1 "On" 3 "Not-Available" ;
VAL_ 2566860065 pSpecial_Msg_6_Engine_Knock__Mod 2 "Error" 0 "Off" 1 "On" 3 "Not-Available" ;
VAL_ 2566860065 pSpecial_Msg_8_Low_Coolant_Warni 2 "Error" 0 "Off" 1 "On" 3 "Not-Available" ;
VAL_ 2566860065 pSpecial_Msg_7_Engine_Knock__Mos 2 "Error" 0 "Off" 1 "On" 3 "Not-Available" ;
VAL_ 2566860065 pSpecial_Msg_9_Transmission_Temp 2 "Error" 0 "Off" 1 "On" 3 "Not-Available" ;
VAL_ 2566860065 pSpecial_Msg_10_Reverse_Speed_Li 2 "Error" 0 "Off" 1 "On" 3 "Not-Available" ;
VAL_ 2566860065 pSpecial_Msg_13_Belt_Burn_Warnin 2 "Error" 0 "Off" 1 "On" 3 "Not-Available" ;
VAL_ 2566860065 pSpecial_Msg_14_Park_Brake_Warni 2 "Error" 0 "Off" 1 "On" 3 "Not-Available" ;
VAL_ 2566860065 pSpecial_Msg_15_TCM_Comm_Loss 2 "Error" 0 "Off" 1 "On" 3 "Not-Available" ;
VAL_ 2566860065 pSpecial_Msg_16_TCM_Pump_Priming 2 "Error" 0 "Off" 1 "On" 3 "Not-Available" ;
VAL_ 2566860065 pSpecial_Msg_17_Request_User_to_ 2 "Error" 0 "Off" 1 "On" 3 "Not-Available" ;
VAL_ 2566860065 pSpecial_MSG_20_Fuel_Door_Open_E 2 "Error" 0 "Off" 1 "On" 3 "Not-Available" ;
VAL_ 2566860065 pSpecial_MSG_22_Clutch_Overtemp 2 "Error" 0 "Off" 1 "On" 3 "Not-Available" ;
VAL_ 2566860065 pSpecial_MSG_23_Exhaust_Valve_Ch 2 "Error" 0 "Off" 1 "On" 3 "Not-Available" ;
VAL_ 2566860065 pSpecial_MSG_25_Engine_Idle_Shut 2 "Error" 0 "Off" 1 "On" 3 "Not-Available" ;
VAL_ 2566860065 pSpecial_MSG_27_Overboost_Condit 2 "Error" 0 "Off" 1 "On" 3 "Not-Available" ;
VAL_ 2566860065 pSpecial_Msg_31_Engine_Tip_Over_ 2 "Error" 0 "Off" 1 "On" 3 "Not-Available" ;
VAL_ 2566860065 pSpecial_Msg_32_Engine_Tip_Over_ 2 "Error" 0 "Off" 1 "On" 3 "Not-Available" ;
VAL_ 2631728896 Antitheft_Password_Valid_Indicat 3 "Not available" 2 "Error" 1 "Password is a validated password" 0 "Password is not a validated password" ;
VAL_ 2365428224 Engine_Operating_State 1 "Pre-Start" 3 "Warm-Up" 15 "Not Available" 4 "Running" 0 "Engine Stopped" 6 "Engine Stopping" 2 "Starting" 7 "Post-Run" 5 "Cool-down" 14 "Reserved" ;
VAL_ 2566844672 pOdometer_Drive_Bit 3 "Not Available " 2 "Error" 0 "State A" 1 "State B" ;
VAL_ 2566844672 pCruise_Enable_Status 14 "Error" 15 "Not Available " 0 "Not enabled. System must be enabled before it is set" 1 "Enable. System is ready to be set by operator. Only change state when system is enabled/disabled with on/off switch" ;
VAL_ 2365523456 pModule_Control_Applied_State 1 "Partial Wakeup Applied " 0 "No Change Applied" 2 "Full Wakeup Applied" 3 "Power Down Applied " 13 "No Change - Checksum Error " 4 "Stay Awake Applied " 14 "Error State" 15 "Not Available" 5 "Alarm Activation Applied " ;
VAL_ 2365523456 pModule_Control_Command_State 3 "Power Down Requested" 2 "Full Wakeup Requested" 15 "Not Available" 14 "Error" 5 "Alarm Activation Requested" 1 "Partial Wakeup Requested" 4 "Stay Awake Requested" 0 "No Change Requested" ;
VAL_ 2231309056 pElectric_Propulsion_Control_Uni 8 "Torque Command" 2 "Enable Command" 0 "Shutdown Command" 3 "Reserved for Active Short" 4 "Reserved for End Active Short" 9 "Speed Command" 11 "Reserved for Active Discharge" 10 "Reserved for Control Vbat" 5 "Fault Reset" 15 "No Change in state or control demand" 1 "Energize Command" ;
VAL_ 2365529088 pFan_1_Direction_Command 1 "Reverse" 0 "Forward" ;
VAL_ 2566857216 pRaw_Brake_Status 2 "Error" 0 "Off" 1 "On" 3 "Not-Available" ;
VAL_ 2566857216 pEngine_TorqueSpeed_Control_Requ 1 " Request denied due to ECM fault" 0 "Request granted" 2 "Request denied. Requested torque is out of range that engine can supply." 7 "Not Available" 6 "Error" 3 "Request denied. Engine Torque - Driver Demanded is lower than torque requested by Engine Control Requestor." ;
VAL_ 2566860032 pSpecial_Msg_12 2 "Error" 0 "Off" 1 "On" 3 "Not-Available" ;
VAL_ 2566860032 pSpecial_Msg_28 2 "Error" 0 "Off" 1 "On" 3 "Not-Available" ;
VAL_ 2566860032 pSpecial_Msg_11 2 "Error" 0 "Off" 1 "On" 3 "Not-Available" ;
VAL_ 2566860032 pSpecial_Msg_26 2 "Error" 0 "Off" 1 "On" 3 "Not-Available" ;
VAL_ 2566860032 pSpecial_Msg_24 2 "Error" 0 "Off" 1 "On" 3 "Not-Available" ;
VAL_ 2566860032 pSpecial_Msg_21 2 "Error" 0 "Off" 1 "On" 3 "Not-Available" ;
VAL_ 2566860032 pSpecial_Msg_18 2 "Error" 0 "Off" 1 "On" 3 "Not-Available" ;
VAL_ 2566860032 pSpecial_Msg_19 2 "Error" 0 "Off" 1 "On" 3 "Not-Available" ;
VAL_ 2566860032 pSpecial_Msg_1_Riding_with_Brake 2 "Error" 0 "Off" 1 "On" 3 "Not-Available" ;
VAL_ 2566860032 pSpecial_Msg_2_Regulator_Overhea 2 "Error" 0 "Off" 1 "On" 3 "Not-Available" ;
VAL_ 2566860032 pSpecial_Msg_3_Regulator_Overhea 2 "Error" 0 "Off" 1 "On" 3 "Not-Available" ;
VAL_ 2566860032 pSpecial_Msg_4_Regulator_Overhea 2 "Error" 0 "Off" 1 "On" 3 "Not-Available" ;
VAL_ 2566860032 pSpecial_Msg_5_Engine_Warmup_Com 2 "Error" 0 "Off" 1 "On" 3 "Not-Available" ;
VAL_ 2566860032 pSpecial_Msg_6_Engine_Knock__Mod 2 "Error" 0 "Off" 1 "On" 3 "Not-Available" ;
VAL_ 2566860032 pSpecial_Msg_8_Low_Coolant_Warni 2 "Error" 0 "Off" 1 "On" 3 "Not-Available" ;
VAL_ 2566860032 pSpecial_Msg_7_Engine_Knock__Mos 2 "Error" 0 "Off" 1 "On" 3 "Not-Available" ;
VAL_ 2566860032 pSpecial_Msg_9_Transmission_Temp 2 "Error" 0 "Off" 1 "On" 3 "Not-Available" ;
VAL_ 2566860032 pSpecial_Msg_10_Reverse_Speed_Li 2 "Error" 0 "Off" 1 "On" 3 "Not-Available" ;
VAL_ 2566860032 pSpecial_Msg_13_Belt_Burn_Warnin 2 "Error" 0 "Off" 1 "On" 3 "Not-Available" ;
VAL_ 2566860032 pSpecial_Msg_14_Park_Brake_Warni 2 "Error" 0 "Off" 1 "On" 3 "Not-Available" ;
VAL_ 2566860032 pSpecial_Msg_15_TCM_Comm_Loss 2 "Error" 0 "Off" 1 "On" 3 "Not-Available" ;
VAL_ 2566860032 pSpecial_Msg_16_TCM_Pump_Priming 2 "Error" 0 "Off" 1 "On" 3 "Not-Available" ;
VAL_ 2566860032 pSpecial_Msg_17_Request_User_to_ 2 "Error" 0 "Off" 1 "On" 3 "Not-Available" ;
VAL_ 2566860032 pSpecial_MSG_20_Fuel_Door_Open_E 2 "Error" 0 "Off" 1 "On" 3 "Not-Available" ;
VAL_ 2566860032 pSpecial_MSG_22_Clutch_Overtemp 2 "Error" 0 "Off" 1 "On" 3 "Not-Available" ;
VAL_ 2566860032 pSpecial_MSG_23_Exhaust_Valve_Ch 2 "Error" 0 "Off" 1 "On" 3 "Not-Available" ;
VAL_ 2566860032 pSpecial_MSG_25_Engine_Idle_Shut 2 "Error" 0 "Off" 1 "On" 3 "Not-Available" ;
VAL_ 2566860032 pSpecial_MSG_27_Overboost_Condit 2 "Error" 0 "Off" 1 "On" 3 "Not-Available" ;
VAL_ 2566860032 pSpecial_Msg_31_Engine_Tip_Over_ 2 "Error" 0 "Off" 1 "On" 3 "Not-Available" ;
VAL_ 2566860032 pSpecial_Msg_32_Engine_Tip_Over_ 2 "Error" 0 "Off" 1 "On" 3 "Not-Available" ;
VAL_ 2566860288 pAutonomous_Available_Status 2 "Error" 0 "Off" 1 "On" 3 "Not-Available" ;
VAL_ 2566860288 pBrake_Failure_Lamp_Status 2 "Slow Flash (1 Hz, 50% duty cycle)" 7 "Not Available" 1 "On" 3 "Fast Flash (2 HZ or faster, 50% Duty Cycle)" 0 "Off" 6 "Error" ;
VAL_ 2566860288 pBattery_Lamp_Status 2 "Slow Flash (1 Hz, 50% duty cycle)" 7 "Not Available" 1 "On" 3 "Fast Flash (2 HZ or faster, 50% Duty Cycle)" 0 "Off" 6 "Error" ;
VAL_ 2566860288 pOil_Pressure_Lamp_Status 2 "Slow Flash (1 Hz, 50% duty cycle)" 7 "Not Available" 1 "On" 3 "Fast Flash (2 HZ or faster, 50% Duty Cycle)" 0 "Off" 6 "Error" ;
VAL_ 2566860288 pOil_Lamp_Status 2 "Slow Flash (1 Hz, 50% duty cycle)" 7 "Not Available" 1 "On" 3 "Fast Flash (2 HZ or faster, 50% Duty Cycle)" 0 "Off" 6 "Error" ;
VAL_ 2566860288 pTransmission_Lamp_Status 2 "Slow Flash (1 Hz, 50% duty cycle)" 7 "Not Available" 1 "On" 3 "Fast Flash (2 HZ or faster, 50% Duty Cycle)" 0 "Off" 6 "Error" ;
VAL_ 2566860288 pPark_Brake_Lamp_Status 2 "Slow Flash (1 Hz, 50% duty cycle)" 7 "Not Available" 1 "On" 3 "Fast Flash (2 HZ or faster, 50% Duty Cycle)" 0 "Off" 6 "Error" ;
VAL_ 2566860288 pHot_Lamp_Status 2 "Slow Flash (1 Hz, 50% duty cycle)" 7 "Not Available" 1 "On" 3 "Fast Flash (2 HZ or faster, 50% Duty Cycle)" 0 "Off" 6 "Error" ;
VAL_ 2566860288 pHigh_Beam_Status 2 "Slow Flash (1 Hz, 50% duty cycle)" 7 "Not Available" 1 "On" 3 "Fast Flash (2 HZ or faster, 50% Duty Cycle)" 0 "Off" 6 "Error" ;
VAL_ 2566865664 pASL_Enable 2 "Error" 0 "Off" 1 "On" 3 "Not-Available" ;
VAL_ 2566865664 pASL_Speed_Decrement 2 "Error" 0 "Off" 1 "On" 3 "Not-Available" ;
VAL_ 2566865664 pASL_Speed_Increment 2 "Error" 0 "Off" 1 "On" 3 "Not-Available" ;
VAL_ 2432656640 Key_Fob_Unlock_Button_Status 2 "Error" 0 "Off" 1 "On" 3 "Not-Available" ;
VAL_ 2432656640 Homelink_2 2 "Error" 0 "Off" 1 "On" 3 "Not-Available" ;
VAL_ 2432656640 Side_Stand_Switch 2 "Error" 0 "Off" 1 "On" 3 "Not-Available" ;
VAL_ 2432656640 Key_Fob_Lock_Button_Status 2 "Error" 0 "Off" 1 "On" 3 "Not-Available" ;
VAL_ 2432656640 Windshield__2_Down 2 "Error" 0 "Off" 1 "On" 3 "Not-Available" ;
VAL_ 2432656640 Turn__3_Cancel 2 "Error" 0 "Off" 1 "On" 3 "Not-Available" ;
VAL_ 2432656640 Reverse 2 "Error" 0 "Off" 1 "On" 3 "Not-Available" ;
VAL_ 2432656640 Hazard 2 "Error" 0 "Off" 1 "On" 3 "Not-Available" ;
VAL_ 2432656640 Homelink_1 2 "Error" 0 "Off" 1 "On" 3 "Not-Available" ;
VAL_ 2432656640 Windshield__1_Up 2 "Error" 0 "Off" 1 "On" 3 "Not-Available" ;
VAL_ 2432656640 Front_Brake_Switch 2 "Error" 0 "Off" 1 "On" 3 "Not-Available" ;
VAL_ 2432656640 Instrument_Cluster_Control__2 2 "Error" 0 "Off" 1 "On" 3 "Not-Available" ;
VAL_ 2432656640 Chassis_Unlock_Button_Status 2 "Error" 0 "Off" 1 "On" 3 "Not-Available" ;
VAL_ 2432656640 Power_Button 2 "Error" 0 "Off" 1 "On" 3 "Not-Available" ;
VAL_ 2432656640 RunStop_Switch 2 "Error" 0 "Off" 1 "On" 3 "Not-Available" ;
VAL_ 2432656640 Headlamp__2_High 2 "Error" 0 "Off" 1 "On" 3 "Not-Available" ;
VAL_ 2432656640 Instrument_Cluster_Control__1 2 "Error" 0 "Off" 1 "On" 3 "Not-Available" ;
VAL_ 2432656640 Clutch_Switch 2 "Error" 0 "Off" 1 "On" 3 "Not-Available" ;
VAL_ 2432656640 Start 2 "Error" 0 "Off" 1 "On" 3 "Not-Available" ;
VAL_ 2432656640 Headlamp__3_Driving 2 "Error" 0 "Off" 1 "On" 3 "Not-Available" ;
VAL_ 2432656640 Cruise__2_Set 2 "Error" 0 "Off" 1 "On" 3 "Not-Available" ;
VAL_ 2432656640 Windshield_Wiper 2 "Error" 0 "Off" 1 "On" 3 "Not-Available" ;
VAL_ 2432656640 Fog 2 "Error" 0 "Off" 1 "On" 3 "Not-Available" ;
VAL_ 2432656640 Cruise__3_Accel 2 "Error" 0 "Off" 1 "On" 3 "Not-Available" ;
VAL_ 2432656640 Horn 2 "Error" 0 "Off" 1 "On" 3 "Not-Available" ;
VAL_ 2432656640 Turn__2_Right 2 "Error" 0 "Off" 1 "On" 3 "Not-Available" ;
VAL_ 2432656640 Cruise__1_On 2 "Error" 0 "Off" 1 "On" 3 "Not-Available" ;
VAL_ 2432656640 Turn__1_Left 2 "Error" 0 "Off" 1 "On" 3 "Not-Available" ;
VAL_ 2432656640 Throttle_Safety_Switch__1 2 "Error" 0 "Off" 1 "On" 3 "Not-Available" ;
VAL_ 2432656640 Headlamp__1_Low 2 "Error" 0 "Off" 1 "On" 3 "Not-Available" ;
VAL_ 2432656640 Fuel_Door_Unlock_Button_Status 2 "Error Indicator" 3 "Not Available" 1 "Button pressed" 0 "Button not pressed" ;
VAL_ 2566876416 pEngine_Brake_Active 2 "Error" 0 "Off" 1 "On" 3 "Not-Available" ;
VAL_ 2566876416 pFoot_On_Cruise_Enable 2 "Error" 0 "Off" 1 "On" 3 "Not-Available" ;
VAL_ 2566876416 pFarm_Mode_Speed_Decrement 2 "Error" 0 "Off" 1 "On" 3 "Not-Available" ;
VAL_ 2566876416 pEngine_Brake_Enabled 2 "Error" 0 "Off" 1 "On" 3 "Not-Available" ;
VAL_ 2566876416 pCylDeAc_Enabled 2 "Error" 0 "Off" 1 "On" 3 "Not-Available" ;
VAL_ 2566876416 pFarm_Mode_Speed_Increment 2 "Error" 0 "Off" 1 "On" 3 "Not-Available" ;
VAL_ 2566876416 pCylDeAc_Active 2 "Error" 0 "Off" 1 "On" 3 "Not-Available" ;
VAL_ 2633984768 pFuel_Economy_Data_Source 0 "ECM to calculate" 2 "Error Indicator" 3 "Not Available" 1 "Gauge to calculate" ;
VAL_ 2633984768 pActive_Decent_Control_ADC_Mode_ 2 "Error" 0 "Off" 1 "On" 3 "Not-Available" ;
VAL_ 2633984768 pFuel_Level_Data_Source 0 "Analog" 3 "Not Available " 1 "CAN" 2 "Error" ;
VAL_ 2633984768 pVehicle_Units_Configuration 0 "US12: MPH, Fahrenheit, US Gallon, 12-Hour Clock, & PSI" 2 "INT12: km/h, Celsius, Liter, 12-Hour Clock, & kPa" 1 "US24: MPH, Fahrenheit, US Gallon, 24-Hour Clock, & PSI" 5 " UK24: MPH, Celsius, Imperial Gallon, 24-Hour Clock, & PSI" 14 "Error" 7 "Not Available" 3 "INT24: km/h, Celsius, Liter, 24-Hour Clock, & kPa" 4 "UK12: MPH, Celsius, Imperial Gallon, 12-Hour Clock, & PSI" ;
VAL_ 2633984768 pSeat_Belt_Input_Source 1 "Gauge to read switch input" 0 "ECM to read switch input" 3 "Not Available" 2 "Error" ;
VAL_ 2633984768 pAWD_Mode_Availability 2 "Error" 0 "Off" 1 "On" 3 "Not-Available" ;
VAL_ 2633984768 pTurf_Mode_Availability 2 "Error" 0 "Off" 1 "On" 3 "Not-Available" ;
VAL_ 2432658432 Drive_Mode__4 2 "Error" 0 "Off" 1 "On" 3 "Not-Available" ;
VAL_ 2432658432 Drive_Mode__2 2 "Error" 0 "Off" 1 "On" 3 "Not-Available" ;
VAL_ 2432658432 Drivers_Net_Engagement 2 "Error" 0 "Off" 1 "On" 3 "Not-Available" ;
VAL_ 2432658432 Foot_On_Cruise_Control_Switch 2 "Error" 0 "Off" 1 "On" 3 "Not-Available" ;
VAL_ 2432658432 Drive_Mode__1 2 "Error" 0 "Off" 1 "On" 3 "Not-Available" ;
VAL_ 2432658432 Momentary_Driveline_Left_Press 2 "Error" 0 "Off" 1 "On" 3 "Not-Available" ;
VAL_ 2432658432 CylDeAc_Enable 2 "Error" 0 "Off" 1 "On" 3 "Not-Available" ;
VAL_ 2432658432 Work_Group_Lock_Switch 2 "Error" 0 "Off" 1 "On" 3 "Not-Available" ;
VAL_ 2432658432 Drivers_Seatbelt_Engagement 2 "Error" 0 "Off" 1 "On" 3 "Not-Available" ;
VAL_ 2432658432 Drive_Mode__3 2 "Error" 0 "Off" 1 "On" 3 "Not-Available" ;
VAL_ 2432658432 Work_Mode_Switch 2 "Error" 0 "Off" 1 "On" 3 "Not-Available" ;
VAL_ 2432658432 Momentary_Driveline_Right_Press 2 "Error" 0 "Off" 1 "On" 3 "Not-Available" ;
VAL_ 2432658432 PTO_Mode_Switch_RPM_Control 2 "Error" 0 "Off" 1 "On" 3 "Not-Available" ;
VAL_ 2432658432 Operator_Presence_Switch 2 "Error" 0 "Off" 1 "On" 3 "Not-Available" ;
VAL_ 2432658432 Tilt_Lock_Switch 2 "Error" 0 "Off" 1 "On" 3 "Not-Available" ;
VAL_ 2432658432 Engine_Brake_Enable 2 "Error" 0 "Off" 1 "On" 3 "Not-Available" ;
VAL_ 2432658432 Accessory_Relay 0 "Energize" 1 "De-energize" 3 "Not Available" ;
VAL_ 2633984512 pHeated_Grip_Enable 2 "Error" 0 "Off" 1 "On" 3 "Not-Available" ;
VAL_ 2633984512 pUser_PIN_Access_Status 2 "Error" 0 "Off" 1 "On" 3 "Not-Available" ;
VAL_ 2633984512 pActive_Descent_Control_ADC_Stat 2 "Error" 0 "Off" 1 "On" 3 "Not-Available" ;
VAL_ 2633984512 pCruise_Control_Set_Status 2 "Error" 0 "Off" 1 "On" 3 "Not-Available" ;
VAL_ 2633984512 pTether_Switch_Status 2 "Error" 0 "Off" 1 "On" 3 "Not-Available" ;
VAL_ 2633984512 pHigh_Beam_Indicator_Status 2 "Error" 0 "Off" 1 "On" 3 "Not-Available" ;
VAL_ 2633984512 pLow_Fuel_Indicator_Status 2 "Error" 0 "Off" 1 "On" 3 "Not-Available" ;
VAL_ 2633984512 pSide_Stand_Status 2 "Error" 1 "Side Stand Extended" 0 "Side Stand Retracted" 3 "Not Available" ;
VAL_ 2633984512 pTurf_Mode_Requested 2 "Error" 0 "Off" 1 "On" 3 "Not-Available" ;
VAL_ 2633984512 Operator_Not_in_Operating_Statio 2 "Error" 0 "Off" 1 "On" 3 "Not-Available" ;
VAL_ 2633984512 pAWD_Mode_Requested 2 "Error" 0 "Off" 1 "On" 3 "Not-Available" ;
VAL_ 2633984512 pHeated_Grips_Up_Switch_Status 2 "Error" 0 "Off" 1 "On" 3 "Not-Available" ;
VAL_ 2633984512 pTreadle_Neutral_Status 2 "Error" 0 "Off" 1 "On" 3 "Not-Available" ;
VAL_ 2633984512 pHeated_Grips_Down_Switch_Status 2 "Error" 0 "Off" 1 "On" 3 "Not-Available" ;
VAL_ 2633984512 pPark_Brake_Indicator_Status 2 "Slow Flash (1 Hz, 50% duty cycle)" 7 "Not Available" 1 "On" 3 "Fast Flash (2 HZ or faster, 50% Duty Cycle)" 0 "Off" 6 "Error" ;
VAL_ 2633984512 pRWD_Mode_Requested 2 "Error" 0 "Off" 1 "On" 3 "Not-Available" ;
VAL_ 2633984512 pSeat_Belt_Indicator_Status 2 "Slow Flash (1 Hz, 50% duty cycle)" 7 "Not Available" 1 "On" 3 "Fast Flash (2 HZ or faster, 50% Duty Cycle)" 0 "Off" 6 "Error" ;
VAL_ 2633984512 pSecurity_Light_Immobilizer_Stat 2 "Error" 0 "Off" 1 "On" 3 "Not-Available" ;
VAL_ 2633984512 ECU_Security_Status 1 "Locked, Awaiting Unlock" 3 " Locked, system will shut down" 0 "Unlocked" 7 "Not Available" 2 "Locked, System will not shut down" 6 "Error" ;
VAL_ 2633984512 pActive_Decent_Control_ADC_Mode_ 2 "Error" 0 "Off" 1 "On" 3 "Not-Available" ;
VAL_ 2633984512 pTreadle_Reverse_Status 2 "Error" 0 "Off" 1 "On" 3 "Not-Available" ;
VAL_ 2566875136 pFuel_Type_Selected 6 "Fuel Type 1 (E85)" 1 "Fuel Type 2 (E5)" 2 "Fuel Type 3 (E7)" 7 "Fuel Type 1 (E95)" 3 "Fuel Type 4 (E10)" 15 "Not Available" 8 "Fuel Type 1 (E100)" 0 "Fuel Type 1 (E0)" 14 "Error" 4 "Fuel Type 1 (E15)" 5 "Fuel Type 1 (E20)" ;
VAL_ 2365548032 pCruiseControlStates 2 "Accelerate" 3 "Decelerate" 6 "Accelerator Override" 0 "Off/Disabled" 7 "Not Available " 4 "Resume" 1 "Hold" 5 "Set" ;
VAL_ 2365548032 pStuck_Throttle 2 "Error" 0 "Off" 1 "On" 3 "Not-Available" ;
VAL_ 2365548032 pHigh_Idle_State 2 "Error" 0 "Off" 1 "On" 3 "Not-Available" ;
VAL_ 2566876672 pHydraulic_Oil_Temp_Status 0 "Error" 1 "OK" 2 "Not OK" 3 "Not Available" ;
VAL_ 2566876672 pHydraulic_Oil_Pressure_Status 0 "Error" 1 "OK" 2 "Not OK" 3 "Not Available" ;
VAL_ 2566876672 pEngine_Oil_Pressure_Status 0 "Error" 1 "OK" 2 "Not OK" 3 "Not Available" ;
